VERSION ""

NS_ :

BS_:

BU_: DSAU vHS_M SHVU_RR DPSS AMP ICC RLPSM APSM RWPC RRHV RRPSM CGW_CCU APSS ATS RLHV FPM RDC PSM ASAU

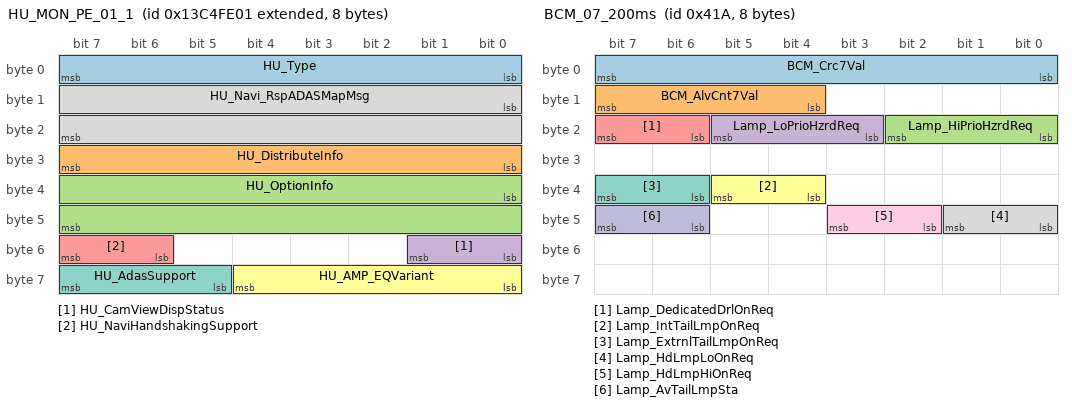
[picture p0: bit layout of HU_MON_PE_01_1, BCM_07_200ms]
BO_ 2479160833 HU_MON_PE_01_1: 8 CGW_CCU
 SG_ HU_Type : 0|8@1+ (1,0) [0|0] ""  AMP
 SG_ HU_DistributeInfo : 24|8@1+ (1,0) [0|0] ""  AMP
 SG_ HU_OptionInfo : 32|16@1+ (1,0) [0|0] ""  AMP
 SG_ HU_CamViewDispStatus : 48|2@1+ (1,0) [0|0] ""  Vector__XXX
 SG_ HU_NaviHandshakingSupport : 54|2@1+ (1,0) [0|0] ""  Vector__XXX
 SG_ HU_AMP_EQVariant : 56|5@1+ (1,0) [0|0] ""  AMP
 SG_ HU_AdasSupport : 61|3@1+ (1,0) [0|0] ""  Vector__XXX
 SG_ HU_Navi_RspADASMapMsg : 8|16@1+ (1,0) [0|0] ""  Vector__XXX

BO_ 2458165761 HU_GW_E_02_1: 8 CGW_CCU
 SG_ C_HazardFromIBOX : 1|1@1+ (1,0) [0|0] ""  Vector__XXX
 SG_ C_RemoteWdwCMDHU : 16|2@1+ (1,0) [0|0] ""  Vector__XXX
 SG_ C_EsyAcsProfileID_HU : 18|2@1+ (1,0) [0|0] ""  PSM
 SG_ C_TeleStrgWhlHeatingCmdIBOX : 20|2@1+ (1,0) [0|0] ""  Vector__XXX
 SG_ C_TeleDefoggerHeatingCmdIBOX : 22|2@1+ (1,0) [0|0] ""  Vector__XXX
 SG_ HU_ICU_RearDefSet : 24|2@1+ (1,0) [0|0] ""  Vector__XXX
 SG_ C_PanicFromIBOX : 3|1@1+ (1,0) [0|0] ""  Vector__XXX
 SG_ C_PreCrankReq : 30|2@1+ (1,0) [0|0] ""  Vector__XXX
 SG_ C_TeleAstSeatOpCmdIBOX : 32|4@1+ (1,0) [0|0] ""  PSM,APSM
 SG_ C_TeleDrvSeatOpCmdIBOX : 36|4@1+ (1,0) [0|0] ""  PSM,APSM
 SG_ C_TeleRRSeatOpCmdIBOX : 40|4@1+ (1,0) [0|0] ""  RLPSM,RRPSM,RLHV,RRHV,SHVU_RR,ATS
 SG_ C_TeleRLSeatOpCmdIBOX : 44|4@1+ (1,0) [0|0] ""  RLPSM,RRPSM,RLHV,RRHV,SHVU_RR,ATS
 SG_ C_HazardFromCCS : 48|2@1+ (1,0) [0|0] ""  Vector__XXX
 SG_ C_CtrlDrUnlockRlyIBOX : 5|1@1+ (1,0) [0|0] ""  Vector__XXX
 SG_ C_PanicFromCCS : 50|2@1+ (1,0) [0|0] ""  Vector__XXX
 SG_ C_CtrlDrUnlockRlyCCS : 52|2@1+ (1,0) [0|0] ""  Vector__XXX
 SG_ C_CtrlDrLockRlyCCS : 54|2@1+ (1,0) [0|0] ""  Vector__XXX
 SG_ C_CtrlDrLockRlyIBOX : 7|1@1+ (1,0) [0|0] ""  Vector__XXX
 SG_ C_TeleHeatingCmdIBOX : 8|2@1+ (1,0) [0|0] ""  Vector__XXX

BO_ 1050 BCM_07_200ms: 8 CGW_CCU
 SG_ BCM_Crc7Val : 0|8@1+ (1,0) [0|0] ""  Vector__XXX
 SG_ BCM_AlvCnt7Val : 12|4@1+ (1,0) [0|0] ""  Vector__XXX
 SG_ Lamp_HiPrioHzrdReq : 16|3@1+ (1,0) [0|0] ""  Vector__XXX
 SG_ Lamp_LoPrioHzrdReq : 19|3@1+ (1,0) [0|0] ""  Vector__XXX
 SG_ Lamp_DedicatedDrlOnReq : 22|2@1+ (1,0) [0|0] ""  Vector__XXX
 SG_ Lamp_IntTailLmpOnReq : 36|2@1+ (1,0) [0|0] ""  RWPC
 SG_ Lamp_ExtrnlTailLmpOnReq : 38|2@1+ (1,0) [0|0] ""  Vector__XXX
 SG_ Lamp_HdLmpLoOnReq : 40|2@1+ (1,0) [0|0] ""  Vector__XXX
 SG_ Lamp_HdLmpHiOnReq : 42|2@1+ (1,0) [0|0] ""  Vector__XXX
 SG_ Lamp_AvTailLmpSta : 46|2@1+ (1,0) [0|0] ""  ATS

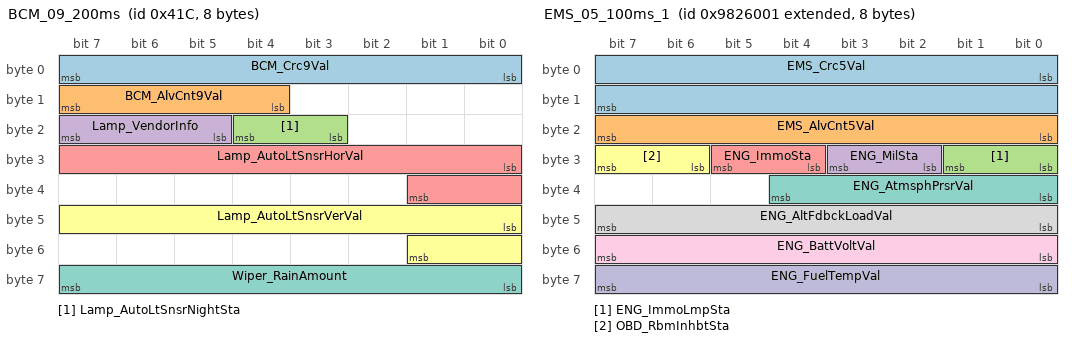
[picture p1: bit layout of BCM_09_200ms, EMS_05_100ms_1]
BO_ 1052 BCM_09_200ms: 8 CGW_CCU
 SG_ BCM_Crc9Val : 0|8@1+ (1,0) [0|0] ""  Vector__XXX
 SG_ BCM_AlvCnt9Val : 12|4@1+ (1,0) [0|0] ""  Vector__XXX
 SG_ Lamp_AutoLtSnsrNightSta : 19|2@1+ (1,0) [0|0] ""  ATS
 SG_ Lamp_VendorInfo : 21|3@1+ (1,0) [0|0] ""  Vector__XXX
 SG_ Lamp_AutoLtSnsrHorVal : 24|10@1+ (1,0) [0|0] ""  ATS
 SG_ Lamp_AutoLtSnsrVerVal : 40|10@1+ (1,0) [0|0] ""  Vector__XXX
 SG_ Wiper_RainAmount : 56|8@1+ (0.5,0) [0|0] ""  Vector__XXX

BO_ 2307022849 EMS_05_100ms_1: 8 CGW_CCU
 SG_ EMS_Crc5Val : 0|16@1+ (1,0) [0|0] ""  Vector__XXX
 SG_ EMS_AlvCnt5Val : 16|8@1+ (1,0) [0|0] ""  Vector__XXX
 SG_ ENG_ImmoLmpSta : 24|2@1+ (1,0) [0|0] ""  Vector__XXX
 SG_ ENG_MilSta : 26|2@1+ (1,0) [0|0] ""  Vector__XXX
 SG_ ENG_ImmoSta : 28|2@1+ (1,0) [0|0] ""  Vector__XXX
 SG_ OBD_RbmInhbtSta : 30|2@1+ (1,0) [0|0] ""  Vector__XXX
 SG_ ENG_AtmsphPrsrVal : 32|5@1+ (10.731613,458.98) [0|0] "mmHg"  Vector__XXX
 SG_ ENG_AltFdbckLoadVal : 40|8@1+ (0.4,0) [0|0] "%"  Vector__XXX
 SG_ ENG_BattVoltVal : 48|8@1+ (0.1015625,0) [0|0] "V"  Vector__XXX
 SG_ ENG_FuelTempVal : 56|8@1+ (0.75,-48) [0|0] "℃"  Vector__XXX

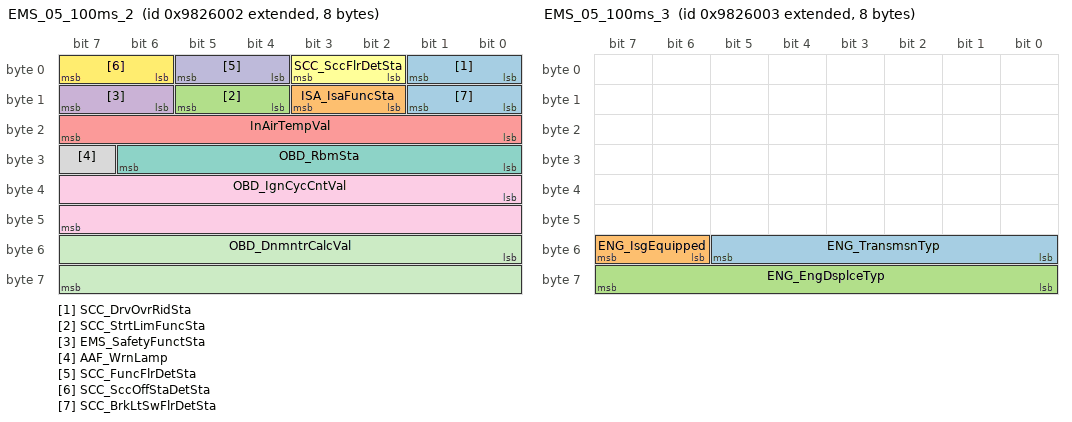
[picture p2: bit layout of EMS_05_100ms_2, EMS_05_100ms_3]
BO_ 2307022850 EMS_05_100ms_2: 8 CGW_CCU
 SG_ SCC_DrvOvrRidSta : 0|2@1+ (1,0) [0|0] ""  Vector__XXX
 SG_ ISA_IsaFuncSta : 10|2@1+ (1,0) [0|0] ""  Vector__XXX
 SG_ SCC_StrtLimFuncSta : 12|2@1+ (1,0) [0|0] ""  Vector__XXX
 SG_ EMS_SafetyFunctSta : 14|2@1+ (1,0) [0|0] ""  Vector__XXX
 SG_ InAirTempVal : 16|8@1+ (0.75,-48) [0|0] "℃"  Vector__XXX
 SG_ SCC_SccFlrDetSta : 2|2@1+ (1,0) [0|0] ""  Vector__XXX
 SG_ OBD_RbmSta : 24|7@1+ (1,0) [0|0] ""  Vector__XXX
 SG_ AAF_WrnLamp : 31|1@1+ (1,0) [0|0] ""  Vector__XXX
 SG_ OBD_IgnCycCntVal : 32|16@1+ (1,0) [0|0] ""  Vector__XXX
 SG_ SCC_FuncFlrDetSta : 4|2@1+ (1,0) [0|0] ""  Vector__XXX
 SG_ OBD_DnmntrCalcVal : 48|16@1+ (1,0) [0|0] ""  Vector__XXX
 SG_ SCC_SccOffStaDetSta : 6|2@1+ (1,0) [0|0] ""  Vector__XXX
 SG_ SCC_BrkLtSwFlrDetSta : 8|2@1+ (1,0) [0|0] ""  Vector__XXX

BO_ 2307022851 EMS_05_100ms_3: 8 CGW_CCU
 SG_ ENG_TransmsnTyp : 48|6@1+ (1,0) [0|0] ""  Vector__XXX
 SG_ ENG_IsgEquipped : 54|2@1+ (1,0) [0|0] ""  Vector__XXX
 SG_ ENG_EngDsplceTyp : 56|8@1+ (0.1,0) [0|0] "liter"  AMP

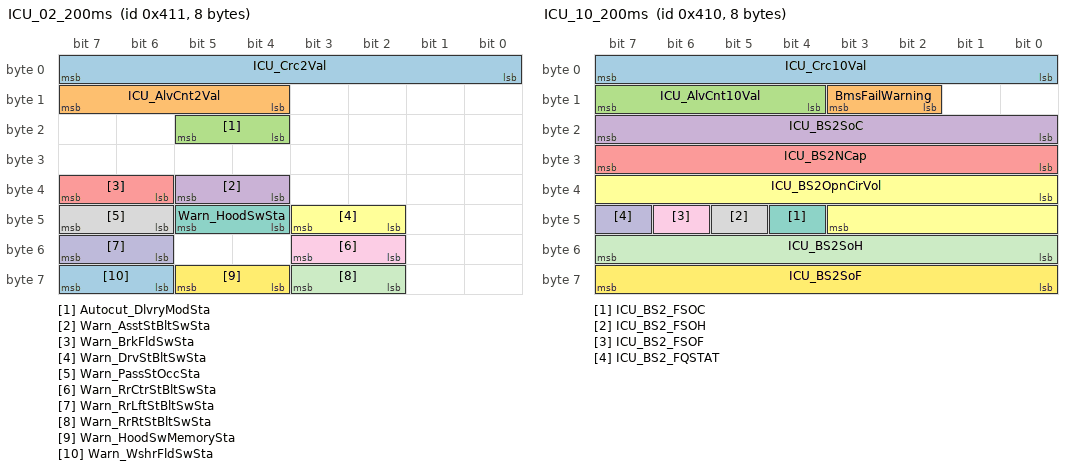
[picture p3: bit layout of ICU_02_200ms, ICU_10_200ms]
BO_ 1041 ICU_02_200ms: 8 CGW_CCU
 SG_ ICU_Crc2Val : 0|8@1+ (1,0) [0|0] ""  vHS_M
 SG_ ICU_AlvCnt2Val : 12|4@1+ (1,0) [0|0] ""  Vector__XXX
 SG_ Autocut_DlvryModSta : 20|2@1+ (1,0) [0|0] ""  Vector__XXX
 SG_ Warn_AsstStBltSwSta : 36|2@1+ (1,0) [0|0] ""  APSM,RLPSM,RRPSM,ASAU
 SG_ Warn_BrkFldSwSta : 38|2@1+ (1,0) [0|0] ""  Vector__XXX
 SG_ Warn_DrvStBltSwSta : 42|2@1+ (1,0) [0|0] ""  ATS,DSAU,ASAU
 SG_ Warn_HoodSwSta : 44|2@1+ (1,0) [0|0] ""  Vector__XXX
 SG_ Warn_PassStOccSta : 46|2@1+ (1,0) [0|0] ""  APSM
 SG_ Warn_RrCtrStBltSwSta : 50|2@1+ (1,0) [0|0] ""  Vector__XXX
 SG_ Warn_RrLftStBltSwSta : 54|2@1+ (1,0) [0|0] ""  RLPSM,RRPSM
 SG_ Warn_RrRtStBltSwSta : 58|2@1+ (1,0) [0|0] ""  RLPSM,RRPSM
 SG_ Warn_HoodSwMemorySta : 60|2@1+ (1,0) [0|0] ""  Vector__XXX
 SG_ Warn_WshrFldSwSta : 62|2@1+ (1,0) [0|0] ""  Vector__XXX

BO_ 1040 ICU_10_200ms: 8 CGW_CCU
 SG_ ICU_Crc10Val : 0|8@1+ (1,0) [0|0] ""  vHS_M
 SG_ BmsFailWarning : 10|2@1+ (1,0) [0|0] ""  Vector__XXX
 SG_ ICU_AlvCnt10Val : 12|4@1+ (1,0) [0|0] ""  Vector__XXX
 SG_ ICU_BS2SoC : 16|8@1+ (1,0) [0|0] ""  AMP
 SG_ ICU_BS2NCap : 24|8@1+ (1,0) [0|0] ""  Vector__XXX
 SG_ ICU_BS2OpnCirVol : 32|12@1+ (0.001,10) [0|0] ""  Vector__XXX
 SG_ ICU_BS2_FSOC : 44|1@1+ (1,0) [0|0] ""  Vector__XXX
 SG_ ICU_BS2_FSOH : 45|1@1+ (1,0) [0|0] ""  Vector__XXX
 SG_ ICU_BS2_FSOF : 46|1@1+ (1,0) [0|0] ""  Vector__XXX
 SG_ ICU_BS2_FQSTAT : 47|1@1+ (1,0) [0|0] ""  Vector__XXX
 SG_ ICU_BS2SoH : 48|8@1+ (1,0) [0|0] ""  Vector__XXX
 SG_ ICU_BS2SoF : 56|8@1+ (0.05,0) [0|0] ""  Vector__XXX

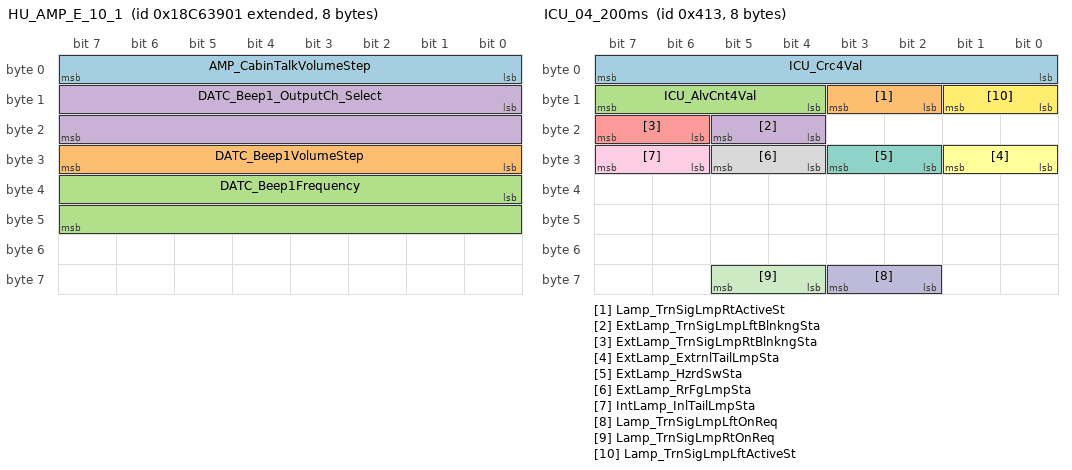
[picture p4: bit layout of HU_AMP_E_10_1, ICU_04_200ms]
BO_ 2563127553 HU_AMP_E_10_1: 8 CGW_CCU
 SG_ AMP_CabinTalkVolumeStep : 0|8@1+ (1,0) [0|0] ""  Vector__XXX
 SG_ DATC_Beep1VolumeStep : 24|8@1+ (1,0) [0|0] ""  AMP
 SG_ DATC_Beep1Frequency : 32|16@1+ (1,0) [0|0] "Hz"  AMP
 SG_ DATC_Beep1_OutputCh_Select : 8|16@1+ (1,0) [0|0] ""  AMP

BO_ 1043 ICU_04_200ms: 8 CGW_CCU
 SG_ ICU_Crc4Val : 0|8@1+ (1,0) [0|0] ""  vHS_M
 SG_ Lamp_TrnSigLmpRtActiveSt : 10|2@1+ (1,0) [0|0] ""  Vector__XXX
 SG_ ICU_AlvCnt4Val : 12|4@1+ (1,0) [0|0] ""  Vector__XXX
 SG_ ExtLamp_TrnSigLmpLftBlnkngSta : 20|2@1+ (1,0) [0|0] ""  Vector__XXX
 SG_ ExtLamp_TrnSigLmpRtBlnkngSta : 22|2@1+ (1,0) [0|0] ""  Vector__XXX
 SG_ ExtLamp_ExtrnlTailLmpSta : 24|2@1+ (1,0) [0|0] ""  Vector__XXX
 SG_ ExtLamp_HzrdSwSta : 26|2@1+ (1,0) [0|0] ""  ICC
 SG_ ExtLamp_RrFgLmpSta : 28|2@1+ (1,0) [0|0] ""  Vector__XXX
 SG_ IntLamp_InlTailLmpSta : 30|2@1+ (1,0) [0|0] ""  Vector__XXX
 SG_ Lamp_TrnSigLmpLftOnReq : 58|2@1+ (1,0) [0|0] ""  Vector__XXX
 SG_ Lamp_TrnSigLmpRtOnReq : 60|2@1+ (1,0) [0|0] ""  Vector__XXX
 SG_ Lamp_TrnSigLmpLftActiveSt : 8|2@1+ (1,0) [0|0] ""  Vector__XXX

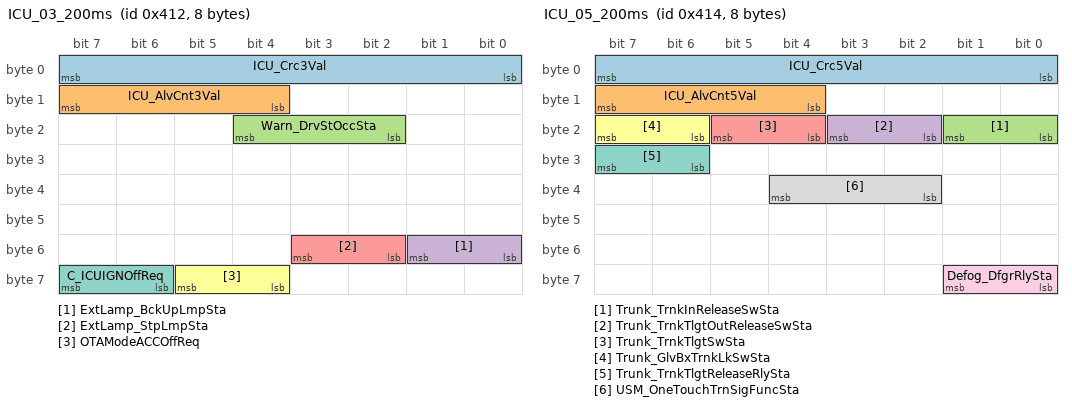
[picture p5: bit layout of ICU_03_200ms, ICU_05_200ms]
BO_ 1042 ICU_03_200ms: 8 CGW_CCU
 SG_ ICU_Crc3Val : 0|8@1+ (1,0) [0|0] ""  vHS_M
 SG_ ICU_AlvCnt3Val : 12|4@1+ (1,0) [0|0] ""  Vector__XXX
 SG_ Warn_DrvStOccSta : 18|3@1+ (1,0) [0|0] ""  Vector__XXX
 SG_ ExtLamp_BckUpLmpSta : 48|2@1+ (1,0) [0|0] ""  Vector__XXX
 SG_ ExtLamp_StpLmpSta : 50|2@1+ (1,0) [0|0] ""  Vector__XXX
 SG_ OTAModeACCOffReq : 60|2@1+ (1,0) [0|0] ""  Vector__XXX
 SG_ C_ICUIGNOffReq : 62|2@1+ (1,0) [0|0] ""  Vector__XXX

BO_ 639 ATS_04_00ms: 8 ATS
 SG_ ATS_RLSeatHeaterUpSW : 10|2@1+ (1,0) [0|0] ""  RLHV,RLPSM,RRHV,RRPSM
 SG_ ATS_RRSeatVentDownSW : 12|2@1+ (1,0) [0|0] ""  RLHV,RLPSM,RRHV,RRPSM
 SG_ ATS_RLSeatVentDownSW : 14|2@1+ (1,0) [0|0] ""  RLHV,RLPSM,RRHV,RRPSM
 SG_ ATS_RLMemoryRestBtn : 16|2@1+ (1,0) [0|0] ""  PSM,RLPSM
 SG_ ATS_RLMemoryReturnBtn : 18|2@1+ (1,0) [0|0] ""  PSM,RLPSM
 SG_ ATS_RRMemoryRestBtn : 20|2@1+ (1,0) [0|0] ""  APSM,RRPSM
 SG_ ATS_RRMemoryReturnBtn : 22|2@1+ (1,0) [0|0] ""  APSM,RRPSM
 SG_ ATS_RRMemoryAvWtcBtn : 24|2@1+ (1,0) [0|0] ""  APSM,RRPSM
 SG_ ATS_RRMemoryReadingBtn : 26|2@1+ (1,0) [0|0] ""  APSM,RRPSM
 SG_ ATS_RRRestModBtnSTD : 32|2@1+ (1,0) [0|0] ""  APSM,RRPSM
 SG_ ATS_RRResetModBtnSTD : 34|2@1+ (1,0) [0|0] ""  APSM,RRPSM
 SG_ ATS_RRAvWtcModBtnSTD : 36|2@1+ (1,0) [0|0] ""  APSM,RRPSM
 SG_ ATS_RRReadingModBtnSTD : 38|2@1+ (1,0) [0|0] ""  APSM,RRPSM,CGW_CCU
 SG_ ATS_RLRestModBtnSTD : 40|2@1+ (1,0) [0|0] ""  PSM,RLPSM
 SG_ ATS_RLResetModBtnSTD : 42|2@1+ (1,0) [0|0] ""  PSM,RLPSM
 SG_ ATS_RRModestateStopBtn : 44|2@1+ (1,0) [0|0] ""  APSM,RRPSM
 SG_ ATS_RLModestateStopBtn : 46|2@1+ (1,0) [0|0] ""  PSM,RLPSM
 SG_ ATS_RLResetRestBtn : 48|2@1+ (1,0) [0|0] ""  PSM,RLPSM
 SG_ ATS_RLResetReturnBtn : 50|2@1+ (1,0) [0|0] ""  PSM,RLPSM
 SG_ ATS_RRResetRestBtn : 52|2@1+ (1,0) [0|0] ""  APSM,RRPSM
 SG_ ATS_RRResetReturnBtn : 54|2@1+ (1,0) [0|0] ""  APSM,RRPSM
 SG_ ATS_RRResetAvWtcBtn : 56|2@1+ (1,0) [0|0] ""  APSM,RRPSM
 SG_ ATS_RRResetReadingBtn : 58|2@1+ (1,0) [0|0] ""  APSM,RRPSM
 SG_ ATS_RRSeatHeaterUpSW : 8|2@1+ (1,0) [0|0] ""  RLHV,RLPSM,RRHV,RRPSM

BO_ 1044 ICU_05_200ms: 8 CGW_CCU
 SG_ ICU_Crc5Val : 0|8@1+ (1,0) [0|0] ""  vHS_M
 SG_ ICU_AlvCnt5Val : 12|4@1+ (1,0) [0|0] ""  Vector__XXX
 SG_ Trunk_TrnkInReleaseSwSta : 16|2@1+ (1,0) [0|0] ""  Vector__XXX
 SG_ Trunk_TrnkTlgtOutReleaseSwSta : 18|2@1+ (1,0) [0|0] ""  Vector__XXX
 SG_ Trunk_TrnkTlgtSwSta : 20|2@1+ (1,0) [0|0] ""  AMP
 SG_ Trunk_GlvBxTrnkLkSwSta : 22|2@1+ (1,0) [0|0] ""  Vector__XXX
 SG_ Trunk_TrnkTlgtReleaseRlySta : 30|2@1+ (1,0) [0|0] ""  Vector__XXX
 SG_ USM_OneTouchTrnSigFuncSta : 34|3@1+ (1,0) [0|0] ""  Vector__XXX
 SG_ Defog_DfgrRlySta : 56|2@1+ (1,0) [0|0] ""  Vector__XXX

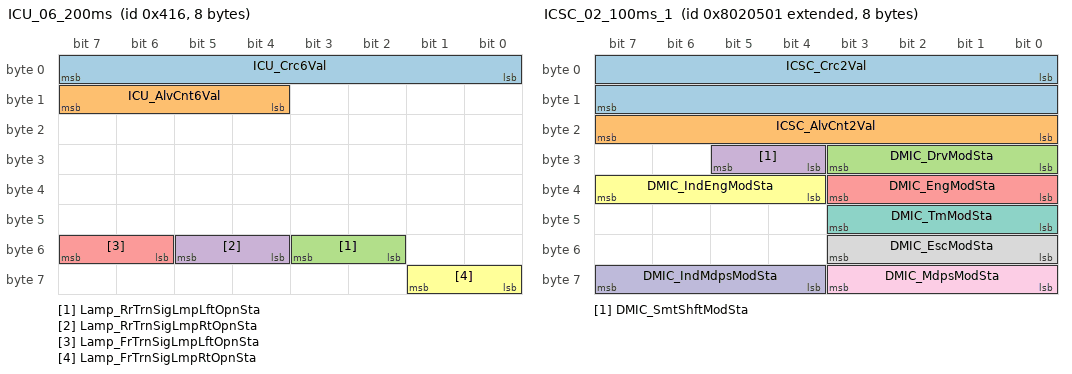
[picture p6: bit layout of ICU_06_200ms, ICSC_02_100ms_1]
BO_ 1046 ICU_06_200ms: 8 CGW_CCU
 SG_ ICU_Crc6Val : 0|8@1+ (1,0) [0|0] ""  vHS_M
 SG_ ICU_AlvCnt6Val : 12|4@1+ (1,0) [0|0] ""  Vector__XXX
 SG_ Lamp_RrTrnSigLmpLftOpnSta : 50|2@1+ (1,0) [0|0] ""  Vector__XXX
 SG_ Lamp_RrTrnSigLmpRtOpnSta : 52|2@1+ (1,0) [0|0] ""  Vector__XXX
 SG_ Lamp_FrTrnSigLmpLftOpnSta : 54|2@1+ (1,0) [0|0] ""  Vector__XXX
 SG_ Lamp_FrTrnSigLmpRtOpnSta : 56|2@1+ (1,0) [0|0] ""  Vector__XXX

BO_ 2281833729 ICSC_02_100ms_1: 8 CGW_CCU
 SG_ ICSC_Crc2Val : 0|16@1+ (1,0) [0|0] ""  Vector__XXX
 SG_ ICSC_AlvCnt2Val : 16|8@1+ (1,0) [0|0] ""  Vector__XXX
 SG_ DMIC_DrvModSta : 24|4@1+ (1,0) [0|0] ""  DSAU,ASAU
 SG_ DMIC_SmtShftModSta : 28|2@1+ (1,0) [0|0] ""  Vector__XXX
 SG_ DMIC_EngModSta : 32|4@1+ (1,0) [0|0] ""  AMP
 SG_ DMIC_IndEngModSta : 36|4@1+ (1,0) [0|0] ""  Vector__XXX
 SG_ DMIC_TmModSta : 40|4@1+ (1,0) [0|0] ""  Vector__XXX
 SG_ DMIC_EscModSta : 48|4@1+ (1,0) [0|0] ""  Vector__XXX
 SG_ DMIC_MdpsModSta : 56|4@1+ (1,0) [0|0] ""  Vector__XXX
 SG_ DMIC_IndMdpsModSta : 60|4@1+ (1,0) [0|0] ""  Vector__XXX

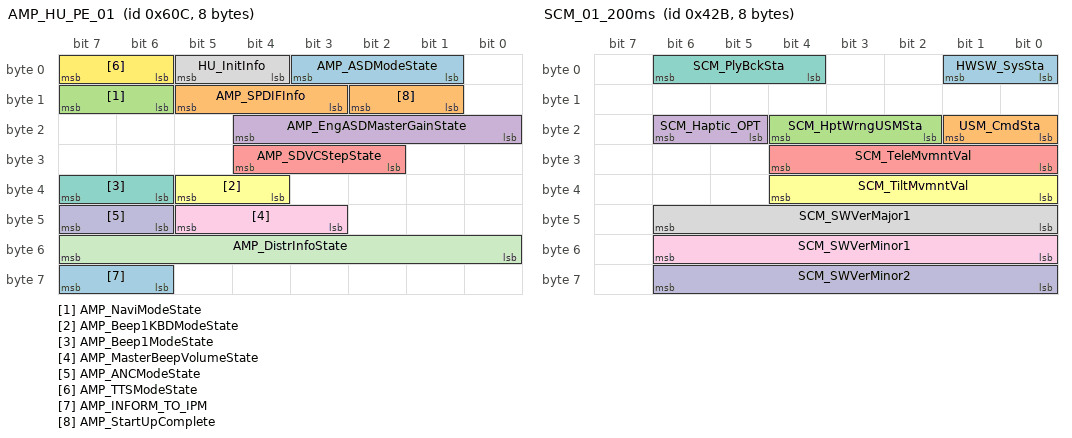
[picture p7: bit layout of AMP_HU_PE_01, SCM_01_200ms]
BO_ 1548 AMP_HU_PE_01: 8 AMP
 SG_ AMP_ASDModeState : 1|3@1+ (1,0) [0|0] ""  CGW_CCU
 SG_ AMP_SPDIFInfo : 11|3@1+ (1,0) [0|0] ""  CGW_CCU
 SG_ AMP_NaviModeState : 14|2@1+ (1,0) [0|0] ""  CGW_CCU
 SG_ AMP_EngASDMasterGainState : 16|5@1+ (0.5,-8) [-6|6] ""  CGW_CCU
 SG_ AMP_SDVCStepState : 26|3@1+ (1,0) [0|0] ""  CGW_CCU
 SG_ AMP_Beep1KBDModeState : 36|2@1+ (1,0) [0|0] ""  CGW_CCU
 SG_ AMP_Beep1ModeState : 38|2@1+ (1,0) [0|0] ""  CGW_CCU
 SG_ HU_InitInfo : 4|2@1+ (1,0) [0|0] ""  CGW_CCU
 SG_ AMP_MasterBeepVolumeState : 43|3@1+ (1,0) [0|0] ""  CGW_CCU
 SG_ AMP_ANCModeState : 46|2@1+ (1,0) [0|0] ""  CGW_CCU
 SG_ AMP_DistrInfoState : 48|8@1+ (1,0) [0|0] ""  CGW_CCU
 SG_ AMP_TTSModeState : 6|2@1+ (1,0) [0|0] ""  CGW_CCU
 SG_ AMP_INFORM_TO_IPM : 62|2@1+ (1,0) [0|0] ""  CGW_CCU
 SG_ AMP_StartUpComplete : 9|2@1+ (1,0) [0|0] ""  CGW_CCU

BO_ 1067 SCM_01_200ms: 8 CGW_CCU
 SG_ HWSW_SysSta : 0|2@1+ (1,0) [0|0] ""  Vector__XXX
 SG_ USM_CmdSta : 16|2@1+ (1,0) [0|0] ""  PSM
 SG_ SCM_HptWrngUSMSta : 18|3@1+ (1,0) [0|0] ""  Vector__XXX
 SG_ SCM_Haptic_OPT : 21|2@1+ (1,0) [0|0] ""  Vector__XXX
 SG_ SCM_TeleMvmntVal : 24|5@1+ (1,0) [0|0] "pulse count"  Vector__XXX
 SG_ SCM_TiltMvmntVal : 32|5@1+ (1,0) [0|0] "pulse count"  Vector__XXX
 SG_ SCM_PlyBckSta : 4|3@1+ (1,0) [0|0] ""  PSM
 SG_ SCM_SWVerMajor1 : 40|7@1+ (1,0) [0|0] ""  Vector__XXX
 SG_ SCM_SWVerMinor1 : 48|7@1+ (1,0) [0|0] ""  Vector__XXX
 SG_ SCM_SWVerMinor2 : 56|7@1+ (1,0) [0|0] ""  Vector__XXX

BO_ 1549 AMP_HU_PE_02: 8 AMP
 SG_ AMP_VirtualVenueModeStatus : 0|3@1+ (1,0) [0|0] ""  CGW_CCU
 SG_ AMP_EQState : 10|2@1+ (1,0) [0|0] ""  CGW_CCU
 SG_ AMP_DriverModeStatus : 12|2@1+ (1,0) [0|0] ""  CGW_CCU
 SG_ AMP_WrnPromptModeSta : 16|2@1+ (1,0) [0|0] ""  CGW_CCU
 SG_ AMP_ESEVwarning : 20|2@1+ (1,0) [0|0] ""  CGW_CCU
 SG_ AMP_SPDIFMuteSt : 22|2@1+ (1,0) [0|0] ""  CGW_CCU
 SG_ AMP_RANCwarning : 24|2@1+ (1,0) [0|0] ""  CGW_CCU
 SG_ AMP_RANCstate : 27|3@1+ (1,0) [0|0] ""  CGW_CCU
 SG_ AMP_QLIModeStatus : 3|3@1+ (1,0) [0|0] ""  CGW_CCU
 SG_ AMP_AudioSource : 32|8@1+ (1,0) [0|0] ""  CGW_CCU
 SG_ AMP_QuietModeState : 40|2@1+ (1,0) [0|0] ""  CGW_CCU
 SG_ AMP_QLSModeState : 44|2@1+ (1,0) [0|0] ""  CGW_CCU
 SG_ AMP_VoiceGuideTTSLevelStatus : 53|3@1+ (1,0) [0|0] ""  CGW_CCU
 SG_ AMP_VoiceGuideTTSStatus : 58|2@1+ (1,0) [0|0] ""  CGW_CCU
 SG_ AMP_MuteState : 6|2@1+ (1,0) [0|0] ""  CGW_CCU
 SG_ AMP_ALTPopUpStatus : 60|2@1+ (1,0) [0|0] ""  CGW_CCU
 SG_ AMP_LogSnapshotState : 8|2@1+ (1,0) [0|0] ""  CGW_CCU

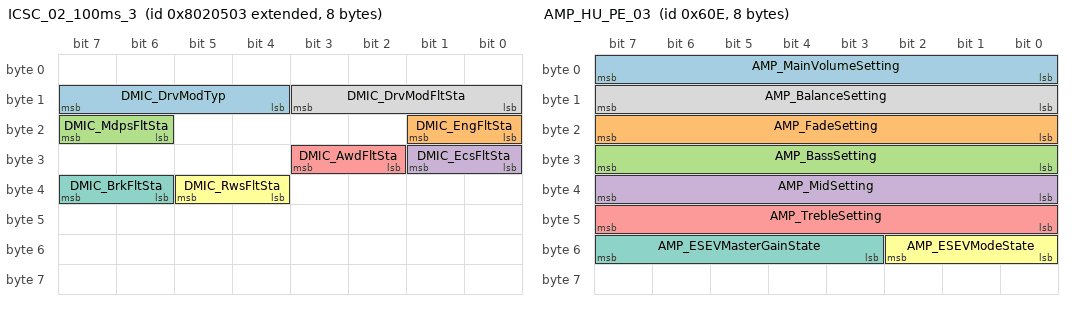
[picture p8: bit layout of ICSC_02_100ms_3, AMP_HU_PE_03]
BO_ 2281833731 ICSC_02_100ms_3: 8 CGW_CCU
 SG_ DMIC_DrvModTyp : 12|4@1+ (1,0) [0|0] ""  Vector__XXX
 SG_ DMIC_EngFltSta : 16|2@1+ (1,0) [0|0] ""  Vector__XXX
 SG_ DMIC_MdpsFltSta : 22|2@1+ (1,0) [0|0] ""  Vector__XXX
 SG_ DMIC_EcsFltSta : 24|2@1+ (1,0) [0|0] ""  Vector__XXX
 SG_ DMIC_AwdFltSta : 26|2@1+ (1,0) [0|0] ""  Vector__XXX
 SG_ DMIC_RwsFltSta : 36|2@1+ (1,0) [0|0] ""  Vector__XXX
 SG_ DMIC_BrkFltSta : 38|2@1+ (1,0) [0|0] ""  Vector__XXX
 SG_ DMIC_DrvModFltSta : 8|4@1+ (1,0) [0|0] ""  Vector__XXX

BO_ 1550 AMP_HU_PE_03: 8 AMP
 SG_ AMP_MainVolumeSetting : 0|8@1+ (1,0) [0|0] ""  CGW_CCU
 SG_ AMP_FadeSetting : 16|8@1+ (1,0) [0|0] ""  CGW_CCU
 SG_ AMP_BassSetting : 24|8@1+ (1,0) [0|0] ""  CGW_CCU
 SG_ AMP_MidSetting : 32|8@1+ (1,0) [0|0] ""  CGW_CCU
 SG_ AMP_TrebleSetting : 40|8@1+ (1,0) [0|0] ""  CGW_CCU
 SG_ AMP_ESEVModeState : 48|3@1+ (1,0) [0|0] ""  CGW_CCU
 SG_ AMP_ESEVMasterGainState : 51|5@1+ (0.5,-8) [0|0] ""  CGW_CCU
 SG_ AMP_BalanceSetting : 8|8@1+ (1,0) [0|0] ""  CGW_CCU

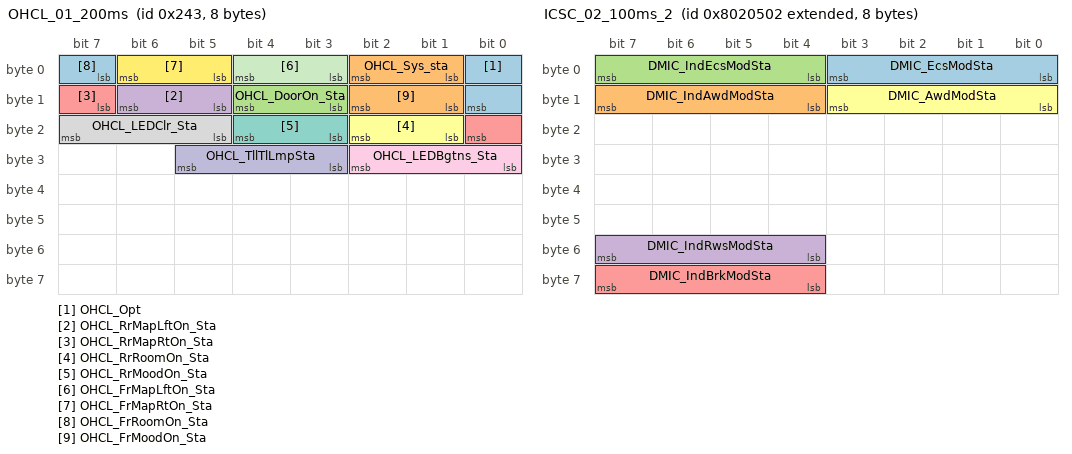
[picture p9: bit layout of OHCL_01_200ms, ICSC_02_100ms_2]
BO_ 579 OHCL_01_200ms: 8 CGW_CCU
 SG_ OHCL_Opt : 0|1@1+ (1,0) [0|0] ""  ATS
 SG_ OHCL_Sys_sta : 1|2@1+ (1,0) [0|0] ""  ATS
 SG_ OHCL_DoorOn_Sta : 11|2@1+ (1,0) [0|0] ""  ATS
 SG_ OHCL_RrMapLftOn_Sta : 13|2@1+ (1,0) [0|0] ""  ATS
 SG_ OHCL_RrMapRtOn_Sta : 15|2@1+ (1,0) [0|0] ""  ATS
 SG_ OHCL_RrRoomOn_Sta : 17|2@1+ (1,0) [0|0] ""  ATS
 SG_ OHCL_RrMoodOn_Sta : 19|2@1+ (1,0) [0|0] ""  ATS
 SG_ OHCL_LEDClr_Sta : 21|3@1+ (1,0) [0|0] ""  ATS
 SG_ OHCL_LEDBgtns_Sta : 24|3@1+ (1,0) [0|0] ""  ATS
 SG_ OHCL_TllTlLmpSta : 27|3@1+ (1,0) [0|0] ""  Vector__XXX
 SG_ OHCL_FrMapLftOn_Sta : 3|2@1+ (1,0) [0|0] ""  ATS
 SG_ OHCL_FrMapRtOn_Sta : 5|2@1+ (1,0) [0|0] ""  ATS
 SG_ OHCL_FrRoomOn_Sta : 7|2@1+ (1,0) [0|0] ""  ATS
 SG_ OHCL_FrMoodOn_Sta : 9|2@1+ (1,0) [0|0] ""  ATS

BO_ 2281833730 ICSC_02_100ms_2: 8 CGW_CCU
 SG_ DMIC_EcsModSta : 0|4@1+ (1,0) [0|0] ""  Vector__XXX
 SG_ DMIC_IndAwdModSta : 12|4@1+ (1,0) [0|0] ""  Vector__XXX
 SG_ DMIC_IndEcsModSta : 4|4@1+ (1,0) [0|0] ""  Vector__XXX
 SG_ DMIC_IndRwsModSta : 52|4@1+ (1,0) [0|0] ""  Vector__XXX
 SG_ DMIC_IndBrkModSta : 60|4@1+ (1,0) [0|0] ""  Vector__XXX
 SG_ DMIC_AwdModSta : 8|4@1+ (1,0) [0|0] ""  Vector__XXX

BO_ 1551 AMP_HU_PE_04: 8 AMP
 SG_ AMP_ADASVolumeState : 56|4@1+ (1,0) [0|0] ""  CGW_CCU

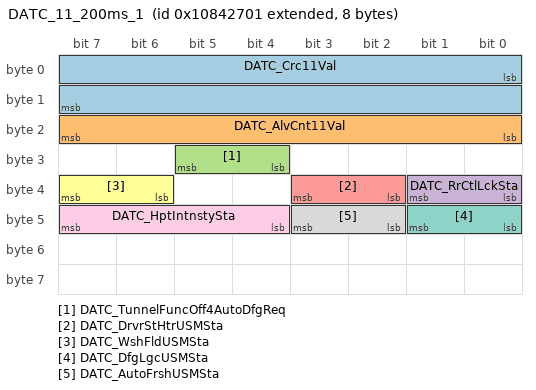
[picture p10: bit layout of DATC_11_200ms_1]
BO_ 2424579841 DATC_11_200ms_1: 8 CGW_CCU
 SG_ DATC_Crc11Val : 0|16@1+ (1,0) [0|0] ""  Vector__XXX
 SG_ DATC_AlvCnt11Val : 16|8@1+ (1,0) [0|0] ""  Vector__XXX
 SG_ DATC_TunnelFuncOff4AutoDfgReq : 28|2@1+ (1,0) [0|0] ""  Vector__XXX
 SG_ DATC_RrCtlLckSta : 32|2@1+ (1,0) [0|0] ""  ATS
 SG_ DATC_DrvrStHtrUSMSta : 34|2@1+ (1,0) [0|0] ""  SHVU_RR
 SG_ DATC_WshFldUSMSta : 38|2@1+ (1,0) [0|0] ""  Vector__XXX
 SG_ DATC_DfgLgcUSMSta : 40|2@1+ (1,0) [0|0] ""  Vector__XXX
 SG_ DATC_AutoFrshUSMSta : 42|2@1+ (1,0) [0|0] ""  Vector__XXX
 SG_ DATC_HptIntnstySta : 44|4@1+ (1,0) [0|0] ""  Vector__XXX

CM_ BO_ 1548 "[PE] Periodic and On Event";
CM_ SG_ 1548 AMP_ASDModeState "Information for current ASD(Active Sound Design, Virtual Engine Sound) Mode status
- Current AMP ASD mode is controlled by Driving Mode by itself";
CM_ SG_ 1548 AMP_SPDIFInfo "Information for SPIF output status
0x1: SPDIF PLL Unlock

0x2: PLL Lock & Null Data Received 

0x3:PLL Lock &  PCM Data Received 

0x4: PLL Lock & Compressed Data Received";
CM_ SG_ 1548 AMP_NaviModeState "Information for Current Navi Prompt Status
-Feedback from AMP_NaviMode(0x008)@H_U";
CM_ SG_ 1548 AMP_EngASDMasterGainState "Information for current ASD(Active Sound Design) Mode Status.";
CM_ SG_ 1548 AMP_SDVCStepState "Information for current SDVC(Advanced VSC) mode state";
CM_ SG_ 1548 AMP_Beep1KBDModeState "Information for Current keyboard Beep1Mode Status-Feedback from AMP_Beep1KBDMode@H_U";
CM_ SG_ 1548 AMP_Beep1ModeState "Information for Current Beep1 Mode Status(Touch Beep Mode)
For Harman AMP Only
-Feedback from AMP_Beep1Mode(0x008)@H_U";
CM_ SG_ 1548 HU_InitInfo "Information for External AMP Initiation status

0x1 : Request AMP Initialization

0x2 : AMP Initialization complted";
CM_ SG_ 1548 AMP_ANCModeState "Current ANC Mode State";
CM_ SG_ 1548 AMP_DistrInfoState "Information for current status of Region : Europe/North America/..
and Driver Position : RHD/LHD Positionning 
Feedback from HU_DistributeInfo@0x100";
CM_ SG_ 1548 AMP_TTSModeState "Information for Current TTS Prompt Status-Feedback from AMP_TTSSound(0x630)@H_U";
CM_ SG_ 1548 AMP_INFORM_TO_IPM "Information for Warning Sound Supportable for CLU";
CM_ SG_ 1548 AMP_StartUpComplete "the signal for informing intitial complete of external AMP

need for generating warning sound using external AMP";
CM_ BO_ 1549 "[PE] Periodic and On Event";
CM_ SG_ 1549 AMP_EQState "Information for current EQ loading and active state check
Harman AMP Only";
CM_ SG_ 1549 AMP_ESEVwarning "ESEV warning(Knock sensor disconnect)  at cluster and HU";
CM_ SG_ 1549 AMP_SPDIFMuteSt "Information for current SPDIF Mute state";
CM_ SG_ 1549 AMP_RANCwarning "RANC Warning at cluster & HU";
CM_ SG_ 1549 AMP_RANCstate "Information for current RANC(road active noise control) on/off status
RANC On : Window/Sunroof/Trunk/Door is close when RANC status is 'ON'
RANC Off : Window/Sunroof/Trunk/Door is close when RANC status is 'OFF'
RANC Off2 : Window/Sunroof/Trunk/Door is open when RANC status is 'ON'
RANC Off3 : Window/Sunroof/Trunk/Door is open when RANC status is 'OFF'";
CM_ SG_ 1549 AMP_AudioSource "Information for Current HF Call Audio Mode Status
-Feedback from AMP_AudioMode(0x009)@H_U";
CM_ SG_ 1549 AMP_QuietModeState "Send signal 'Quiet Mode Status' from AMP to H/U";
CM_ SG_ 1549 AMP_QLSModeState "Information for current QLS(Quantum Logic Surround) mode ON/OFF state
Harman AMP Only
For Mobis KRELL Amp, Use AMP_LiveDynamicModeState instead 
For Mobis Legacy AMP, Use AMP_SurroundModeState";
CM_ SG_ 1549 AMP_MuteState "Information for current mute state";
CM_ SG_ 1549 AMP_LogSnapshotState "Feedback for Log Snapshot touch in ENG Mode (AMP)";
CM_ BO_ 1550 "[PE] Periodic and On Event";
CM_ SG_ 1550 AMP_MainVolumeSetting "Current main audio volume setting status";
CM_ SG_ 1550 AMP_FadeSetting "Current Front/Rear audio Fader Setting status";
CM_ SG_ 1550 AMP_BassSetting "Current bass tone control setting status";
CM_ SG_ 1550 AMP_MidSetting "current midrange tone control setting status";
CM_ SG_ 1550 AMP_TrebleSetting "Current treble tone control setting status";
CM_ SG_ 1550 AMP_ESEVModeState "Feedback for ESEV Set Mode Value";
CM_ SG_ 1550 AMP_ESEVMasterGainState "Information for current ESEV(Engine Sound by Engine Vibration) Mode status.";
CM_ SG_ 1550 AMP_BalanceSetting "Current Left/Right Audio balance setting status";
CM_ BO_ 1551 "[PE] Periodic and On Event";
CM_ BO_ 639 "[EC] On Event and On Change";
CM_ SG_ 639 ATS_RLSeatHeaterUpSW "ATS touch command for seat heat control  (For Rear Left seat)";
CM_ SG_ 639 ATS_RRSeatVentDownSW "ATS touch command for seat Vent control (For Rear Right seat)";
CM_ SG_ 639 ATS_RLSeatVentDownSW "ATS touch command for seat Vent control (For Rear Left seat)";
CM_ SG_ 639 ATS_RLMemoryRestBtn "Rear Left Rest Mode Custom Save Button (Except North America)";
CM_ SG_ 639 ATS_RLMemoryReturnBtn "Rear Left Return Mode Custom Save Button (Except North America)";
CM_ SG_ 639 ATS_RRMemoryRestBtn "Rear Right Rest Mode Custom Save Button (Except North America)";
CM_ SG_ 639 ATS_RRMemoryReturnBtn "Rear Right Return Mode Custom Save Button (Except North America)";
CM_ SG_ 639 ATS_RRMemoryAvWtcBtn "Rear Right AV Watching Mode Custom Save Button (Except North America)";
CM_ SG_ 639 ATS_RRMemoryReadingBtn "Rear Right Reading Mode Custom Save Button (Except North America)";
CM_ SG_ 639 ATS_RRRestModBtnSTD "Rear Right Rest Mode Touch Button (EXCEPT North America)";
CM_ SG_ 639 ATS_RRResetModBtnSTD "Rear Right Return Mode Touch Button (EXCEPT North America)";
CM_ SG_ 639 ATS_RRAvWtcModBtnSTD "Rear Right AV Watching Mode Touch Button (EXCEPT North America)";
CM_ SG_ 639 ATS_RRReadingModBtnSTD "Rear Right Reading Mode Touch Button (EXCEPT North America)";
CM_ SG_ 639 ATS_RLRestModBtnSTD "Rear Left Rest Mode Touch Button (EXCEPT North America)";
CM_ SG_ 639 ATS_RLResetModBtnSTD "Rear Left Return Mode Touch Button (EXCEPT North America)";
CM_ SG_ 639 ATS_RRModestateStopBtn "Rear Right One touch mode Stop Button";
CM_ SG_ 639 ATS_RLModestateStopBtn "Rear Left One touch mode Stop Button";
CM_ SG_ 639 ATS_RLResetRestBtn "Rear Left Rest Mode Custom Initialization Button (Except North America)";
CM_ SG_ 639 ATS_RLResetReturnBtn "Rear Left Return Mode Custom Initialization Button (Except North America)";
CM_ SG_ 639 ATS_RRResetRestBtn "Rear Right Rest Mode Custom Initialization Button (Except North America)";
CM_ SG_ 639 ATS_RRResetReturnBtn "Rear Right Return Mode Custom Initialization Button (Except North America)";
CM_ SG_ 639 ATS_RRResetAvWtcBtn "Rear Right AV Watching Mode Custom Initialization Button (Except North America)";
CM_ SG_ 639 ATS_RRResetReadingBtn "Rear Right Reading Mode Custom Initialization Button (Except North America)";
CM_ SG_ 639 ATS_RRSeatHeaterUpSW "ATS touch command for seat heat control  (For Rear Right seat)";
CM_ BO_ 1050 "[PE] Periodic and On Event";
CM_ SG_ 1050 BCM_Crc7Val "BCM_CyclicRedundancyCheck7Value";
CM_ SG_ 1050 BCM_AlvCnt7Val "BCM_AliveCounter7Value";
CM_ SG_ 1050 Lamp_HiPrioHzrdReq "Lamp_HighPriorityHazardRequest ##2G##BCM - BCMmsg19 - C_HazardFromBCMHigh";
CM_ SG_ 1050 Lamp_LoPrioHzrdReq "Lamp_LowPriorityHazardStatus ##2G##BCM - BCMmsg19 - C_HazardfromBCMLow";
CM_ SG_ 1050 Lamp_DedicatedDrlOnReq "Lamp_DedicatedDrlOnRequest ##2G##BCM - BCMmsg19 - C_DedicatedDRLOn";
CM_ SG_ 1050 Lamp_IntTailLmpOnReq "Lamp_InternalTailLampOnRequest ##2G##BCM - BCMmsg19 - C_IntTailOn";
CM_ SG_ 1050 Lamp_ExtrnlTailLmpOnReq "Lamp_ExternalTailLampOnRequest ##2G##BCM - BCMmsg19 - C_ExtTailOn";
CM_ SG_ 1050 Lamp_HdLmpLoOnReq "Lamp_HeadLampLowOnRequest ##2G##BCM - BCMmsg19 - C_HLpLowOn";
CM_ SG_ 1050 Lamp_HdLmpHiOnReq "Lamp_HeadLampHighOnRequest ##2G##BCM - BCMmsg19 - C_HLpHighOn";
CM_ SG_ 1050 Lamp_AvTailLmpSta "Lamp_AvTailLampStatus ##2G##BCM - BCMmsg18 - C_AvTail";
CM_ BO_ 1052 "[PE] Periodic and On Event";
CM_ SG_ 1052 BCM_Crc9Val "BCM_CyclicRedundancyCheck9Value";
CM_ SG_ 1052 BCM_AlvCnt9Val "BCM_AliveCounter9Value";
CM_ SG_ 1052 Lamp_AutoLtSnsrNightSta "Lamp_AutoLightSensorNightStatus ##2G##BCM - BCMmsg24 - C_AutolightValue";
CM_ SG_ 1052 Lamp_AutoLtSnsrHorVal "Lamp_AutoLightSensorHorValue ##2G##BCM - BCMmsg24 - C_AutolightSensorHorState";
CM_ SG_ 1052 Lamp_AutoLtSnsrVerVal "Lamp_AutoLightSensorVerValue ##2G##BCM - BCMmsg24 - C_AutolightSensorVerState";
CM_ BO_ 2424579841 "[PE] Periodic and On Event";
CM_ SG_ 2424579841 DATC_Crc11Val "DATC_CyclicRedundancyCheck11Value";
CM_ SG_ 2424579841 DATC_AlvCnt11Val "DATC_AliveCounter11Value";
CM_ SG_ 2424579841 DATC_TunnelFuncOff4AutoDfgReq "DATC_TunnelFunctionOffForAutoDefogRequest";
CM_ SG_ 2424579841 DATC_RrCtlLckSta "Datc_RearClimateControlLockStatus";
CM_ SG_ 2424579841 DATC_DrvrStHtrUSMSta "DATC_DriverSeatHeaterUSMStatus";
CM_ SG_ 2424579841 DATC_WshFldUSMSta "DATC_WasherFulidUSMState";
CM_ SG_ 2424579841 DATC_DfgLgcUSMSta "DefLogic USM State";
CM_ SG_ 2424579841 DATC_AutoFrshUSMSta "Auto Fresh USM State";
CM_ SG_ 2424579841 DATC_HptIntnstySta "Haptic Intensity State";
CM_ BO_ 2307022849 "[P] Periodic";
CM_ SG_ 2307022849 EMS_Crc5Val "EMS_CyclicRedundancyCheck5Value";
CM_ SG_ 2307022849 EMS_AlvCnt5Val "EMS_AliveCounter5Value";
CM_ SG_ 2307022849 ENG_ImmoLmpSta "ENG_ImmobilizerLampStatus ##2G##EMS - EMS14 - IMMO_LAMP_STAT";
CM_ SG_ 2307022849 ENG_MilSta "ENG_MalfunctionIndicationLampStatus ##2G##EMS - EMS14 - L_MIL";
CM_ SG_ 2307022849 ENG_ImmoSta "ENG_ImmobilizerStatus ##2G##EMS - EMS14 - IM_STAT";
CM_ SG_ 2307022849 OBD_RbmInhbtSta "OBD_RateBasedMonitoringInhibitionStatus ##2G##EMS - EMS15 - INH_DC_OBD";
CM_ SG_ 2307022849 ENG_AtmsphPrsrVal "ENG_AtmosphericPressureValue ##2G##EMS - EMS14 - AMP_CAN";
CM_ SG_ 2307022849 ENG_AltFdbckLoadVal "ENG_AlternatorFeedbackLoadValue ##2G##EMS - EMS14 - BAT_Alt_FR_Duty";
CM_ SG_ 2307022849 ENG_BattVoltVal "ENG_BatteryVoltageValue ##2G##EMS - EMS14 - VB";
CM_ SG_ 2307022849 ENG_FuelTempVal "ENG_FuelTemperatureValue ##2G##EMS - EMS14 - TEMP_FUEL";
CM_ BO_ 2307022850 "[P] Periodic";
CM_ SG_ 2307022850 SCC_DrvOvrRidSta "SCC_DriverOverRideStatus ##2G##EMS - EMS15 - ECGPOvrd";
CM_ SG_ 2307022850 ISA_IsaFuncSta "ISA_IntelligentSpeedAssistanceFunctionStatus ##2G##EMS - EMS15 - CF_Ems_IsaAct";
CM_ SG_ 2307022850 SCC_StrtLimFuncSta "SCC_StartLimitFunctionStatus ##2G##EMS - EMS15 - CF_EMS_Start_Limitation";
CM_ SG_ 2307022850 EMS_SafetyFunctSta "SCC_SafetyFunctionStatus ##2G##EMS - EMS15 - CF_EMS_SAFETY_FUNCTION";
CM_ SG_ 2307022850 InAirTempVal "SCC_IntakeAirTemperatureValue ##2G##EMS - EMS15 - IntAirTemp";
CM_ SG_ 2307022850 SCC_SccFlrDetSta "SCC_SccFailureDetectStatus ##2G##EMS - EMS15 - QECACC";
CM_ SG_ 2307022850 OBD_RbmSta "OBD_RateBasedMonitoringStatus ##2G##EMS - EMS15 - STATE_DC_OBD";
CM_ SG_ 2307022850 OBD_IgnCycCntVal "OBD_IgnitionCycleCounterValue ##2G##EMS - EMS15 - CTR_IG_CYC_OBD";
CM_ SG_ 2307022850 SCC_FuncFlrDetSta "SCC_FunctionFailureDetectStatus ##2G##EMS - EMS15 - ECFail";
CM_ SG_ 2307022850 OBD_DnmntrCalcVal "OBD_DenominatorCalculationValue ##2G##EMS - EMS15 - CTR_CDN_OBD";
CM_ SG_ 2307022850 SCC_SccOffStaDetSta "SCC_SccOffConditionDetectStatus ##2G##EMS - EMS15 - SwitchOffCondExt";
CM_ SG_ 2307022850 SCC_BrkLtSwFlrDetSta "SCC_BrakeLightSwFailureDetectStatus ##2G##EMS - EMS15 - BLECFail";
CM_ BO_ 2307022851 "[P] Periodic";
CM_ SG_ 2307022851 ENG_TransmsnTyp "ENG_TransmissionType";
CM_ SG_ 2307022851 ENG_IsgEquipped "Information if ISG is equipped or not";
CM_ SG_ 2307022851 ENG_EngDsplceTyp "ENG_EngineDisplacementType ##2G##EMS - EMS12 - ENG_VOL";
CM_ BO_ 2563127553 "[EC] On Event and On Change";
CM_ SG_ 2563127553 AMP_CabinTalkVolumeStep "Command for CabinTalk Prompt Volume Setting
-range : 0 ~ max
-max : value of AMP_MaxCabinTalkVolumeState(0x086)
-This Signal's Feedback is AMP_CabinTalkVolumeState(0x086)@AMP";
CM_ BO_ 2458165761 "[EC] On Event and On Change";
CM_ SG_ 2458165761 C_HazardFromIBOX "Command for Remote Hazard (* Use C_HazardFromCCS signal after KA4, excluding MY change)";
CM_ SG_ 2458165761 C_RemoteWdwCMDHU "Signal for control window (TMS), HI only";
CM_ SG_ 2458165761 C_EsyAcsProfileID_HU "This signal indicates the current detected profile ID by smartphone APP.
(The drv seat move to the easy access position of the detected profile ID when receive the signal)";
CM_ SG_ 2458165761 C_TeleStrgWhlHeatingCmdIBOX "'Command for Remote Heating
(Steering Wheel)";
CM_ SG_ 2458165761 C_TeleDefoggerHeatingCmdIBOX "'Command for Remote Heating
(Rear Window, Side Mirror)";
CM_ SG_ 2458165761 HU_ICU_RearDefSet "Rear window defog control";
CM_ SG_ 2458165761 C_PanicFromIBOX "Command for Remote Panic (Only for USA) (* Use C_PanicFromCCS signal after KA4, excluding MY change)";
CM_ SG_ 2458165761 C_PreCrankReq "Command for B-CAN wake up signal
(Need to send this signal before other remote commands)";
CM_ SG_ 2458165761 C_TeleAstSeatOpCmdIBOX "Command for Remote Seat Heat/Vent control (Passenger)";
CM_ SG_ 2458165761 C_TeleDrvSeatOpCmdIBOX "Command for Remote Seat Heat/Vent control (Driver)";
CM_ SG_ 2458165761 C_TeleRRSeatOpCmdIBOX "Command for Remote Seat Heat/Vent control (Rear Right)";
CM_ SG_ 2458165761 C_TeleRLSeatOpCmdIBOX "Command for Remote Seat Heat/Vent control (Rear Left)";
CM_ SG_ 2458165761 C_HazardFromCCS "Command for Remote Hazard";
CM_ SG_ 2458165761 C_CtrlDrUnlockRlyIBOX "Command for Remote Door UnLock (* Use C_CtrlDrUnlcokRlyFromCCS signal after KA4, excluding MY change)";
CM_ SG_ 2458165761 C_PanicFromCCS "Command for Remote Panic (Only for USA)";
CM_ SG_ 2458165761 C_CtrlDrUnlockRlyCCS "Command for Remote Door UnLock";
CM_ SG_ 2458165761 C_CtrlDrLockRlyCCS "Command for Remote Door Lock";
CM_ SG_ 2458165761 C_CtrlDrLockRlyIBOX "Command for Remote Door Lock (* Use C_CtrlDrLockRlyFromCCS signal after KA4, excluding MY change)";
CM_ SG_ 2458165761 C_TeleHeatingCmdIBOX "'Command for Remote Heating

(Steering Wheel, Rear Window, Side Mirror)";
CM_ BO_ 2479160833 "[PE] Periodic and On Event";
CM_ SG_ 2479160833 HU_Type "Information for H/U Platform type
- Integrated AVN 1.0 use different value depends on development company (Mobis:0x68/LG:0x70)
- Integrated AVN 1.0 Mobis is developed based on Display Audio
- Integrated AVN 1.0 LG is developed based on Compact AVN

Information for China OPIO Platform
- 0xFC: China OPIO w/o CLU interface (most of phase1)
- 0xFD: China OPIO w/CLU interface (parts of phase1, phase2)

Information for Audio Platform Type
- 0x43 : Audio 4.0 Value";
CM_ SG_ 2479160833 HU_DistributeInfo "Region :Europe/North America/
Vehicle Type : RHD/LHD
Positionning information";
CM_ SG_ 2479160833 HU_OptionInfo "Information of H/U functions";
CM_ SG_ 2479160833 HU_NaviHandshakingSupport "This is a signal to send whether handshaking logic is applied related to Navigation's 'Map based ADAS' specification";
CM_ SG_ 2479160833 HU_AMP_EQVariant "Set EQ Variant for various vehicle cases.
During the AMP initializing process, This signal should be sent before AMP unmute.
This signal is only needed for models that have variant EQ for vehicle types. (Hatchback, Wagon, Hybrid etc..)
Models that doesn’t have variant EQ for vehicle types shouldn’t have this signal.";
CM_ SG_ 2479160833 HU_AdasSupport "Information about ADAS support
-Classify between General Map and Precise Map Transmission Function
-AVN System Transmission Signal";
CM_ SG_ 2479160833 HU_Navi_RspADASMapMsg "HU_ResponseADASMapMessage";
CM_ BO_ 2281833729 "[P] Periodic";
CM_ SG_ 2281833729 ICSC_Crc2Val "ICSC_CyclicRedundancyCheck2Value";
CM_ SG_ 2281833729 ICSC_AlvCnt2Val "ICSC_AliveCounter2Value";
CM_ SG_ 2281833729 DMIC_DrvModSta "DMIC_DriveModeStatus ##2G##ICSC - IVSS11 - DrivingModeState";
CM_ SG_ 2281833729 DMIC_SmtShftModSta "DMIC_SmartShiftModeStatus ##2G##ICSC - IVSS11 - SMART_SHIFT_MODE";
CM_ SG_ 2281833729 DMIC_EngModSta "DMIC_EngineModeStatus ##2G##ICSC - IVSS11 - MODE_ENG";
CM_ SG_ 2281833729 DMIC_IndEngModSta "DMIC_IndividualEngineModeStatus ##2G##ICSC - IVSS11 - MODE_PT_IND";
CM_ SG_ 2281833729 DMIC_TmModSta "DMIC_TmModeStatus ##2G##ICSC - IVSS11 - MODE_TM";
CM_ SG_ 2281833729 DMIC_EscModSta "DMIC_EscModeStatus ##2G##ICSC - IVSS11 - MODE_ESC";
CM_ SG_ 2281833729 DMIC_MdpsModSta "DMIC_MdpsModeStatus ##2G##ICSC - IVSS11 - MODE_MDPS";
CM_ SG_ 2281833729 DMIC_IndMdpsModSta "DMIC_IndividualMdpsModeStatus ##2G##ICSC - IVSS11 - MODE_MDPS_IND";
CM_ BO_ 2281833730 "[P] Periodic";
CM_ SG_ 2281833730 DMIC_EcsModSta "DMIC_EcsModeStatus ##2G##ICSC - IVSS11 - MODE_ECS";
CM_ SG_ 2281833730 DMIC_IndAwdModSta "DMIC_IndividualAwdModeStatus ##2G##ICSC - IVSS11 - MODE_4WD_IND";
CM_ SG_ 2281833730 DMIC_IndEcsModSta "DMIC_IndividualEcsModeStatus ##2G##ICSC - IVSS11 - MODE_ECS_IND";
CM_ SG_ 2281833730 DMIC_IndRwsModSta "DMIC_IndividualRwsModeStatus";
CM_ SG_ 2281833730 DMIC_IndBrkModSta "DMIC_IndividualFlexBrakeModeStatus";
CM_ SG_ 2281833730 DMIC_AwdModSta "DMIC_AwdModeStatus ##2G##ICSC - IVSS11 - MODE_4WD";
CM_ BO_ 2281833731 "[P] Periodic";
CM_ SG_ 2281833731 DMIC_DrvModTyp "DMIC_DriveModeType ##2G##ICSC - IVSS11 - DRIVE_MODE_TYPE";
CM_ SG_ 2281833731 DMIC_EngFltSta "DMIC_EngineFaultStatus ##2G##ICSC - IVSS11 - MODE_ENG_FltStat";
CM_ SG_ 2281833731 DMIC_MdpsFltSta "DMIC_MdpsFaultStatus ##2G##ICSC - IVSS11 - MODE_MDPS_FltStat";
CM_ SG_ 2281833731 DMIC_EcsFltSta "DMIC_EcsFltSta ##2G##ICSC - IVSS11 - MODE_ECS_FltStat";
CM_ SG_ 2281833731 DMIC_AwdFltSta "DMIC_AwdFaultStatus ##2G##ICSC - IVSS11 - MODE_4WD_FltStat";
CM_ SG_ 2281833731 DMIC_RwsFltSta "DMIC_RwsFaultStatus";
CM_ SG_ 2281833731 DMIC_BrkFltSta "DMIC_BrkFltSta";
CM_ SG_ 2281833731 DMIC_DrvModFltSta "DMIC_DriveModeFaultStatus ##2G##ICSC - IVSS11 - MODE_DRIVING_FltStat";
CM_ BO_ 1041 "[PE] Periodic and On Event";
CM_ SG_ 1041 ICU_Crc2Val "ICU_CyclicRedundancyCheck2Value";
CM_ SG_ 1041 ICU_AlvCnt2Val "ICU_AliveCounter2Value";
CM_ SG_ 1041 Autocut_DlvryModSta "Autocut_DeliveryModeStatus ##2G## -  - C_SJBDeliveryMode,CF_Gway_SJBDeliveryMode";
CM_ SG_ 1041 Warn_AsstStBltSwSta "Warn_AssistSeatBeltSwitchStatus ##2G## -  - C_AstSeatBeltSw,CF_Gway_AstSeatBeltSw";
CM_ SG_ 1041 Warn_BrkFldSwSta "Warn_BrakeFluidSwitchStatus ##2G## -  - C_BrakeFluidSw,CF_Gway_BrakeFluidSw";
CM_ SG_ 1041 Warn_DrvStBltSwSta "Warn_DriverSeatbeltSwitchStatus ##2G## -  - C_DrvSeatBeltSw,CF_Gway_DrvSeatBeltSw";
CM_ SG_ 1041 Warn_HoodSwSta "Warn_HoodSwitchStatus ##2G## -  - C_HoodSw,CF_Gway_HoodSw";
CM_ SG_ 1041 Warn_PassStOccSta "Warn_PassengerSeatOccupyStatus ##2G## -  - C_SBRMatSw";
CM_ SG_ 1041 Warn_RrCtrStBltSwSta "Warn_RearCenterSeatBeltSwitchStatus ##2G## -  - C_RCSeatBeltSw";
CM_ SG_ 1041 Warn_RrLftStBltSwSta "Warn_RearLeftSeatBeltSwitchStatus ##2G## -  - C_RLSeatBeltSw";
CM_ SG_ 1041 Warn_RrRtStBltSwSta "Warn_RearRightSeatBeltSwitchStatus ##2G## -  - C_RRSeatBeltSw";
CM_ SG_ 1041 Warn_HoodSwMemorySta "Warn_HoodSwitchMemoryStatus ##2G## -  - CF_Hoodsw_memory,C_HoodSwMemory";
CM_ SG_ 1041 Warn_WshrFldSwSta "Washer Fluid Switch Signal ##2G## -  - CF_Gway_WasherFluidSw";
CM_ BO_ 1042 "[PE] Periodic and On Event";
CM_ SG_ 1042 ICU_Crc3Val "ICU_CyclicRedundancyCheck3Value";
CM_ SG_ 1042 ICU_AlvCnt3Val "ICU_AliveCounter3Value";
CM_ SG_ 1042 ExtLamp_BckUpLmpSta "This signal is used for control the Back-up Lamp function.";
CM_ SG_ 1042 OTAModeACCOffReq "ACC off request during OTA mode for battery saver";
CM_ SG_ 1042 C_ICUIGNOffReq "IGN off request(Not engine running state only) for battery saver";
CM_ BO_ 1043 "[PE] Periodic and On Event";
CM_ SG_ 1043 ICU_Crc4Val "ICU_CyclicRedundancyCheck4Value";
CM_ SG_ 1043 Lamp_TrnSigLmpRtActiveSt "Lamp_TurnSignalLampRightActiveState";
CM_ SG_ 1043 ICU_AlvCnt4Val "ICU_AliveCounter4Value";
CM_ SG_ 1043 ExtLamp_TrnSigLmpLftBlnkngSta "ExtLamp_TurnSignalLampLeftBlinkingStatus ##2G## -  - CF_Gway_TurnSigLh,C_TSigLhAct";
CM_ SG_ 1043 ExtLamp_TrnSigLmpRtBlnkngSta "ExtLamp_TurnSignalLampRightBlinkingStatus ##2G## -  - CF_Gway_TurnSigRh,C_TSigRhAct";
CM_ SG_ 1043 ExtLamp_ExtrnlTailLmpSta "ExtLamp_ExternalTailLampStatus ##2G## -  - C_ExtTailAct,CF_Gway_ExtTailAct";
CM_ SG_ 1043 ExtLamp_HzrdSwSta "ExtLamp_HazardSwitchStatus ##2G## -  - C_HazardSw,CF_Gway_HazardSw";
CM_ SG_ 1043 ExtLamp_RrFgLmpSta "ExtLamp_RearFogLampStatus ##2G## -  - C_RearFogAct,CF_Gway_RearFogAct";
CM_ SG_ 1043 IntLamp_InlTailLmpSta "IntLamp_InternalTailLampStatus ##2G## -  - C_IntTailAct,CF_Gway_IntTailAct";
CM_ SG_ 1043 Lamp_TrnSigLmpLftOnReq "Lamp_TurnSignalLampLeftOnRequest ##2G## -  - Lamp_TsigLmpFrtLftOnReq";
CM_ SG_ 1043 Lamp_TrnSigLmpRtOnReq "Lamp_TurnSignalLampRightOnRequest ##2G## -  - Lamp_TSigLmpRtLftOnReq";
CM_ SG_ 1043 Lamp_TrnSigLmpLftActiveSt "Lamp_TurnSignalLampLeftActiveState";
CM_ BO_ 1044 "[PE] Periodic and On Event";
CM_ SG_ 1044 ICU_Crc5Val "ICU_CyclicRedundancyCheck5Value";
CM_ SG_ 1044 ICU_AlvCnt5Val "ICU_AliveCounter5Value";
CM_ SG_ 1044 Trunk_TrnkInReleaseSwSta "Trunk_TrunkInnerReleaseSwitchStatus ##2G## -  - C_TrunkInnerReleaseSw";
CM_ SG_ 1044 Trunk_TrnkTlgtOutReleaseSwSta "Trunk_TrunkTailgateOutReleaseSwitchStatus ##2G## -  - C_TrunkTgOtrReleaseSW";
CM_ SG_ 1044 Trunk_TrnkTlgtSwSta "Trunk_TrunkTailgateSwitchStatus ##2G## -  - C_TrunkTgSw,CF_Gway_TrunkTgSw,Trunk_TrnkTlgtSwSta";
CM_ SG_ 1044 Trunk_GlvBxTrnkLkSwSta "Trunk_GloveBoxTrunkLockSwitchStatus ##2G## -  - C_GloveBoxTrunkLockSw";
CM_ SG_ 1044 Trunk_TrnkTlgtReleaseRlySta "Trunk_TrunkTailgateReleaseRelayStatus ##2G## -  - C_TrunkTgReleaseRlyAct";
CM_ SG_ 1044 USM_OneTouchTrnSigFuncSta "USM_OneTouchTurnSignalFunctionStatus ##2G## -  - CF_Gway_OTTurnRValue,C_OTTurnRValue";
CM_ SG_ 1044 Defog_DfgrRlySta "Defog_DefoggerRelayStatus ##2G## -  - C_DefoggerRly,CF_Gway_DefoggerRly";
CM_ BO_ 1046 "[PE] Periodic and On Event";
CM_ SG_ 1046 ICU_Crc6Val "ICU_CyclicRedundancyCheck6Value";
CM_ SG_ 1046 ICU_AlvCnt6Val "ICU_AliveCounter6Value";
CM_ SG_ 1046 Lamp_RrTrnSigLmpLftOpnSta "Lamp_RearTurnSignalLampLeftOpenStatus ##2G## -  - C_RearTSIGLhOpenSts";
CM_ SG_ 1046 Lamp_RrTrnSigLmpRtOpnSta "Lamp_RearTurnSignalLampRightOpenStatus ##2G## -  - C_RearTSIGRhOpenSts";
CM_ SG_ 1046 Lamp_FrTrnSigLmpLftOpnSta "Lamp_FrontTurnSignalLampLeftOpenStatus ##2G## -  - C_FrontTSIGLhOpenSts";
CM_ SG_ 1046 Lamp_FrTrnSigLmpRtOpnSta "Lamp_FrontTurnSignalLampRightOpenStatus ##2G## -  - C_FrontTSIGRhOpenSts";
CM_ BO_ 1040 "[PE] Periodic and On Event";
CM_ SG_ 1040 ICU_Crc10Val "ICU_CyclicRedundancyCheck10Value";
CM_ SG_ 1040 ICU_AlvCnt10Val "ICU_AliveCounter10Value";
CM_ SG_ 1040 ICU_BS2SoC "This signal is battery State of Charge as calculated by battery sensor. ##2G## -  - BS2_SOC,Batt_SoC";
CM_ SG_ 1040 ICU_BS2NCap "Nominal capacity ##2G## -  - BS2_CNOM";
CM_ SG_ 1040 ICU_BS2OpnCirVol "Last open circuit voltage ##2G## -  - BS2_OCV";
CM_ SG_ 1040 ICU_BS2_FSOC "Fault State of SOC";
CM_ SG_ 1040 ICU_BS2_FSOH "Fault State of SOH";
CM_ SG_ 1040 ICU_BS2_FSOF "Fault State of SOF";
CM_ SG_ 1040 ICU_BS2_FQSTAT "State of quiescent current";
CM_ SG_ 1040 ICU_BS2SoH "This signal is battery State of Health(SOH) as calculated by battery sensor. ##2G## -  - BAT_SOH";
CM_ SG_ 1040 ICU_BS2SoF "This signal is battery State of Function(SOF) as calculated by battery sensor. ##2G## -  - BAT_SOF";
CM_ BO_ 579 "[PE] Periodic and On Event";
CM_ SG_ 579 OHCL_Opt "OHCL option state";
CM_ SG_ 579 OHCL_Sys_sta "OHCL Status";
CM_ SG_ 579 OHCL_DoorOn_Sta "Door lamp switch On/Off status";
CM_ SG_ 579 OHCL_RrMapLftOn_Sta "Rear left map lamp On/Off status";
CM_ SG_ 579 OHCL_RrMapRtOn_Sta "Rear right map lamp On/Off status";
CM_ SG_ 579 OHCL_RrRoomOn_Sta "Rear room lamp On/Off status";
CM_ SG_ 579 OHCL_RrMoodOn_Sta "Rear mood lamp On/Off status";
CM_ SG_ 579 OHCL_LEDClr_Sta "Interior lamps lighting color status";
CM_ SG_ 579 OHCL_LEDBgtns_Sta "Interior lamps brightness status";
CM_ SG_ 579 OHCL_TllTlLmpSta "PAB tell tale lamp status";
CM_ SG_ 579 OHCL_FrMapLftOn_Sta "Front left map lamp On/Off status";
CM_ SG_ 579 OHCL_FrMapRtOn_Sta "Front right map lamp On/Off status";
CM_ SG_ 579 OHCL_FrRoomOn_Sta "Front room lamp On/Off status";
CM_ SG_ 579 OHCL_FrMoodOn_Sta "Front mood lamp On/Off status";
CM_ BO_ 1067 "[PE] Periodic and On Event";
CM_ SG_ 1067 HWSW_SysSta "HWSW_SystemStatus";
CM_ SG_ 1067 USM_CmdSta "USM_CommandStatus";
CM_ SG_ 1067 SCM_HptWrngUSMSta "USM function for selecting HAPTIC WARNING strength";
CM_ SG_ 1067 SCM_PlyBckSta "SCM_PlayBackStatus";
CM_ SG_ 1067 SCM_SWVerMajor1 "First Word(ASCII) in SCM S/W Ver";
CM_ SG_ 1067 SCM_SWVerMinor1 "Second Word(ASCII) in SCM S/W Ver";
CM_ SG_ 1067 SCM_SWVerMinor2 "Third Word(ASCII) in SCM S/W Ver";
BA_DEF_ BO_ "DiagState" ENUM "No","Yes" ;
BA_DEF_ BO_ "DiagResponse" ENUM "No","Yes" ;
BA_DEF_ BO_ "DiagRequest" ENUM "No","Yes" ;
BA_DEF_ BO_ "TpMessage" ENUM "No","Yes" ;
BA_DEF_ BO_ "UsrMsgIDSforwardDeviation" INT 0 100 ;
BA_DEF_ BO_ "UsrMsgIDSbackwardDeviation" INT 50 1000 ;
BA_DEF_ BO_ "GenMsgCycleTime" INT 0 2000 ;
BA_DEF_ BO_ "GenMsgStartDelayTime" INT 0 2000 ;
BA_DEF_ BO_ "GenMsgSendType" ENUM "Cyclic","NoMsgSendType" ;
BA_DEF_ BO_ "GenMsgCycleTimeFast" INT 0 500 ;
BA_DEF_ BO_ "GenMsgDelayTime" INT 0 20 ;
BA_DEF_ BO_ "GenMsgILSupport" ENUM "No","Yes" ;
BA_DEF_ BO_ "GenMsgNrOfRepetition" INT 0 3 ;
BA_DEF_ BO_ "NmMessage" ENUM "No","Yes" ;
BA_DEF_ BO_ "NWM-Botschaft" ENUM "No","Yes" ;
BA_DEF_ BO_ "TpTxIndex" INT 0 255 ;
BA_DEF_ BO_ "VFrameFormat" ENUM "StandardCAN","ExtendedCAN","reserved","reserved","reserved","reserved","reserved","reserved","reserved","reserved","reserved","reserved","reserved","reserved","StandardCAN_FD","ExtendedCAN_FD" ;
BA_DEF_ SG_ "UserSigValidity" ENUM "B+","ACC","IG","IG1","IG2","IG3","IG1 or IG2","IG1 or IG3","Undef" ;
BA_DEF_ SG_ "TimeoutValue" STRING ;
BA_DEF_ SG_ "UsrSigPurpose" ENUM "Undef","FN","DIAG","DIAG(Req)","DIAG(Res)","DIAG(Phy)","DEV","CCP(Req)","CCP(Res)","NM","TP" ;
BA_DEF_ SG_ "GenSigStartValue" INT 0 1215752192 ;
BA_DEF_ SG_ "NetworkRequest" ENUM "Yes","No" ;
BA_DEF_ SG_ "NetworkRequestHoldingTime" INT 0 65535 ;
BA_DEF_ SG_ "Description" STRING ;
BA_DEF_ SG_ "Version" STRING ;
BA_DEF_ SG_ "GenSigEnvVarType" ENUM "Int","Float","Undef" ;
BA_DEF_ SG_ "GenSigSendType" ENUM "Cyclic","OnWrite","OnWriteWithRepetition","OnChange","OnChangeWithRepetition","IfActive","IfActiveWithRepetition","NoSigSendType","OnChangeAndIfActive","OnChangeAndIfActiveWithRepetition" ;
BA_DEF_ SG_ "GwSigLatencyTime" INT 0 65536 ;
BA_DEF_ SG_ "GwSigMissingSourceType" ENUM "Undef","OldValue","DefaultValue","InitialValue" ;
BA_DEF_ SG_ "NWM-WakeupAllowed" ENUM "<n.a.>" ;
BA_DEF_ SG_ "RoutingFactor" INT 1 1215752192 ;
BA_DEF_REL_ BU_SG_REL_ "GenSigTimeoutTime" INT 0 7000 ;
BA_DEF_DEF_ "DiagState" "No" ;
BA_DEF_DEF_ "DiagResponse" "No" ;
BA_DEF_DEF_ "DiagRequest" "No" ;
BA_DEF_DEF_ "TpMessage" "No" ;
BA_DEF_DEF_ "UsrMsgIDSforwardDeviation" 10 ;
BA_DEF_DEF_ "UsrMsgIDSbackwardDeviation" 100 ;
BA_DEF_DEF_ "GenMsgCycleTime" 200 ;
BA_DEF_DEF_ "GenMsgStartDelayTime" 0 ;
BA_DEF_DEF_ "GenMsgSendType" "NoMsgSendType" ;
BA_DEF_DEF_ "GenMsgCycleTimeFast" 40 ;
BA_DEF_DEF_ "GenMsgDelayTime" 20 ;
BA_DEF_DEF_ "GenMsgILSupport" "Yes" ;
BA_DEF_DEF_ "GenMsgNrOfRepetition" 3 ;
BA_DEF_DEF_ "NmMessage" "No" ;
BA_DEF_DEF_ "NWM-Botschaft" "No" ;
BA_DEF_DEF_ "TpTxIndex" 0 ;
BA_DEF_DEF_ "VFrameFormat" "StandardCAN" ;
BA_DEF_DEF_ "UserSigValidity" "IG" ;
BA_DEF_DEF_ "TimeoutValue" "" ;
BA_DEF_DEF_ "UsrSigPurpose" "FN" ;
BA_DEF_DEF_ "GenSigStartValue" 0 ;
BA_DEF_DEF_ "NetworkRequest" "No" ;
BA_DEF_DEF_ "NetworkRequestHoldingTime" 0 ;
BA_DEF_DEF_ "Description" "" ;
BA_DEF_DEF_ "Version" "" ;
BA_DEF_DEF_ "GenSigEnvVarType" "Undef" ;
BA_DEF_DEF_ "GenSigSendType" "NoSigSendType" ;
BA_DEF_DEF_ "GwSigLatencyTime" 40 ;
BA_DEF_DEF_ "GwSigMissingSourceType" "Undef" ;
BA_DEF_DEF_ "NWM-WakeupAllowed" "<n.a.>" ;
BA_DEF_DEF_ "RoutingFactor" 1 ;
BA_DEF_DEF_REL_ "GenSigTimeoutTime" 500 ;
BA_ "GenMsgSendType" BO_ 1548 0;
BA_ "GenMsgCycleTime" BO_ 1548 1000;
BA_ "Description" SG_ 1548 AMP_ASDModeState "HI : default value 0x1

DH PE : default value 0x3";
BA_ "GenSigSendType" SG_ 1548 AMP_ASDModeState 4;
BA_ "GenSigStartValue" SG_ 1548 AMP_ASDModeState 7;
BA_ "UserSigValidity" SG_ 1548 AMP_ASDModeState 1;
BA_REL_ "GenSigTimeoutTime" BU_SG_REL_ CGW_CCU SG_ 1548 AMP_ASDModeState 5000;
BA_ "NetworkRequest" SG_ 1548 AMP_ASDModeState 0;
BA_ "Version" SG_ 1548 AMP_ASDModeState "18.12.06";
BA_ "GenSigSendType" SG_ 1548 AMP_SPDIFInfo 4;
BA_ "GenSigStartValue" SG_ 1548 AMP_SPDIFInfo 7;
BA_ "UserSigValidity" SG_ 1548 AMP_SPDIFInfo 1;
BA_REL_ "GenSigTimeoutTime" BU_SG_REL_ CGW_CCU SG_ 1548 AMP_SPDIFInfo 5000;
BA_ "Version" SG_ 1548 AMP_SPDIFInfo "18.12.06";
BA_ "GenSigSendType" SG_ 1548 AMP_NaviModeState 4;
BA_ "GenSigStartValue" SG_ 1548 AMP_NaviModeState 3;
BA_ "UserSigValidity" SG_ 1548 AMP_NaviModeState 1;
BA_REL_ "GenSigTimeoutTime" BU_SG_REL_ CGW_CCU SG_ 1548 AMP_NaviModeState 5000;
BA_ "NetworkRequest" SG_ 1548 AMP_NaviModeState 0;
BA_ "Version" SG_ 1548 AMP_NaviModeState "18.12.06";
BA_ "Description" SG_ 1548 AMP_EngASDMasterGainState "0x03  : -6.0dB (DH PE OFF Value)

0x04  : -5.5dB

0x05  : -5.0dB

0x06  : -4.5dB

0x07  : -4.0dB

0x08  : -3.5dB

0x09  : -3.0dB (DH PE Moderate Value)

0x0A  : -2.5dB

0x0B  : -2.0dB

0x0C  : -1.5dB

0x0D  : -1.0dB

0x0E  : -0.5dB

0x0F  :  0.0dB (DH PE On Value)

0x10 :  0.5dB

0x11 :  1.0dB

0x12 :  1.5dB

0x13 :  2.0dB

0x14 :  2.5dB

0x15 :  3.0dB

0x16 :  3.5dB

0x17 :  4.0dB

0x18 :  4.5dB

0x19 :  5.0dB

0x1A :  5.5dB

0x1B :  6.0dB";
BA_ "GenSigSendType" SG_ 1548 AMP_EngASDMasterGainState 4;
BA_ "GenSigStartValue" SG_ 1548 AMP_EngASDMasterGainState 31;
BA_ "UserSigValidity" SG_ 1548 AMP_EngASDMasterGainState 1;
BA_REL_ "GenSigTimeoutTime" BU_SG_REL_ CGW_CCU SG_ 1548 AMP_EngASDMasterGainState 5000;
BA_ "NetworkRequest" SG_ 1548 AMP_EngASDMasterGainState 0;
BA_ "Version" SG_ 1548 AMP_EngASDMasterGainState "18.12.06";
BA_ "GenSigSendType" SG_ 1548 AMP_SDVCStepState 4;
BA_ "GenSigStartValue" SG_ 1548 AMP_SDVCStepState 7;
BA_ "UserSigValidity" SG_ 1548 AMP_SDVCStepState 1;
BA_REL_ "GenSigTimeoutTime" BU_SG_REL_ CGW_CCU SG_ 1548 AMP_SDVCStepState 5000;
BA_ "NetworkRequest" SG_ 1548 AMP_SDVCStepState 0;
BA_ "Version" SG_ 1548 AMP_SDVCStepState "18.12.06";
BA_ "Description" SG_ 1548 AMP_Beep1KBDModeState "Information for Current keyboard Beep1Mode Status

-Feedback from AMP_Beep1KBDMode@H_U";
BA_ "GenSigSendType" SG_ 1548 AMP_Beep1KBDModeState 4;
BA_ "GenSigStartValue" SG_ 1548 AMP_Beep1KBDModeState 3;
BA_ "UserSigValidity" SG_ 1548 AMP_Beep1KBDModeState 1;
BA_REL_ "GenSigTimeoutTime" BU_SG_REL_ CGW_CCU SG_ 1548 AMP_Beep1KBDModeState 5000;
BA_ "Version" SG_ 1548 AMP_Beep1KBDModeState "20.06.01";
BA_ "GenSigSendType" SG_ 1548 AMP_Beep1ModeState 4;
BA_ "GenSigStartValue" SG_ 1548 AMP_Beep1ModeState 3;
BA_ "UserSigValidity" SG_ 1548 AMP_Beep1ModeState 1;
BA_REL_ "GenSigTimeoutTime" BU_SG_REL_ CGW_CCU SG_ 1548 AMP_Beep1ModeState 5000;
BA_ "NetworkRequest" SG_ 1548 AMP_Beep1ModeState 0;
BA_ "Version" SG_ 1548 AMP_Beep1ModeState "18.12.06";
BA_ "GenSigSendType" SG_ 1548 HU_InitInfo 4;
BA_ "GenSigStartValue" SG_ 1548 HU_InitInfo 3;
BA_ "UserSigValidity" SG_ 1548 HU_InitInfo 1;
BA_REL_ "GenSigTimeoutTime" BU_SG_REL_ CGW_CCU SG_ 1548 HU_InitInfo 5000;
BA_ "Version" SG_ 1548 HU_InitInfo "18.12.06";
BA_ "Description" SG_ 1548 AMP_MasterBeepVolumeState "Feedback for MasterBeepVolumeStep (1/2/3/4/5)";
BA_ "GenSigSendType" SG_ 1548 AMP_MasterBeepVolumeState 4;
BA_ "UserSigValidity" SG_ 1548 AMP_MasterBeepVolumeState 1;
BA_REL_ "GenSigTimeoutTime" BU_SG_REL_ CGW_CCU SG_ 1548 AMP_MasterBeepVolumeState 5000;
BA_ "NetworkRequest" SG_ 1548 AMP_MasterBeepVolumeState 0;
BA_ "Version" SG_ 1548 AMP_MasterBeepVolumeState "20.07.03";
BA_ "GenSigSendType" SG_ 1548 AMP_ANCModeState 4;
BA_ "GenSigStartValue" SG_ 1548 AMP_ANCModeState 3;
BA_ "UserSigValidity" SG_ 1548 AMP_ANCModeState 1;
BA_REL_ "GenSigTimeoutTime" BU_SG_REL_ CGW_CCU SG_ 1548 AMP_ANCModeState 5000;
BA_ "NetworkRequest" SG_ 1548 AMP_ANCModeState 0;
BA_ "Version" SG_ 1548 AMP_ANCModeState "18.12.06";
BA_ "GenSigSendType" SG_ 1548 AMP_DistrInfoState 4;
BA_ "GenSigStartValue" SG_ 1548 AMP_DistrInfoState 3;
BA_ "UserSigValidity" SG_ 1548 AMP_DistrInfoState 1;
BA_REL_ "GenSigTimeoutTime" BU_SG_REL_ CGW_CCU SG_ 1548 AMP_DistrInfoState 5000;
BA_ "NetworkRequest" SG_ 1548 AMP_DistrInfoState 0;
BA_ "Version" SG_ 1548 AMP_DistrInfoState "18.12.06";
BA_ "Description" SG_ 1548 AMP_TTSModeState "This signal is feedback signal on TTS sound output";
BA_ "GenSigSendType" SG_ 1548 AMP_TTSModeState 4;
BA_ "GenSigStartValue" SG_ 1548 AMP_TTSModeState 3;
BA_ "UserSigValidity" SG_ 1548 AMP_TTSModeState 1;
BA_REL_ "GenSigTimeoutTime" BU_SG_REL_ CGW_CCU SG_ 1548 AMP_TTSModeState 5000;
BA_ "Version" SG_ 1548 AMP_TTSModeState "19.07.06";
BA_ "GenSigSendType" SG_ 1548 AMP_INFORM_TO_IPM 4;
BA_ "GenSigStartValue" SG_ 1548 AMP_INFORM_TO_IPM 3;
BA_ "UserSigValidity" SG_ 1548 AMP_INFORM_TO_IPM 1;
BA_REL_ "GenSigTimeoutTime" BU_SG_REL_ CGW_CCU SG_ 1548 AMP_INFORM_TO_IPM 5000;
BA_ "NetworkRequest" SG_ 1548 AMP_INFORM_TO_IPM 0;
BA_ "Version" SG_ 1548 AMP_INFORM_TO_IPM "18.12.06";
BA_ "GenSigSendType" SG_ 1548 AMP_StartUpComplete 4;
BA_ "GenSigStartValue" SG_ 1548 AMP_StartUpComplete 3;
BA_ "UserSigValidity" SG_ 1548 AMP_StartUpComplete 1;
BA_REL_ "GenSigTimeoutTime" BU_SG_REL_ CGW_CCU SG_ 1548 AMP_StartUpComplete 5000;
BA_ "NetworkRequest" SG_ 1548 AMP_StartUpComplete 0;
BA_ "Version" SG_ 1548 AMP_StartUpComplete "18.12.06";
BA_ "GenMsgSendType" BO_ 1549 0;
BA_ "GenMsgCycleTime" BO_ 1549 1000;
BA_ "Description" SG_ 1549 AMP_VirtualVenueModeStatus "Response VV mode status";
BA_ "GenSigSendType" SG_ 1549 AMP_VirtualVenueModeStatus 4;
BA_ "GenSigStartValue" SG_ 1549 AMP_VirtualVenueModeStatus 7;
BA_ "UserSigValidity" SG_ 1549 AMP_VirtualVenueModeStatus 1;
BA_REL_ "GenSigTimeoutTime" BU_SG_REL_ CGW_CCU SG_ 1549 AMP_VirtualVenueModeStatus 5000;
BA_ "NetworkRequest" SG_ 1549 AMP_VirtualVenueModeStatus 0;
BA_ "Version" SG_ 1549 AMP_VirtualVenueModeStatus "19.08.08";
BA_ "GenSigSendType" SG_ 1549 AMP_EQState 4;
BA_ "GenSigStartValue" SG_ 1549 AMP_EQState 3;
BA_ "UserSigValidity" SG_ 1549 AMP_EQState 1;
BA_REL_ "GenSigTimeoutTime" BU_SG_REL_ CGW_CCU SG_ 1549 AMP_EQState 5000;
BA_ "NetworkRequest" SG_ 1549 AMP_EQState 0;
BA_ "Version" SG_ 1549 AMP_EQState "18.12.06";
BA_ "Description" SG_ 1549 AMP_DriverModeStatus "Response Driver mode status";
BA_ "GenSigSendType" SG_ 1549 AMP_DriverModeStatus 4;
BA_ "GenSigStartValue" SG_ 1549 AMP_DriverModeStatus 3;
BA_ "UserSigValidity" SG_ 1549 AMP_DriverModeStatus 1;
BA_REL_ "GenSigTimeoutTime" BU_SG_REL_ CGW_CCU SG_ 1549 AMP_DriverModeStatus 5000;
BA_ "NetworkRequest" SG_ 1549 AMP_DriverModeStatus 0;
BA_ "Version" SG_ 1549 AMP_DriverModeStatus "19.08.08";
BA_ "Description" SG_ 1549 AMP_WrnPromptModeSta "This signal is used for feedback of AMP_WrnPromptMode@HU_AMP_E_02";
BA_ "GenSigSendType" SG_ 1549 AMP_WrnPromptModeSta 4;
BA_ "GenSigStartValue" SG_ 1549 AMP_WrnPromptModeSta 3;
BA_ "UserSigValidity" SG_ 1549 AMP_WrnPromptModeSta 0;
BA_REL_ "GenSigTimeoutTime" BU_SG_REL_ CGW_CCU SG_ 1549 AMP_WrnPromptModeSta 5000;
BA_ "Version" SG_ 1549 AMP_WrnPromptModeSta "19.02.07";
BA_ "GenSigSendType" SG_ 1549 AMP_ESEVwarning 4;
BA_ "UserSigValidity" SG_ 1549 AMP_ESEVwarning 1;
BA_REL_ "GenSigTimeoutTime" BU_SG_REL_ CGW_CCU SG_ 1549 AMP_ESEVwarning 5000;
BA_ "Version" SG_ 1549 AMP_ESEVwarning "20.07.00";
BA_ "GenSigSendType" SG_ 1549 AMP_SPDIFMuteSt 4;
BA_ "GenSigStartValue" SG_ 1549 AMP_SPDIFMuteSt 1;
BA_ "UserSigValidity" SG_ 1549 AMP_SPDIFMuteSt 1;
BA_REL_ "GenSigTimeoutTime" BU_SG_REL_ CGW_CCU SG_ 1549 AMP_SPDIFMuteSt 5000;
BA_ "NetworkRequest" SG_ 1549 AMP_SPDIFMuteSt 0;
BA_ "Version" SG_ 1549 AMP_SPDIFMuteSt "18.12.06";
BA_ "GenSigSendType" SG_ 1549 AMP_RANCwarning 4;
BA_ "UserSigValidity" SG_ 1549 AMP_RANCwarning 1;
BA_REL_ "GenSigTimeoutTime" BU_SG_REL_ CGW_CCU SG_ 1549 AMP_RANCwarning 5000;
BA_ "Version" SG_ 1549 AMP_RANCwarning "18.12.06";
BA_ "GenSigSendType" SG_ 1549 AMP_RANCstate 4;
BA_ "UserSigValidity" SG_ 1549 AMP_RANCstate 1;
BA_REL_ "GenSigTimeoutTime" BU_SG_REL_ CGW_CCU SG_ 1549 AMP_RANCstate 5000;
BA_ "Version" SG_ 1549 AMP_RANCstate "18.12.06";
BA_ "Description" SG_ 1549 AMP_QLIModeStatus "Response QLI mode status";
BA_ "GenSigSendType" SG_ 1549 AMP_QLIModeStatus 4;
BA_ "GenSigStartValue" SG_ 1549 AMP_QLIModeStatus 7;
BA_ "UserSigValidity" SG_ 1549 AMP_QLIModeStatus 1;
BA_REL_ "GenSigTimeoutTime" BU_SG_REL_ CGW_CCU SG_ 1549 AMP_QLIModeStatus 5000;
BA_ "NetworkRequest" SG_ 1549 AMP_QLIModeStatus 0;
BA_ "Version" SG_ 1549 AMP_QLIModeStatus "19.08.08";
BA_ "Description" SG_ 1549 AMP_AudioSource "Condition : AVN + EXT AMP";
BA_ "GenSigSendType" SG_ 1549 AMP_AudioSource 4;
BA_ "GenSigStartValue" SG_ 1549 AMP_AudioSource 255;
BA_ "UserSigValidity" SG_ 1549 AMP_AudioSource 1;
BA_REL_ "GenSigTimeoutTime" BU_SG_REL_ CGW_CCU SG_ 1549 AMP_AudioSource 5000;
BA_ "NetworkRequest" SG_ 1549 AMP_AudioSource 0;
BA_ "Version" SG_ 1549 AMP_AudioSource "19.08.08";
BA_ "Description" SG_ 1549 AMP_QuietModeState "Condition : AVN + EXT AMP";
BA_ "GenSigSendType" SG_ 1549 AMP_QuietModeState 4;
BA_ "GenSigStartValue" SG_ 1549 AMP_QuietModeState 3;
BA_ "UserSigValidity" SG_ 1549 AMP_QuietModeState 1;
BA_REL_ "GenSigTimeoutTime" BU_SG_REL_ CGW_CCU SG_ 1549 AMP_QuietModeState 5000;
BA_ "Version" SG_ 1549 AMP_QuietModeState "18.12.06";
BA_ "GenSigSendType" SG_ 1549 AMP_QLSModeState 4;
BA_ "GenSigStartValue" SG_ 1549 AMP_QLSModeState 3;
BA_ "UserSigValidity" SG_ 1549 AMP_QLSModeState 1;
BA_REL_ "GenSigTimeoutTime" BU_SG_REL_ CGW_CCU SG_ 1549 AMP_QLSModeState 5000;
BA_ "Version" SG_ 1549 AMP_QLSModeState "18.12.06";
BA_ "Description" SG_ 1549 AMP_VoiceGuideTTSLevelStatus "Response Voice Guide TTS volume level";
BA_ "GenSigSendType" SG_ 1549 AMP_VoiceGuideTTSLevelStatus 4;
BA_ "GenSigStartValue" SG_ 1549 AMP_VoiceGuideTTSLevelStatus 7;
BA_ "UserSigValidity" SG_ 1549 AMP_VoiceGuideTTSLevelStatus 1;
BA_REL_ "GenSigTimeoutTime" BU_SG_REL_ CGW_CCU SG_ 1549 AMP_VoiceGuideTTSLevelStatus 5000;
BA_ "NetworkRequest" SG_ 1549 AMP_VoiceGuideTTSLevelStatus 0;
BA_ "Version" SG_ 1549 AMP_VoiceGuideTTSLevelStatus "19.08.08";
BA_ "Description" SG_ 1549 AMP_VoiceGuideTTSStatus "Response Voice Guide TTS status";
BA_ "GenSigSendType" SG_ 1549 AMP_VoiceGuideTTSStatus 4;
BA_ "GenSigStartValue" SG_ 1549 AMP_VoiceGuideTTSStatus 3;
BA_ "UserSigValidity" SG_ 1549 AMP_VoiceGuideTTSStatus 1;
BA_REL_ "GenSigTimeoutTime" BU_SG_REL_ CGW_CCU SG_ 1549 AMP_VoiceGuideTTSStatus 5000;
BA_ "NetworkRequest" SG_ 1549 AMP_VoiceGuideTTSStatus 0;
BA_ "Version" SG_ 1549 AMP_VoiceGuideTTSStatus "19.08.08";
BA_ "GenSigSendType" SG_ 1549 AMP_MuteState 4;
BA_ "GenSigStartValue" SG_ 1549 AMP_MuteState 3;
BA_ "UserSigValidity" SG_ 1549 AMP_MuteState 1;
BA_REL_ "GenSigTimeoutTime" BU_SG_REL_ CGW_CCU SG_ 1549 AMP_MuteState 5000;
BA_ "NetworkRequest" SG_ 1549 AMP_MuteState 0;
BA_ "Version" SG_ 1549 AMP_MuteState "18.12.06";
BA_ "Description" SG_ 1549 AMP_ALTPopUpStatus "Response ALT status";
BA_ "GenSigSendType" SG_ 1549 AMP_ALTPopUpStatus 4;
BA_ "GenSigStartValue" SG_ 1549 AMP_ALTPopUpStatus 3;
BA_ "UserSigValidity" SG_ 1549 AMP_ALTPopUpStatus 1;
BA_REL_ "GenSigTimeoutTime" BU_SG_REL_ CGW_CCU SG_ 1549 AMP_ALTPopUpStatus 5000;
BA_ "NetworkRequest" SG_ 1549 AMP_ALTPopUpStatus 0;
BA_ "Version" SG_ 1549 AMP_ALTPopUpStatus "19.08.08";
BA_ "GenSigSendType" SG_ 1549 AMP_LogSnapshotState 4;
BA_ "GenSigStartValue" SG_ 1549 AMP_LogSnapshotState 3;
BA_ "UserSigValidity" SG_ 1549 AMP_LogSnapshotState 1;
BA_REL_ "GenSigTimeoutTime" BU_SG_REL_ CGW_CCU SG_ 1549 AMP_LogSnapshotState 5000;
BA_ "Version" SG_ 1549 AMP_LogSnapshotState "20.07.05";
BA_ "GenMsgSendType" BO_ 1550 0;
BA_ "GenMsgCycleTime" BO_ 1550 2000;
BA_ "Description" SG_ 1550 AMP_MainVolumeSetting "0~max : AMP_MaxBalanceSteP(0x085)

255 :Invalid";
BA_ "GenSigSendType" SG_ 1550 AMP_MainVolumeSetting 4;
BA_ "GenSigStartValue" SG_ 1550 AMP_MainVolumeSetting 255;
BA_ "UserSigValidity" SG_ 1550 AMP_MainVolumeSetting 1;
BA_REL_ "GenSigTimeoutTime" BU_SG_REL_ CGW_CCU SG_ 1550 AMP_MainVolumeSetting 5000;
BA_ "NetworkRequest" SG_ 1550 AMP_MainVolumeSetting 0;
BA_ "Version" SG_ 1550 AMP_MainVolumeSetting "18.12.06";
BA_ "Description" SG_ 1550 AMP_FadeSetting "0~max : AMP_MaxBassStep(0x085)

255 :Invalid";
BA_ "GenSigSendType" SG_ 1550 AMP_FadeSetting 4;
BA_ "GenSigStartValue" SG_ 1550 AMP_FadeSetting 255;
BA_ "UserSigValidity" SG_ 1550 AMP_FadeSetting 1;
BA_REL_ "GenSigTimeoutTime" BU_SG_REL_ CGW_CCU SG_ 1550 AMP_FadeSetting 5000;
BA_ "NetworkRequest" SG_ 1550 AMP_FadeSetting 0;
BA_ "Version" SG_ 1550 AMP_FadeSetting "18.12.06";
BA_ "Description" SG_ 1550 AMP_BassSetting "0~max : AMP_MaxMidStep(0x085)

255 :Invalid";
BA_ "GenSigSendType" SG_ 1550 AMP_BassSetting 4;
BA_ "GenSigStartValue" SG_ 1550 AMP_BassSetting 255;
BA_ "UserSigValidity" SG_ 1550 AMP_BassSetting 1;
BA_REL_ "GenSigTimeoutTime" BU_SG_REL_ CGW_CCU SG_ 1550 AMP_BassSetting 5000;
BA_ "NetworkRequest" SG_ 1550 AMP_BassSetting 0;
BA_ "Version" SG_ 1550 AMP_BassSetting "18.12.06";
BA_ "Description" SG_ 1550 AMP_MidSetting "0~max : AMP_MaxTrebleStep(0x085)

255 :Invalid";
BA_ "GenSigSendType" SG_ 1550 AMP_MidSetting 4;
BA_ "GenSigStartValue" SG_ 1550 AMP_MidSetting 255;
BA_ "UserSigValidity" SG_ 1550 AMP_MidSetting 1;
BA_REL_ "GenSigTimeoutTime" BU_SG_REL_ CGW_CCU SG_ 1550 AMP_MidSetting 5000;
BA_ "NetworkRequest" SG_ 1550 AMP_MidSetting 0;
BA_ "Version" SG_ 1550 AMP_MidSetting "18.12.06";
BA_ "Description" SG_ 1550 AMP_TrebleSetting "[Old Signal]

* This signal is NOT used after 05 MAR 19

Use new signal (AMP_PESSCANSetting) instead";
BA_ "GenSigSendType" SG_ 1550 AMP_TrebleSetting 4;
BA_ "GenSigStartValue" SG_ 1550 AMP_TrebleSetting 255;
BA_ "UserSigValidity" SG_ 1550 AMP_TrebleSetting 1;
BA_REL_ "GenSigTimeoutTime" BU_SG_REL_ CGW_CCU SG_ 1550 AMP_TrebleSetting 5000;
BA_ "NetworkRequest" SG_ 1550 AMP_TrebleSetting 0;
BA_ "Version" SG_ 1550 AMP_TrebleSetting "18.12.06";
BA_ "GenSigSendType" SG_ 1550 AMP_ESEVModeState 4;
BA_ "GenSigStartValue" SG_ 1550 AMP_ESEVModeState 7;
BA_ "UserSigValidity" SG_ 1550 AMP_ESEVModeState 1;
BA_REL_ "GenSigTimeoutTime" BU_SG_REL_ CGW_CCU SG_ 1550 AMP_ESEVModeState 5000;
BA_ "NetworkRequest" SG_ 1550 AMP_ESEVModeState 0;
BA_ "Version" SG_ 1550 AMP_ESEVModeState "20.07.08";
BA_ "GenSigSendType" SG_ 1550 AMP_ESEVMasterGainState 4;
BA_ "GenSigStartValue" SG_ 1550 AMP_ESEVMasterGainState 31;
BA_ "UserSigValidity" SG_ 1550 AMP_ESEVMasterGainState 1;
BA_REL_ "GenSigTimeoutTime" BU_SG_REL_ CGW_CCU SG_ 1550 AMP_ESEVMasterGainState 5000;
BA_ "NetworkRequest" SG_ 1550 AMP_ESEVMasterGainState 0;
BA_ "Version" SG_ 1550 AMP_ESEVMasterGainState "20.03.06";
BA_ "Description" SG_ 1550 AMP_BalanceSetting "0~max : AMP_MaxFadeStep(0x085)

255 :Invalid";
BA_ "GenSigSendType" SG_ 1550 AMP_BalanceSetting 4;
BA_ "GenSigStartValue" SG_ 1550 AMP_BalanceSetting 255;
BA_ "UserSigValidity" SG_ 1550 AMP_BalanceSetting 1;
BA_REL_ "GenSigTimeoutTime" BU_SG_REL_ CGW_CCU SG_ 1550 AMP_BalanceSetting 5000;
BA_ "NetworkRequest" SG_ 1550 AMP_BalanceSetting 0;
BA_ "Version" SG_ 1550 AMP_BalanceSetting "18.12.06";
BA_ "GenMsgSendType" BO_ 1551 0;
BA_ "GenMsgCycleTime" BO_ 1551 2000;
BA_ "Description" SG_ 1551 AMP_ADASVolumeState "Feedback signal for ADAS warning sound volume level";
BA_ "GenSigSendType" SG_ 1551 AMP_ADASVolumeState 4;
BA_ "GenSigStartValue" SG_ 1551 AMP_ADASVolumeState 255;
BA_ "UserSigValidity" SG_ 1551 AMP_ADASVolumeState 1;
BA_REL_ "GenSigTimeoutTime" BU_SG_REL_ CGW_CCU SG_ 1551 AMP_ADASVolumeState 5000;
BA_ "Version" SG_ 1551 AMP_ADASVolumeState "21.05.02";
BA_ "GenMsgCycleTime" BO_ 639 0;
BA_ "Description" SG_ 639 ATS_RLSeatHeaterUpSW "후석 LH 시트 열선 조절";
BA_ "GenSigSendType" SG_ 639 ATS_RLSeatHeaterUpSW 4;
BA_ "UserSigValidity" SG_ 639 ATS_RLSeatHeaterUpSW 3;
BA_REL_ "GenSigTimeoutTime" BU_SG_REL_ RLHV SG_ 639 ATS_RLSeatHeaterUpSW 0;
BA_REL_ "GenSigTimeoutTime" BU_SG_REL_ RLPSM SG_ 639 ATS_RLSeatHeaterUpSW 0;
BA_REL_ "GenSigTimeoutTime" BU_SG_REL_ RRHV SG_ 639 ATS_RLSeatHeaterUpSW 0;
BA_REL_ "GenSigTimeoutTime" BU_SG_REL_ RRPSM SG_ 639 ATS_RLSeatHeaterUpSW 0;
BA_ "NetworkRequest" SG_ 639 ATS_RLSeatHeaterUpSW 0;
BA_ "NetworkRequestHoldingTime" SG_ 639 ATS_RLSeatHeaterUpSW 5000;
BA_ "Version" SG_ 639 ATS_RLSeatHeaterUpSW "20.12.04";
BA_ "Description" SG_ 639 ATS_RRSeatVentDownSW "후석 RH 시트 통풍 조절";
BA_ "GenSigSendType" SG_ 639 ATS_RRSeatVentDownSW 4;
BA_ "UserSigValidity" SG_ 639 ATS_RRSeatVentDownSW 3;
BA_REL_ "GenSigTimeoutTime" BU_SG_REL_ RLHV SG_ 639 ATS_RRSeatVentDownSW 0;
BA_REL_ "GenSigTimeoutTime" BU_SG_REL_ RLPSM SG_ 639 ATS_RRSeatVentDownSW 0;
BA_REL_ "GenSigTimeoutTime" BU_SG_REL_ RRHV SG_ 639 ATS_RRSeatVentDownSW 0;
BA_REL_ "GenSigTimeoutTime" BU_SG_REL_ RRPSM SG_ 639 ATS_RRSeatVentDownSW 0;
BA_ "NetworkRequest" SG_ 639 ATS_RRSeatVentDownSW 0;
BA_ "NetworkRequestHoldingTime" SG_ 639 ATS_RRSeatVentDownSW 5000;
BA_ "Version" SG_ 639 ATS_RRSeatVentDownSW "20.12.04";
BA_ "Description" SG_ 639 ATS_RLSeatVentDownSW "후석 LH 시트 통풍 조절";
BA_ "GenSigSendType" SG_ 639 ATS_RLSeatVentDownSW 4;
BA_ "UserSigValidity" SG_ 639 ATS_RLSeatVentDownSW 3;
BA_REL_ "GenSigTimeoutTime" BU_SG_REL_ RLHV SG_ 639 ATS_RLSeatVentDownSW 0;
BA_REL_ "GenSigTimeoutTime" BU_SG_REL_ RLPSM SG_ 639 ATS_RLSeatVentDownSW 0;
BA_REL_ "GenSigTimeoutTime" BU_SG_REL_ RRHV SG_ 639 ATS_RLSeatVentDownSW 0;
BA_REL_ "GenSigTimeoutTime" BU_SG_REL_ RRPSM SG_ 639 ATS_RLSeatVentDownSW 0;
BA_ "NetworkRequest" SG_ 639 ATS_RLSeatVentDownSW 0;
BA_ "NetworkRequestHoldingTime" SG_ 639 ATS_RLSeatVentDownSW 5000;
BA_ "Version" SG_ 639 ATS_RLSeatVentDownSW "20.12.04";
BA_ "Description" SG_ 639 ATS_RLMemoryRestBtn "Rear Left Rest Mode Custom Save Button (Except North America)";
BA_ "GenSigSendType" SG_ 639 ATS_RLMemoryRestBtn 4;
BA_ "UserSigValidity" SG_ 639 ATS_RLMemoryRestBtn 3;
BA_REL_ "GenSigTimeoutTime" BU_SG_REL_ PSM SG_ 639 ATS_RLMemoryRestBtn 0;
BA_REL_ "GenSigTimeoutTime" BU_SG_REL_ RLPSM SG_ 639 ATS_RLMemoryRestBtn 0;
BA_ "NetworkRequest" SG_ 639 ATS_RLMemoryRestBtn 0;
BA_ "NetworkRequestHoldingTime" SG_ 639 ATS_RLMemoryRestBtn 5000;
BA_ "Version" SG_ 639 ATS_RLMemoryRestBtn "21.01.02";
BA_ "Description" SG_ 639 ATS_RLMemoryReturnBtn "Rear Left Return Mode Custom Save Button (Except North America)";
BA_ "GenSigSendType" SG_ 639 ATS_RLMemoryReturnBtn 4;
BA_ "UserSigValidity" SG_ 639 ATS_RLMemoryReturnBtn 3;
BA_REL_ "GenSigTimeoutTime" BU_SG_REL_ PSM SG_ 639 ATS_RLMemoryReturnBtn 0;
BA_REL_ "GenSigTimeoutTime" BU_SG_REL_ RLPSM SG_ 639 ATS_RLMemoryReturnBtn 0;
BA_ "NetworkRequest" SG_ 639 ATS_RLMemoryReturnBtn 0;
BA_ "NetworkRequestHoldingTime" SG_ 639 ATS_RLMemoryReturnBtn 5000;
BA_ "Version" SG_ 639 ATS_RLMemoryReturnBtn "21.01.02";
BA_ "Description" SG_ 639 ATS_RRMemoryRestBtn "Rear Right Rest Mode Custom Save Button (Except North America)";
BA_ "GenSigSendType" SG_ 639 ATS_RRMemoryRestBtn 4;
BA_ "UserSigValidity" SG_ 639 ATS_RRMemoryRestBtn 3;
BA_REL_ "GenSigTimeoutTime" BU_SG_REL_ APSM SG_ 639 ATS_RRMemoryRestBtn 0;
BA_REL_ "GenSigTimeoutTime" BU_SG_REL_ RRPSM SG_ 639 ATS_RRMemoryRestBtn 0;
BA_ "NetworkRequest" SG_ 639 ATS_RRMemoryRestBtn 0;
BA_ "NetworkRequestHoldingTime" SG_ 639 ATS_RRMemoryRestBtn 5000;
BA_ "Version" SG_ 639 ATS_RRMemoryRestBtn "21.01.02";
BA_ "Description" SG_ 639 ATS_RRMemoryReturnBtn "Rear Right Return Mode Custom Save Button (Except North America)";
BA_ "GenSigSendType" SG_ 639 ATS_RRMemoryReturnBtn 4;
BA_ "UserSigValidity" SG_ 639 ATS_RRMemoryReturnBtn 3;
BA_REL_ "GenSigTimeoutTime" BU_SG_REL_ APSM SG_ 639 ATS_RRMemoryReturnBtn 0;
BA_REL_ "GenSigTimeoutTime" BU_SG_REL_ RRPSM SG_ 639 ATS_RRMemoryReturnBtn 0;
BA_ "NetworkRequest" SG_ 639 ATS_RRMemoryReturnBtn 0;
BA_ "NetworkRequestHoldingTime" SG_ 639 ATS_RRMemoryReturnBtn 5000;
BA_ "Version" SG_ 639 ATS_RRMemoryReturnBtn "21.01.02";
BA_ "Description" SG_ 639 ATS_RRMemoryAvWtcBtn "Rear Right AV Watching Mode Custom Save Button (Except North America)";
BA_ "GenSigSendType" SG_ 639 ATS_RRMemoryAvWtcBtn 4;
BA_ "UserSigValidity" SG_ 639 ATS_RRMemoryAvWtcBtn 3;
BA_REL_ "GenSigTimeoutTime" BU_SG_REL_ APSM SG_ 639 ATS_RRMemoryAvWtcBtn 0;
BA_REL_ "GenSigTimeoutTime" BU_SG_REL_ RRPSM SG_ 639 ATS_RRMemoryAvWtcBtn 0;
BA_ "NetworkRequest" SG_ 639 ATS_RRMemoryAvWtcBtn 0;
BA_ "NetworkRequestHoldingTime" SG_ 639 ATS_RRMemoryAvWtcBtn 5000;
BA_ "Version" SG_ 639 ATS_RRMemoryAvWtcBtn "21.01.02";
BA_ "Description" SG_ 639 ATS_RRMemoryReadingBtn "Rear Right Reading Mode Custom Save Button (Except North America)";
BA_ "GenSigSendType" SG_ 639 ATS_RRMemoryReadingBtn 4;
BA_ "UserSigValidity" SG_ 639 ATS_RRMemoryReadingBtn 3;
BA_REL_ "GenSigTimeoutTime" BU_SG_REL_ APSM SG_ 639 ATS_RRMemoryReadingBtn 0;
BA_REL_ "GenSigTimeoutTime" BU_SG_REL_ RRPSM SG_ 639 ATS_RRMemoryReadingBtn 0;
BA_ "NetworkRequest" SG_ 639 ATS_RRMemoryReadingBtn 0;
BA_ "NetworkRequestHoldingTime" SG_ 639 ATS_RRMemoryReadingBtn 5000;
BA_ "Version" SG_ 639 ATS_RRMemoryReadingBtn "21.01.02";
BA_ "Description" SG_ 639 ATS_RRRestModBtnSTD "Rear Right Rest Mode Touch Button (EXCEPT North America)";
BA_ "GenSigSendType" SG_ 639 ATS_RRRestModBtnSTD 4;
BA_ "UserSigValidity" SG_ 639 ATS_RRRestModBtnSTD 3;
BA_REL_ "GenSigTimeoutTime" BU_SG_REL_ APSM SG_ 639 ATS_RRRestModBtnSTD 0;
BA_REL_ "GenSigTimeoutTime" BU_SG_REL_ RRPSM SG_ 639 ATS_RRRestModBtnSTD 0;
BA_ "NetworkRequest" SG_ 639 ATS_RRRestModBtnSTD 0;
BA_ "NetworkRequestHoldingTime" SG_ 639 ATS_RRRestModBtnSTD 5000;
BA_ "Version" SG_ 639 ATS_RRRestModBtnSTD "20.07.01";
BA_ "Description" SG_ 639 ATS_RRResetModBtnSTD "Rear Right Return Mode Touch Button (EXCEPT North America)";
BA_ "GenSigSendType" SG_ 639 ATS_RRResetModBtnSTD 4;
BA_ "UserSigValidity" SG_ 639 ATS_RRResetModBtnSTD 3;
BA_REL_ "GenSigTimeoutTime" BU_SG_REL_ APSM SG_ 639 ATS_RRResetModBtnSTD 0;
BA_REL_ "GenSigTimeoutTime" BU_SG_REL_ RRPSM SG_ 639 ATS_RRResetModBtnSTD 0;
BA_ "NetworkRequest" SG_ 639 ATS_RRResetModBtnSTD 0;
BA_ "NetworkRequestHoldingTime" SG_ 639 ATS_RRResetModBtnSTD 5000;
BA_ "Version" SG_ 639 ATS_RRResetModBtnSTD "20.07.01";
BA_ "Description" SG_ 639 ATS_RRAvWtcModBtnSTD "Rear Right AV Watching Mode Touch Button (EXCEPT North America)";
BA_ "GenSigSendType" SG_ 639 ATS_RRAvWtcModBtnSTD 4;
BA_ "UserSigValidity" SG_ 639 ATS_RRAvWtcModBtnSTD 3;
BA_REL_ "GenSigTimeoutTime" BU_SG_REL_ APSM SG_ 639 ATS_RRAvWtcModBtnSTD 0;
BA_REL_ "GenSigTimeoutTime" BU_SG_REL_ RRPSM SG_ 639 ATS_RRAvWtcModBtnSTD 0;
BA_ "NetworkRequest" SG_ 639 ATS_RRAvWtcModBtnSTD 0;
BA_ "NetworkRequestHoldingTime" SG_ 639 ATS_RRAvWtcModBtnSTD 5000;
BA_ "Version" SG_ 639 ATS_RRAvWtcModBtnSTD "20.07.01";
BA_ "Description" SG_ 639 ATS_RRReadingModBtnSTD "Rear Right Reading Mode Touch Button (EXCEPT North America)";
BA_ "GenSigSendType" SG_ 639 ATS_RRReadingModBtnSTD 4;
BA_ "UserSigValidity" SG_ 639 ATS_RRReadingModBtnSTD 3;
BA_REL_ "GenSigTimeoutTime" BU_SG_REL_ APSM SG_ 639 ATS_RRReadingModBtnSTD 0;
BA_REL_ "GenSigTimeoutTime" BU_SG_REL_ RRPSM SG_ 639 ATS_RRReadingModBtnSTD 0;
BA_REL_ "GenSigTimeoutTime" BU_SG_REL_ CGW_CCU SG_ 639 ATS_RRReadingModBtnSTD 0;
BA_ "NetworkRequest" SG_ 639 ATS_RRReadingModBtnSTD 0;
BA_ "NetworkRequestHoldingTime" SG_ 639 ATS_RRReadingModBtnSTD 5000;
BA_ "Version" SG_ 639 ATS_RRReadingModBtnSTD "20.07.01";
BA_ "Description" SG_ 639 ATS_RLRestModBtnSTD "Rear Left Rest Mode Touch Button (EXCEPT North America)";
BA_ "GenSigSendType" SG_ 639 ATS_RLRestModBtnSTD 4;
BA_ "UserSigValidity" SG_ 639 ATS_RLRestModBtnSTD 3;
BA_REL_ "GenSigTimeoutTime" BU_SG_REL_ PSM SG_ 639 ATS_RLRestModBtnSTD 0;
BA_REL_ "GenSigTimeoutTime" BU_SG_REL_ RLPSM SG_ 639 ATS_RLRestModBtnSTD 0;
BA_ "NetworkRequest" SG_ 639 ATS_RLRestModBtnSTD 0;
BA_ "NetworkRequestHoldingTime" SG_ 639 ATS_RLRestModBtnSTD 5000;
BA_ "Version" SG_ 639 ATS_RLRestModBtnSTD "20.07.01";
BA_ "Description" SG_ 639 ATS_RLResetModBtnSTD "Rear Left Return Mode Touch Button (EXCEPT North America)";
BA_ "GenSigSendType" SG_ 639 ATS_RLResetModBtnSTD 4;
BA_ "UserSigValidity" SG_ 639 ATS_RLResetModBtnSTD 3;
BA_REL_ "GenSigTimeoutTime" BU_SG_REL_ PSM SG_ 639 ATS_RLResetModBtnSTD 0;
BA_REL_ "GenSigTimeoutTime" BU_SG_REL_ RLPSM SG_ 639 ATS_RLResetModBtnSTD 0;
BA_ "NetworkRequest" SG_ 639 ATS_RLResetModBtnSTD 0;
BA_ "NetworkRequestHoldingTime" SG_ 639 ATS_RLResetModBtnSTD 5000;
BA_ "Version" SG_ 639 ATS_RLResetModBtnSTD "20.07.01";
BA_ "Description" SG_ 639 ATS_RRModestateStopBtn "Rear Right One touch mode Stop Button";
BA_ "GenSigSendType" SG_ 639 ATS_RRModestateStopBtn 4;
BA_ "UserSigValidity" SG_ 639 ATS_RRModestateStopBtn 3;
BA_REL_ "GenSigTimeoutTime" BU_SG_REL_ APSM SG_ 639 ATS_RRModestateStopBtn 0;
BA_REL_ "GenSigTimeoutTime" BU_SG_REL_ RRPSM SG_ 639 ATS_RRModestateStopBtn 0;
BA_ "NetworkRequest" SG_ 639 ATS_RRModestateStopBtn 0;
BA_ "NetworkRequestHoldingTime" SG_ 639 ATS_RRModestateStopBtn 5000;
BA_ "Version" SG_ 639 ATS_RRModestateStopBtn "20.07.01";
BA_ "Description" SG_ 639 ATS_RLModestateStopBtn "Rear Left One touch mode Stop Button";
BA_ "GenSigSendType" SG_ 639 ATS_RLModestateStopBtn 4;
BA_ "UserSigValidity" SG_ 639 ATS_RLModestateStopBtn 3;
BA_REL_ "GenSigTimeoutTime" BU_SG_REL_ PSM SG_ 639 ATS_RLModestateStopBtn 0;
BA_REL_ "GenSigTimeoutTime" BU_SG_REL_ RLPSM SG_ 639 ATS_RLModestateStopBtn 0;
BA_ "NetworkRequest" SG_ 639 ATS_RLModestateStopBtn 0;
BA_ "NetworkRequestHoldingTime" SG_ 639 ATS_RLModestateStopBtn 5000;
BA_ "Version" SG_ 639 ATS_RLModestateStopBtn "20.07.01";
BA_ "Description" SG_ 639 ATS_RLResetRestBtn "Rear Left Rest Mode Custom Initialization Button (Except North America)";
BA_ "GenSigSendType" SG_ 639 ATS_RLResetRestBtn 4;
BA_ "UserSigValidity" SG_ 639 ATS_RLResetRestBtn 3;
BA_REL_ "GenSigTimeoutTime" BU_SG_REL_ PSM SG_ 639 ATS_RLResetRestBtn 0;
BA_REL_ "GenSigTimeoutTime" BU_SG_REL_ RLPSM SG_ 639 ATS_RLResetRestBtn 0;
BA_ "NetworkRequest" SG_ 639 ATS_RLResetRestBtn 0;
BA_ "NetworkRequestHoldingTime" SG_ 639 ATS_RLResetRestBtn 5000;
BA_ "Version" SG_ 639 ATS_RLResetRestBtn "21.01.02";
BA_ "Description" SG_ 639 ATS_RLResetReturnBtn "Rear Left Return Mode Custom Initialization Button (Except North America)";
BA_ "GenSigSendType" SG_ 639 ATS_RLResetReturnBtn 4;
BA_ "UserSigValidity" SG_ 639 ATS_RLResetReturnBtn 3;
BA_REL_ "GenSigTimeoutTime" BU_SG_REL_ PSM SG_ 639 ATS_RLResetReturnBtn 0;
BA_REL_ "GenSigTimeoutTime" BU_SG_REL_ RLPSM SG_ 639 ATS_RLResetReturnBtn 0;
BA_ "NetworkRequest" SG_ 639 ATS_RLResetReturnBtn 0;
BA_ "NetworkRequestHoldingTime" SG_ 639 ATS_RLResetReturnBtn 5000;
BA_ "Version" SG_ 639 ATS_RLResetReturnBtn "21.01.02";
BA_ "Description" SG_ 639 ATS_RRResetRestBtn "Rear Right Rest Mode Custom Initialization Button (Except North America)";
BA_ "GenSigSendType" SG_ 639 ATS_RRResetRestBtn 4;
BA_ "UserSigValidity" SG_ 639 ATS_RRResetRestBtn 3;
BA_REL_ "GenSigTimeoutTime" BU_SG_REL_ APSM SG_ 639 ATS_RRResetRestBtn 0;
BA_REL_ "GenSigTimeoutTime" BU_SG_REL_ RRPSM SG_ 639 ATS_RRResetRestBtn 0;
BA_ "NetworkRequest" SG_ 639 ATS_RRResetRestBtn 0;
BA_ "NetworkRequestHoldingTime" SG_ 639 ATS_RRResetRestBtn 5000;
BA_ "Version" SG_ 639 ATS_RRResetRestBtn "21.01.02";
BA_ "Description" SG_ 639 ATS_RRResetReturnBtn "Rear Right Return Mode Custom Initialization Button (Except North America)";
BA_ "GenSigSendType" SG_ 639 ATS_RRResetReturnBtn 4;
BA_ "UserSigValidity" SG_ 639 ATS_RRResetReturnBtn 3;
BA_REL_ "GenSigTimeoutTime" BU_SG_REL_ APSM SG_ 639 ATS_RRResetReturnBtn 0;
BA_REL_ "GenSigTimeoutTime" BU_SG_REL_ RRPSM SG_ 639 ATS_RRResetReturnBtn 0;
BA_ "NetworkRequest" SG_ 639 ATS_RRResetReturnBtn 0;
BA_ "NetworkRequestHoldingTime" SG_ 639 ATS_RRResetReturnBtn 5000;
BA_ "Version" SG_ 639 ATS_RRResetReturnBtn "21.01.02";
BA_ "Description" SG_ 639 ATS_RRResetAvWtcBtn "Rear Right AV Watching Mode Custom Initialization Button (Except North America)";
BA_ "GenSigSendType" SG_ 639 ATS_RRResetAvWtcBtn 4;
BA_ "UserSigValidity" SG_ 639 ATS_RRResetAvWtcBtn 3;
BA_REL_ "GenSigTimeoutTime" BU_SG_REL_ APSM SG_ 639 ATS_RRResetAvWtcBtn 0;
BA_REL_ "GenSigTimeoutTime" BU_SG_REL_ RRPSM SG_ 639 ATS_RRResetAvWtcBtn 0;
BA_ "NetworkRequest" SG_ 639 ATS_RRResetAvWtcBtn 0;
BA_ "NetworkRequestHoldingTime" SG_ 639 ATS_RRResetAvWtcBtn 5000;
BA_ "Version" SG_ 639 ATS_RRResetAvWtcBtn "21.01.02";
BA_ "Description" SG_ 639 ATS_RRResetReadingBtn "Rear Right Reading Mode Custom Initialization Button (Except North America)";
BA_ "GenSigSendType" SG_ 639 ATS_RRResetReadingBtn 4;
BA_ "UserSigValidity" SG_ 639 ATS_RRResetReadingBtn 3;
BA_REL_ "GenSigTimeoutTime" BU_SG_REL_ APSM SG_ 639 ATS_RRResetReadingBtn 0;
BA_REL_ "GenSigTimeoutTime" BU_SG_REL_ RRPSM SG_ 639 ATS_RRResetReadingBtn 0;
BA_ "NetworkRequest" SG_ 639 ATS_RRResetReadingBtn 0;
BA_ "NetworkRequestHoldingTime" SG_ 639 ATS_RRResetReadingBtn 5000;
BA_ "Version" SG_ 639 ATS_RRResetReadingBtn "21.01.02";
BA_ "Description" SG_ 639 ATS_RRSeatHeaterUpSW "후석 RH 시트 열선 조절";
BA_ "GenSigSendType" SG_ 639 ATS_RRSeatHeaterUpSW 4;
BA_ "UserSigValidity" SG_ 639 ATS_RRSeatHeaterUpSW 3;
BA_REL_ "GenSigTimeoutTime" BU_SG_REL_ RLHV SG_ 639 ATS_RRSeatHeaterUpSW 0;
BA_REL_ "GenSigTimeoutTime" BU_SG_REL_ RLPSM SG_ 639 ATS_RRSeatHeaterUpSW 0;
BA_REL_ "GenSigTimeoutTime" BU_SG_REL_ RRHV SG_ 639 ATS_RRSeatHeaterUpSW 0;
BA_REL_ "GenSigTimeoutTime" BU_SG_REL_ RRPSM SG_ 639 ATS_RRSeatHeaterUpSW 0;
BA_ "NetworkRequest" SG_ 639 ATS_RRSeatHeaterUpSW 0;
BA_ "NetworkRequestHoldingTime" SG_ 639 ATS_RRSeatHeaterUpSW 5000;
BA_ "Version" SG_ 639 ATS_RRSeatHeaterUpSW "20.12.04";
BA_ "GenMsgSendType" BO_ 1050 0;
BA_ "Description" SG_ 1050 BCM_Crc7Val "The data area for CRC calculation is based on the data length (DLC) of the message DB.

The CRC shall be calculated over the entire data block (excluding the CRC bytes) including the user data, alive counter and Data ID 

 

- CRC Polynomial (0x1D) , Initial Value : 0x00, XOR value : 0xFF, Data ID Mode : Both, Data ID : Message ID + 0xF800 

- The initial value is for CRC calculation and the message should be sent with the calculated result value. 

The mathematical expression to 8 bit CRC polynomial is given here. G(x) = x8 + x4 + x3 + x2 + 1";
BA_ "GenSigSendType" SG_ 1050 BCM_Crc7Val 4;
BA_ "GenSigStartValue" SG_ 1050 BCM_Crc7Val 255;
BA_ "UserSigValidity" SG_ 1050 BCM_Crc7Val 0;
BA_ "Version" SG_ 1050 BCM_Crc7Val "18.11.08";
BA_ "Description" SG_ 1050 BCM_AlvCnt7Val "For the first transmission request for a data element the counter shall be initialized with 0 and shall be incremented by 1

for every subsequent send request. When the counter reaches the maximum value(0xE), then it shall restart with 0 for the next send request";
BA_ "GenSigSendType" SG_ 1050 BCM_AlvCnt7Val 4;
BA_ "UserSigValidity" SG_ 1050 BCM_AlvCnt7Val 0;
BA_ "Version" SG_ 1050 BCM_AlvCnt7Val "18.11.08";
BA_ "Description" SG_ 1050 Lamp_HiPrioHzrdReq "-Higher priority than SJB hazard

-Diag/Arm/DisArm/Balarm/Panic/MTS

-Initial Value: 2";
BA_ "GenSigSendType" SG_ 1050 Lamp_HiPrioHzrdReq 4;
BA_ "GenSigStartValue" SG_ 1050 Lamp_HiPrioHzrdReq 2;
BA_ "UserSigValidity" SG_ 1050 Lamp_HiPrioHzrdReq 0;
BA_ "NetworkRequest" SG_ 1050 Lamp_HiPrioHzrdReq 0;
BA_ "NetworkRequestHoldingTime" SG_ 1050 Lamp_HiPrioHzrdReq 5000;
BA_ "Version" SG_ 1050 Lamp_HiPrioHzrdReq "17.12.00";
BA_ "Description" SG_ 1050 Lamp_LoPrioHzrdReq "-Lower priority than SJB hazard

-TrunkOpenClose/CrashUnlock/RemoteStart

-Initial Value: 2";
BA_ "GenSigSendType" SG_ 1050 Lamp_LoPrioHzrdReq 4;
BA_ "GenSigStartValue" SG_ 1050 Lamp_LoPrioHzrdReq 2;
BA_ "UserSigValidity" SG_ 1050 Lamp_LoPrioHzrdReq 0;
BA_ "NetworkRequest" SG_ 1050 Lamp_LoPrioHzrdReq 0;
BA_ "NetworkRequestHoldingTime" SG_ 1050 Lamp_LoPrioHzrdReq 5000;
BA_ "Version" SG_ 1050 Lamp_LoPrioHzrdReq "17.12.00";
BA_ "Description" SG_ 1050 Lamp_DedicatedDrlOnReq "-Lamp on command for dedicated DRL headlamp";
BA_ "GenSigSendType" SG_ 1050 Lamp_DedicatedDrlOnReq 4;
BA_ "UserSigValidity" SG_ 1050 Lamp_DedicatedDrlOnReq 0;
BA_ "NetworkRequest" SG_ 1050 Lamp_DedicatedDrlOnReq 0;
BA_ "NetworkRequestHoldingTime" SG_ 1050 Lamp_DedicatedDrlOnReq 5000;
BA_ "Version" SG_ 1050 Lamp_DedicatedDrlOnReq "17.12.00";
BA_ "Description" SG_ 1050 Lamp_IntTailLmpOnReq "-(Old)C_INTTailOn";
BA_ "GenSigSendType" SG_ 1050 Lamp_IntTailLmpOnReq 4;
BA_ "UserSigValidity" SG_ 1050 Lamp_IntTailLmpOnReq 0;
BA_REL_ "GenSigTimeoutTime" BU_SG_REL_ RWPC SG_ 1050 Lamp_IntTailLmpOnReq 1500;
BA_ "NetworkRequest" SG_ 1050 Lamp_IntTailLmpOnReq 0;
BA_ "NetworkRequestHoldingTime" SG_ 1050 Lamp_IntTailLmpOnReq 5000;
BA_ "Version" SG_ 1050 Lamp_IntTailLmpOnReq "17.12.00";
BA_ "Description" SG_ 1050 Lamp_ExtrnlTailLmpOnReq "-(Old)C_EXTTailOn";
BA_ "GenSigSendType" SG_ 1050 Lamp_ExtrnlTailLmpOnReq 4;
BA_ "UserSigValidity" SG_ 1050 Lamp_ExtrnlTailLmpOnReq 0;
BA_ "NetworkRequest" SG_ 1050 Lamp_ExtrnlTailLmpOnReq 0;
BA_ "NetworkRequestHoldingTime" SG_ 1050 Lamp_ExtrnlTailLmpOnReq 5000;
BA_ "Version" SG_ 1050 Lamp_ExtrnlTailLmpOnReq "17.12.00";
BA_ "Description" SG_ 1050 Lamp_HdLmpLoOnReq "-(Old)C_HLampLowON";
BA_ "GenSigSendType" SG_ 1050 Lamp_HdLmpLoOnReq 4;
BA_ "UserSigValidity" SG_ 1050 Lamp_HdLmpLoOnReq 0;
BA_ "NetworkRequest" SG_ 1050 Lamp_HdLmpLoOnReq 0;
BA_ "NetworkRequestHoldingTime" SG_ 1050 Lamp_HdLmpLoOnReq 5000;
BA_ "Version" SG_ 1050 Lamp_HdLmpLoOnReq "17.12.00";
BA_ "Description" SG_ 1050 Lamp_HdLmpHiOnReq "-(Old)C_HLampHighON";
BA_ "GenSigSendType" SG_ 1050 Lamp_HdLmpHiOnReq 4;
BA_ "UserSigValidity" SG_ 1050 Lamp_HdLmpHiOnReq 0;
BA_ "NetworkRequest" SG_ 1050 Lamp_HdLmpHiOnReq 0;
BA_ "NetworkRequestHoldingTime" SG_ 1050 Lamp_HdLmpHiOnReq 5000;
BA_ "Version" SG_ 1050 Lamp_HdLmpHiOnReq "17.12.00";
BA_ "Description" SG_ 1050 Lamp_AvTailLmpSta "-Send with at the same time with C_IntTailOn

-Initiail Value: 1";
BA_ "GenSigSendType" SG_ 1050 Lamp_AvTailLmpSta 4;
BA_ "GenSigStartValue" SG_ 1050 Lamp_AvTailLmpSta 1;
BA_ "UserSigValidity" SG_ 1050 Lamp_AvTailLmpSta 0;
BA_REL_ "GenSigTimeoutTime" BU_SG_REL_ ATS SG_ 1050 Lamp_AvTailLmpSta 1500;
BA_ "NetworkRequest" SG_ 1050 Lamp_AvTailLmpSta 0;
BA_ "NetworkRequestHoldingTime" SG_ 1050 Lamp_AvTailLmpSta 5000;
BA_ "Version" SG_ 1050 Lamp_AvTailLmpSta "17.12.00";
BA_ "GenMsgSendType" BO_ 1052 0;
BA_ "Description" SG_ 1052 BCM_Crc9Val "The data area for CRC calculation is based on the data length (DLC) of the message DB.

The CRC shall be calculated over the entire data block (excluding the CRC bytes) including the user data, alive counter and Data ID 

 

- CRC Polynomial (0x1D) , Initial Value : 0x00, XOR value : 0xFF, Data ID Mode : Both, Data ID : Message ID + 0xF800 

- The initial value is for CRC calculation and the message should be sent with the calculated result value. 

The mathematical expression to 8 bit CRC polynomial is given here. G(x) = x8 + x4 + x3 + x2 + 1";
BA_ "GenSigSendType" SG_ 1052 BCM_Crc9Val 4;
BA_ "GenSigStartValue" SG_ 1052 BCM_Crc9Val 255;
BA_ "UserSigValidity" SG_ 1052 BCM_Crc9Val 0;
BA_ "Version" SG_ 1052 BCM_Crc9Val "18.11.08";
BA_ "Description" SG_ 1052 BCM_AlvCnt9Val "For the first transmission request for a data element the counter shall be initialized with 0 and shall be incremented by 1

for every subsequent send request. When the counter reaches the maximum value(0xE), then it shall restart with 0 for the next send request";
BA_ "GenSigSendType" SG_ 1052 BCM_AlvCnt9Val 4;
BA_ "UserSigValidity" SG_ 1052 BCM_AlvCnt9Val 0;
BA_ "Version" SG_ 1052 BCM_AlvCnt9Val "18.11.08";
BA_ "Description" SG_ 1052 Lamp_AutoLtSnsrNightSta "This signal indicates autolight sensor output";
BA_ "GenSigSendType" SG_ 1052 Lamp_AutoLtSnsrNightSta 4;
BA_ "GenSigStartValue" SG_ 1052 Lamp_AutoLtSnsrNightSta 1;
BA_ "UserSigValidity" SG_ 1052 Lamp_AutoLtSnsrNightSta 0;
BA_REL_ "GenSigTimeoutTime" BU_SG_REL_ ATS SG_ 1052 Lamp_AutoLtSnsrNightSta 1500;
BA_ "NetworkRequest" SG_ 1052 Lamp_AutoLtSnsrNightSta 0;
BA_ "NetworkRequestHoldingTime" SG_ 1052 Lamp_AutoLtSnsrNightSta 5000;
BA_ "Version" SG_ 1052 Lamp_AutoLtSnsrNightSta "20.04.06";
BA_ "Description" SG_ 1052 Lamp_VendorInfo "Rain seosor Vendor info (LIN to CAN signal)

- 001 : TRW(BCS)

- 010 : HELLA";
BA_ "GenSigSendType" SG_ 1052 Lamp_VendorInfo 4;
BA_ "GenSigStartValue" SG_ 1052 Lamp_VendorInfo 7;
BA_ "UserSigValidity" SG_ 1052 Lamp_VendorInfo 0;
BA_ "NetworkRequest" SG_ 1052 Lamp_VendorInfo 0;
BA_ "NetworkRequestHoldingTime" SG_ 1052 Lamp_VendorInfo 5000;
BA_ "Version" SG_ 1052 Lamp_VendorInfo "20.05.03";
BA_ "Description" SG_ 1052 Lamp_AutoLtSnsrHorVal "This signal indicates autolight sensor output (for HUD)";
BA_ "GenSigSendType" SG_ 1052 Lamp_AutoLtSnsrHorVal 4;
BA_ "UserSigValidity" SG_ 1052 Lamp_AutoLtSnsrHorVal 0;
BA_REL_ "GenSigTimeoutTime" BU_SG_REL_ ATS SG_ 1052 Lamp_AutoLtSnsrHorVal 1500;
BA_ "NetworkRequest" SG_ 1052 Lamp_AutoLtSnsrHorVal 0;
BA_ "NetworkRequestHoldingTime" SG_ 1052 Lamp_AutoLtSnsrHorVal 5000;
BA_ "Version" SG_ 1052 Lamp_AutoLtSnsrHorVal "17.12.00";
BA_ "Description" SG_ 1052 Lamp_AutoLtSnsrVerVal "This signal indicates autolight sensor output (for HUD)";
BA_ "GenSigSendType" SG_ 1052 Lamp_AutoLtSnsrVerVal 4;
BA_ "UserSigValidity" SG_ 1052 Lamp_AutoLtSnsrVerVal 0;
BA_ "NetworkRequest" SG_ 1052 Lamp_AutoLtSnsrVerVal 0;
BA_ "NetworkRequestHoldingTime" SG_ 1052 Lamp_AutoLtSnsrVerVal 5000;
BA_ "Version" SG_ 1052 Lamp_AutoLtSnsrVerVal "17.12.00";
BA_ "Description" SG_ 1052 Wiper_RainAmount "Amount of rain on windshield (LIN to CAN Signal)

- LIN Signal Name : VAL_RAIN_AMOUNT

- 0~150 : PH=0.5*HEX%

- 151~254 : Reserved

- 255 (1111 1111) : Invalid";
BA_ "GenSigSendType" SG_ 1052 Wiper_RainAmount 4;
BA_ "GenSigStartValue" SG_ 1052 Wiper_RainAmount 255;
BA_ "UserSigValidity" SG_ 1052 Wiper_RainAmount 0;
BA_ "NetworkRequest" SG_ 1052 Wiper_RainAmount 0;
BA_ "NetworkRequestHoldingTime" SG_ 1052 Wiper_RainAmount 5000;
BA_ "Version" SG_ 1052 Wiper_RainAmount "20.07.04";
BA_ "GenMsgSendType" BO_ 2424579841 0;
BA_ "VFrameFormat" BO_ 2424579841 1;
BA_ "Description" SG_ 2424579841 DATC_Crc11Val "The data area for CRC calculation is based on the data length (DLC) of the message DB.

The CRC shall be calculated over the entire data block (excluding the CRC bytes) including the user data, alive counter and Data ID

 

- CRC Polynomial (0x1021) , Initial Value : 0xFFFF, XOR value : 0x0000, Data ID : Message ID + 0xF800 

- The initial value is for CRC calculation and the message should be sent with the calculated result value. 

- The mathematical expression to 16 bit CRC polynomial is given here. G(x) = x16 + x12 + x5 + 1";
BA_ "GenSigSendType" SG_ 2424579841 DATC_Crc11Val 4;
BA_ "GenSigStartValue" SG_ 2424579841 DATC_Crc11Val 65535;
BA_ "UserSigValidity" SG_ 2424579841 DATC_Crc11Val 3;
BA_ "Version" SG_ 2424579841 DATC_Crc11Val "18.11.08";
BA_ "Description" SG_ 2424579841 DATC_AlvCnt11Val "For the first transmission request for a data element the counter shall be initialized with 0 and shall be incremented by 1 for every subsequent send request. 

When the counter reaches the maximum value(0xFF), then it shall restart with 0 for the next send request";
BA_ "GenSigSendType" SG_ 2424579841 DATC_AlvCnt11Val 4;
BA_ "UserSigValidity" SG_ 2424579841 DATC_AlvCnt11Val 3;
BA_ "Version" SG_ 2424579841 DATC_AlvCnt11Val "18.11.08";
BA_ "Description" SG_ 2424579841 DATC_TunnelFuncOff4AutoDfgReq "DATC Turn off Tunnel Function for ADS";
BA_ "GenSigSendType" SG_ 2424579841 DATC_TunnelFuncOff4AutoDfgReq 4;
BA_ "UserSigValidity" SG_ 2424579841 DATC_TunnelFuncOff4AutoDfgReq 7;
BA_ "Version" SG_ 2424579841 DATC_TunnelFuncOff4AutoDfgReq "17.11.00";
BA_ "Description" SG_ 2424579841 DATC_RrCtlLckSta "Rear Lock Status Informed  DATC  to AVN";
BA_ "GenSigSendType" SG_ 2424579841 DATC_RrCtlLckSta 4;
BA_ "UserSigValidity" SG_ 2424579841 DATC_RrCtlLckSta 7;
BA_REL_ "GenSigTimeoutTime" BU_SG_REL_ ATS SG_ 2424579841 DATC_RrCtlLckSta 1500;
BA_ "Version" SG_ 2424579841 DATC_RrCtlLckSta "17.11.00";
BA_ "Description" SG_ 2424579841 DATC_DrvrStHtrUSMSta "If the 'Auto Comfort Control' function is applied separately to the Seat and Steering Wheel, 

this signal is used.";
BA_ "GenSigSendType" SG_ 2424579841 DATC_DrvrStHtrUSMSta 4;
BA_ "UserSigValidity" SG_ 2424579841 DATC_DrvrStHtrUSMSta 7;
BA_REL_ "GenSigTimeoutTime" BU_SG_REL_ SHVU_RR SG_ 2424579841 DATC_DrvrStHtrUSMSta 1500;
BA_ "Version" SG_ 2424579841 DATC_DrvrStHtrUSMSta "17.11.00";
BA_ "Description" SG_ 2424579841 DATC_WshFldUSMSta "This signal indicate Washer Fulid USM State.";
BA_ "GenSigSendType" SG_ 2424579841 DATC_WshFldUSMSta 4;
BA_ "UserSigValidity" SG_ 2424579841 DATC_WshFldUSMSta 7;
BA_ "Version" SG_ 2424579841 DATC_WshFldUSMSta "18.06.00";
BA_ "Description" SG_ 2424579841 DATC_DfgLgcUSMSta "This signal indicates USM States of DefLogic

(DEF 해제복귀 로직 USM 설정값 송신 신호)";
BA_ "GenSigSendType" SG_ 2424579841 DATC_DfgLgcUSMSta 4;
BA_ "GenSigStartValue" SG_ 2424579841 DATC_DfgLgcUSMSta 3;
BA_ "UserSigValidity" SG_ 2424579841 DATC_DfgLgcUSMSta 3;
BA_ "Version" SG_ 2424579841 DATC_DfgLgcUSMSta "18.07.03";
BA_ "Description" SG_ 2424579841 DATC_AutoFrshUSMSta "This signal indicates USM States of Auto Fresh

(결로방지 해제 복귀 USM 설정 상태 송신 신호)";
BA_ "GenSigSendType" SG_ 2424579841 DATC_AutoFrshUSMSta 4;
BA_ "GenSigStartValue" SG_ 2424579841 DATC_AutoFrshUSMSta 3;
BA_ "UserSigValidity" SG_ 2424579841 DATC_AutoFrshUSMSta 3;
BA_ "Version" SG_ 2424579841 DATC_AutoFrshUSMSta "18.07.03";
BA_ "Description" SG_ 2424579841 DATC_HptIntnstySta "This signal indicate the Haptic Intensity of Touch Button in the Heater Control.";
BA_ "GenSigSendType" SG_ 2424579841 DATC_HptIntnstySta 4;
BA_ "UserSigValidity" SG_ 2424579841 DATC_HptIntnstySta 7;
BA_ "Version" SG_ 2424579841 DATC_HptIntnstySta "18.11.01";
BA_ "GenMsgSendType" BO_ 2307022849 0;
BA_ "GenMsgCycleTimeFast" BO_ 2307022849 0;
BA_ "GenMsgNrOfRepetition" BO_ 2307022849 0;
BA_ "VFrameFormat" BO_ 2307022849 1;
BA_ "Description" SG_ 2307022849 EMS_Crc5Val "The data area for CRC calculation is based on the data length (DLC) of the message DB.

The CRC shall be calculated over the entire data block (excluding the CRC bytes) including the user data, alive counter and Data ID

 

- CRC Polynomial (0x1021) , Initial Value : 0xFFFF, XOR value : 0x0000, Data ID : Message ID + 0xF800 

- The initial value is for CRC calculation and the message should be sent with the calculated result value. 

- The mathematical expression to 16 bit CRC polynomial is given here. G(x) = x16 + x12 + x5 + 1";
BA_ "GenSigStartValue" SG_ 2307022849 EMS_Crc5Val 65535;
BA_ "UserSigValidity" SG_ 2307022849 EMS_Crc5Val 3;
BA_ "RoutingFactor" SG_ 2307022849 EMS_Crc5Val 2;
BA_ "Version" SG_ 2307022849 EMS_Crc5Val "18.11.08";
BA_ "Description" SG_ 2307022849 EMS_AlvCnt5Val "For the first transmission request for a data element the counter shall be initialized with 0 and shall be incremented by 1 for every subsequent send request. 

When the counter reaches the maximum value(0xFF), then it shall restart with 0 for the next send request";
BA_ "UserSigValidity" SG_ 2307022849 EMS_AlvCnt5Val 3;
BA_ "RoutingFactor" SG_ 2307022849 EMS_AlvCnt5Val 2;
BA_ "Version" SG_ 2307022849 EMS_AlvCnt5Val "18.11.08";
BA_ "Description" SG_ 2307022849 ENG_ImmoLmpSta "This signals indicates that a status of Immobilizer lamp.";
BA_ "UserSigValidity" SG_ 2307022849 ENG_ImmoLmpSta 3;
BA_ "RoutingFactor" SG_ 2307022849 ENG_ImmoLmpSta 2;
BA_ "Version" SG_ 2307022849 ENG_ImmoLmpSta "17.12.00";
BA_ "Description" SG_ 2307022849 ENG_MilSta "The signal indicates the status of the 'Check Engine' light. Lamp activation is either effected statically or clocked (500 ms cycle, code sequence).

An evaluation within 10 ms is required to map the activation process as precisely as possible.

In case of a bus timeout, the value 1 has to be assumed.";
BA_ "UserSigValidity" SG_ 2307022849 ENG_MilSta 3;
BA_ "RoutingFactor" SG_ 2307022849 ENG_MilSta 2;
BA_ "Version" SG_ 2307022849 ENG_MilSta "17.12.00";
BA_ "Description" SG_ 2307022849 ENG_ImmoSta "Status of immobilizer.";
BA_ "UserSigValidity" SG_ 2307022849 ENG_ImmoSta 3;
BA_ "RoutingFactor" SG_ 2307022849 ENG_ImmoSta 2;
BA_ "Version" SG_ 2307022849 ENG_ImmoSta "17.12.00";
BA_ "Description" SG_ 2307022849 OBD_RbmInhbtSta "This variable is set to 1 if there is a malfunction of any component used to determine the standardized vehicle operations (i.e. vehicle speed, ambient temperature, elevation, idle operation, engine cold start, time of operation, etc.)

Calculations shall resume as soon as the malfunction is no longer present.

If this value is set to 1, the OBD II system shall disable all numerators and denominators calculations";
BA_ "UserSigValidity" SG_ 2307022849 OBD_RbmInhbtSta 3;
BA_ "RoutingFactor" SG_ 2307022849 OBD_RbmInhbtSta 2;
BA_ "Version" SG_ 2307022849 OBD_RbmInhbtSta "17.12.00";
BA_ "Description" SG_ 2307022849 ENG_AtmsphPrsrVal "The value AMP_CAN specifies the atmospheric pressure in the unit [mmHg]. It is calculated from the altitude correction factor MAF_FAC_ALTI_MMV. (Modeling Value)

However, when AMP sensor is equipped, the value AMP_CAN is calculated from the sensor output value.



The Hex-Limits for AMP_CAN are 0 ... 1FH (0 ... 31 dec; 5 Bit) and the physical output is limited to 458.98 ... 792.78 mmHg.



Calculation of AMP_CAN: 

AMP_CAN [hex] = ( MAF_FAC_ALTI_MMV [dec] - 77 [dec] ) * 0.5535714";
BA_ "GenSigStartValue" SG_ 2307022849 ENG_AtmsphPrsrVal 28;
BA_ "UserSigValidity" SG_ 2307022849 ENG_AtmsphPrsrVal 3;
BA_ "RoutingFactor" SG_ 2307022849 ENG_AtmsphPrsrVal 2;
BA_ "Version" SG_ 2307022849 ENG_AtmsphPrsrVal "17.12.00";
BA_ "Description" SG_ 2307022849 ENG_AltFdbckLoadVal "This signal is Filtered electrical load PWM signal from Alternator.

The FR signal duty cycle is an indication of the generator load. It can be used to increase the engine idle speed or calculate the torque consumption of the alternator.";
BA_ "GenSigStartValue" SG_ 2307022849 ENG_AltFdbckLoadVal 255;
BA_ "UserSigValidity" SG_ 2307022849 ENG_AltFdbckLoadVal 3;
BA_ "RoutingFactor" SG_ 2307022849 ENG_AltFdbckLoadVal 2;
BA_ "Version" SG_ 2307022849 ENG_AltFdbckLoadVal "17.12.00";
BA_ "Description" SG_ 2307022849 ENG_BattVoltVal "The battery voltage after main relay is transferred.";
BA_ "UserSigValidity" SG_ 2307022849 ENG_BattVoltVal 3;
BA_ "RoutingFactor" SG_ 2307022849 ENG_BattVoltVal 2;
BA_ "Version" SG_ 2307022849 ENG_BattVoltVal "17.12.00";
BA_ "Description" SG_ 2307022849 ENG_FuelTempVal "Fuel temperature in EMS sensed via an A/D converter; converted into degrees centigrade (°C).";
BA_ "GenSigStartValue" SG_ 2307022849 ENG_FuelTempVal 255;
BA_ "UserSigValidity" SG_ 2307022849 ENG_FuelTempVal 3;
BA_ "RoutingFactor" SG_ 2307022849 ENG_FuelTempVal 2;
BA_ "Version" SG_ 2307022849 ENG_FuelTempVal "17.12.00";
BA_ "GenMsgSendType" BO_ 2307022850 0;
BA_ "GenMsgCycleTimeFast" BO_ 2307022850 0;
BA_ "GenMsgNrOfRepetition" BO_ 2307022850 0;
BA_ "VFrameFormat" BO_ 2307022850 1;
BA_ "Description" SG_ 2307022850 SCC_DrvOvrRidSta "This signal provides bit information whether the demand torque by the driver is higher than the torque requested by SCC system or not. This signal should be set by an engine control system only if the acceleration pedal is actuated by the driver (so that a failure can be avoided when SCC demands loss torque).";
BA_ "UserSigValidity" SG_ 2307022850 SCC_DrvOvrRidSta 3;
BA_ "RoutingFactor" SG_ 2307022850 SCC_DrvOvrRidSta 2;
BA_ "Version" SG_ 2307022850 SCC_DrvOvrRidSta "17.12.00";
BA_ "Description" SG_ 2307022850 ISA_IsaFuncSta "This signal indicates that if ISA function is active or not.

If ISA function is activated then CF_Ems_IsaAct = 1. Although “ISA Main” switch is on, if the ISA function is deactivated then CF_Ems_IsaAct should be set to ‘0’.";
BA_ "UserSigValidity" SG_ 2307022850 ISA_IsaFuncSta 3;
BA_ "RoutingFactor" SG_ 2307022850 ISA_IsaFuncSta 2;
BA_ "Version" SG_ 2307022850 ISA_IsaFuncSta "17.12.00";
BA_ "Description" SG_ 2307022850 SCC_StrtLimFuncSta "This Signal is Start Limitation Function operation bit

0x0: No Start Limitation function operation

0x1: Start Limitation function operation";
BA_ "UserSigValidity" SG_ 2307022850 SCC_StrtLimFuncSta 3;
BA_ "RoutingFactor" SG_ 2307022850 SCC_StrtLimFuncSta 2;
BA_ "Version" SG_ 2307022850 SCC_StrtLimFuncSta "17.12.00";
BA_ "Description" SG_ 2307022850 EMS_SafetyFunctSta "This signal is Safety function operation bit.";
BA_ "UserSigValidity" SG_ 2307022850 EMS_SafetyFunctSta 3;
BA_ "RoutingFactor" SG_ 2307022850 EMS_SafetyFunctSta 2;
BA_ "Version" SG_ 2307022850 EMS_SafetyFunctSta "18.01.01";
BA_ "Description" SG_ 2307022850 InAirTempVal "IntAirTemp indicates intake air temperature of an engine.

A TCU controls oil pressure during gear shifting and also changes an air-con load compensation factor using this signal.";
BA_ "UserSigValidity" SG_ 2307022850 InAirTempVal 3;
BA_ "RoutingFactor" SG_ 2307022850 InAirTempVal 2;
BA_ "Version" SG_ 2307022850 InAirTempVal "18.01.01";
BA_ "Description" SG_ 2307022850 SCC_SccFlrDetSta "When it is set, the signal indicates that EMS cannot accept the engine torque request for SCC, TQI_ACC, because of a failure or failures in EMS which may be recovered within the same ignition cycle. EMS stores DTC for the failure.

In case that there is no failure or the failure is cleared, the signal gets reset.";
BA_ "UserSigValidity" SG_ 2307022850 SCC_SccFlrDetSta 3;
BA_ "RoutingFactor" SG_ 2307022850 SCC_SccFlrDetSta 2;
BA_ "Version" SG_ 2307022850 SCC_SccFlrDetSta "17.12.00";
BA_ "Description" SG_ 2307022850 OBD_RbmSta "For the calculation of the denominators for Rate-Based Monitoring(RBM), CARB defined the standardized vehicle operations, which must be met to increment the denominator counter.

So, this variable is to give a status information(fulfilled or not) about all conditions for the standardized

vehicle operations.



Bit0 : Minimum trip length condition

Bit1 : Vehicle speed condition

Bit2 : Continuous idle condition

Bit3 : Ambient temperature condition

Bit4 : Maximum altitude condition

Bit5 : Reserved

Bit6 : Reserved";
BA_ "UserSigValidity" SG_ 2307022850 OBD_RbmSta 3;
BA_ "RoutingFactor" SG_ 2307022850 OBD_RbmSta 2;
BA_ "Version" SG_ 2307022850 OBD_RbmSta "17.12.00";
BA_ "Description" SG_ 2307022850 AAF_WrnLamp "Air Flap Warning Lamp/Message Request Signal indicates whether Warning Lamp/Message should be displayed in the display screen in order to warn AAF System failure to customer.";
BA_ "UserSigValidity" SG_ 2307022850 AAF_WrnLamp 4;
BA_ "RoutingFactor" SG_ 2307022850 AAF_WrnLamp 2;
BA_ "Version" SG_ 2307022850 AAF_WrnLamp "18.08.02";
BA_ "Description" SG_ 2307022850 OBD_IgnCycCntVal "Number of driving cycle since first ECU power-up.

The counter is incremented each time a driving cycle with engine running for a specified time duration is detected. This value is only initialized with 0 on saved RAM lost (or reprogramming).

Signal value will be reset to '0' after max-range value (65535)";
BA_ "UserSigValidity" SG_ 2307022850 OBD_IgnCycCntVal 3;
BA_ "RoutingFactor" SG_ 2307022850 OBD_IgnCycCntVal 2;
BA_ "Version" SG_ 2307022850 OBD_IgnCycCntVal "17.12.00";
BA_ "Description" SG_ 2307022850 SCC_FuncFlrDetSta "When it is set, the signal indicates that EMS cannot accept the engine torque request for SCC, TQI_ACC, because of a failure or failures in EMS which cannot be recovered within the same ignition cycle. EMS stores DTC for the failure.

In case that there is no failure, the signal gets reset.";
BA_ "UserSigValidity" SG_ 2307022850 SCC_FuncFlrDetSta 3;
BA_ "RoutingFactor" SG_ 2307022850 SCC_FuncFlrDetSta 2;
BA_ "Version" SG_ 2307022850 SCC_FuncFlrDetSta "17.12.00";
BA_ "Description" SG_ 2307022850 OBD_DnmntrCalcVal "The counter for the general denominator CTR_CDN_OBD is incremented each time a valid driving cycle with standardized vehicle operation is recognized. 

The numbers of driving cycles are counted since the first ECU power up. This value is only initialized with 0 on saved RAM lost (or reprogramming).";
BA_ "UserSigValidity" SG_ 2307022850 OBD_DnmntrCalcVal 3;
BA_ "RoutingFactor" SG_ 2307022850 OBD_DnmntrCalcVal 2;
BA_ "Version" SG_ 2307022850 OBD_DnmntrCalcVal "17.12.00";
BA_ "Description" SG_ 2307022850 SCC_SccOffStaDetSta "When it is set, the signal indicates that EMS cannot accept the engine torque request for SCC, TQI_ACC, but it is not related any failures in EMS. Therefore, EMS does not store DTC.

In case that the condition is cleared, the signal gets reset.";
BA_ "UserSigValidity" SG_ 2307022850 SCC_SccOffStaDetSta 3;
BA_ "RoutingFactor" SG_ 2307022850 SCC_SccOffStaDetSta 2;
BA_ "Version" SG_ 2307022850 SCC_SccOffStaDetSta "17.12.00";
BA_ "Description" SG_ 2307022850 SCC_BrkLtSwFlrDetSta "Failure signal to SCC when a failure occurs in the brake light switch acquisition of engine control";
BA_ "UserSigValidity" SG_ 2307022850 SCC_BrkLtSwFlrDetSta 3;
BA_ "RoutingFactor" SG_ 2307022850 SCC_BrkLtSwFlrDetSta 2;
BA_ "Version" SG_ 2307022850 SCC_BrkLtSwFlrDetSta "17.12.00";
BA_ "GenMsgSendType" BO_ 2307022851 0;
BA_ "GenMsgCycleTimeFast" BO_ 2307022851 0;
BA_ "GenMsgNrOfRepetition" BO_ 2307022851 0;
BA_ "VFrameFormat" BO_ 2307022851 1;
BA_ "Description" SG_ 2307022851 ENG_TransmsnTyp "A/T or M/T information generated by automatic variant coding.

A/T information is got from the “TCU_TYPE” signal of TCU1 message. (See TCU1 message information)";
BA_ "UserSigValidity" SG_ 2307022851 ENG_TransmsnTyp 3;
BA_ "RoutingFactor" SG_ 2307022851 ENG_TransmsnTyp 2;
BA_ "Version" SG_ 2307022851 ENG_TransmsnTyp "17.11.00";
BA_ "Description" SG_ 2307022851 ENG_IsgEquipped "Information if ISG is equipped or not in the vehicle.

Auto Stop related information display page at CLU is activated dependinng on this signal.";
BA_ "UserSigValidity" SG_ 2307022851 ENG_IsgEquipped 3;
BA_ "RoutingFactor" SG_ 2307022851 ENG_IsgEquipped 2;
BA_ "Version" SG_ 2307022851 ENG_IsgEquipped "19.05.02";
BA_ "Description" SG_ 2307022851 ENG_EngDsplceTyp "This signal indicates the engine displacement (volume).";
BA_ "UserSigValidity" SG_ 2307022851 ENG_EngDsplceTyp 3;
BA_REL_ "GenSigTimeoutTime" BU_SG_REL_ AMP SG_ 2307022851 ENG_EngDsplceTyp 1500;
BA_ "RoutingFactor" SG_ 2307022851 ENG_EngDsplceTyp 2;
BA_ "Version" SG_ 2307022851 ENG_EngDsplceTyp "17.12.00";
BA_ "GenMsgCycleTime" BO_ 2563127553 0;
BA_ "VFrameFormat" BO_ 2563127553 1;
BA_ "GenSigSendType" SG_ 2563127553 AMP_CabinTalkVolumeStep 4;
BA_ "GenSigStartValue" SG_ 2563127553 AMP_CabinTalkVolumeStep 255;
BA_ "UserSigValidity" SG_ 2563127553 AMP_CabinTalkVolumeStep 1;
BA_ "Version" SG_ 2563127553 AMP_CabinTalkVolumeStep "18.12.06";
BA_ "Description" SG_ 2563127553 DATC_Beep1VolumeStep "Command for DATC Touch Beep Sound Volume Setting 

-range : 0 ~ max

-max : value of AMP_MaxBeep1VolumeState

-This Signal's Feedback is DATC_Beep1VolumeState@AMP";
BA_ "GenSigSendType" SG_ 2563127553 DATC_Beep1VolumeStep 4;
BA_ "GenSigStartValue" SG_ 2563127553 DATC_Beep1VolumeStep 255;
BA_ "UserSigValidity" SG_ 2563127553 DATC_Beep1VolumeStep 1;
BA_REL_ "GenSigTimeoutTime" BU_SG_REL_ AMP SG_ 2563127553 DATC_Beep1VolumeStep 0;
BA_ "Version" SG_ 2563127553 DATC_Beep1VolumeStep "20.03.03";
BA_ "Description" SG_ 2563127553 DATC_Beep1Frequency "Command for Touch Beep Sound Frequency Setting of DATC

-range : 20 Hz ~ 20000Hz";
BA_ "GenSigSendType" SG_ 2563127553 DATC_Beep1Frequency 4;
BA_ "GenSigStartValue" SG_ 2563127553 DATC_Beep1Frequency 65535;
BA_ "UserSigValidity" SG_ 2563127553 DATC_Beep1Frequency 1;
BA_REL_ "GenSigTimeoutTime" BU_SG_REL_ AMP SG_ 2563127553 DATC_Beep1Frequency 0;
BA_ "Version" SG_ 2563127553 DATC_Beep1Frequency "20.03.03";
BA_ "Description" SG_ 2563127553 DATC_Beep1_OutputCh_Select "Command for Set Beep1 Output Channel to identify which Speakers will output Sound

- per bit, 0 means 'Not Output Channel' and 1 means 'Output Channel'

bit0 : FL / bit1 : FR / bit2 : RL / bit3 : RR / bit4 : CTR / bit5 : Surround L /

bit6 : Surround R / bit7 : SWF / bit8 : Headrest L / bit9 : Headrest R / bit10 : Loof L /

bit11 : Loof CTR / bit12 : Loof R / bit13~bit15 : Reserved

- This Signal's Feedback is DATC_Beep1_OutputCh_State@AMP";
BA_ "GenSigSendType" SG_ 2563127553 DATC_Beep1_OutputCh_Select 4;
BA_ "GenSigStartValue" SG_ 2563127553 DATC_Beep1_OutputCh_Select 65535;
BA_ "UserSigValidity" SG_ 2563127553 DATC_Beep1_OutputCh_Select 1;
BA_REL_ "GenSigTimeoutTime" BU_SG_REL_ AMP SG_ 2563127553 DATC_Beep1_OutputCh_Select 0;
BA_ "Version" SG_ 2563127553 DATC_Beep1_OutputCh_Select "20.03.03";
BA_ "GenMsgCycleTime" BO_ 2458165761 0;
BA_ "VFrameFormat" BO_ 2458165761 1;
BA_ "GenSigSendType" SG_ 2458165761 C_HazardFromIBOX 4;
BA_ "UserSigValidity" SG_ 2458165761 C_HazardFromIBOX 0;
BA_ "NetworkRequest" SG_ 2458165761 C_HazardFromIBOX 0;
BA_ "NetworkRequestHoldingTime" SG_ 2458165761 C_HazardFromIBOX 2000;
BA_ "Version" SG_ 2458165761 C_HazardFromIBOX "19.07.01";
BA_ "GenSigSendType" SG_ 2458165761 C_RemoteWdwCMDHU 4;
BA_ "GenSigStartValue" SG_ 2458165761 C_RemoteWdwCMDHU 3;
BA_ "UserSigValidity" SG_ 2458165761 C_RemoteWdwCMDHU 0;
BA_ "Version" SG_ 2458165761 C_RemoteWdwCMDHU "18.10.05";
BA_ "GenSigSendType" SG_ 2458165761 C_EsyAcsProfileID_HU 4;
BA_ "UserSigValidity" SG_ 2458165761 C_EsyAcsProfileID_HU 0;
BA_REL_ "GenSigTimeoutTime" BU_SG_REL_ PSM SG_ 2458165761 C_EsyAcsProfileID_HU 0;
BA_ "Version" SG_ 2458165761 C_EsyAcsProfileID_HU "18.09.04";
BA_ "GenSigSendType" SG_ 2458165761 C_TeleStrgWhlHeatingCmdIBOX 4;
BA_ "GenSigStartValue" SG_ 2458165761 C_TeleStrgWhlHeatingCmdIBOX 3;
BA_ "UserSigValidity" SG_ 2458165761 C_TeleStrgWhlHeatingCmdIBOX 0;
BA_ "NetworkRequest" SG_ 2458165761 C_TeleStrgWhlHeatingCmdIBOX 0;
BA_ "Version" SG_ 2458165761 C_TeleStrgWhlHeatingCmdIBOX "18.09.04";
BA_ "GenSigSendType" SG_ 2458165761 C_TeleDefoggerHeatingCmdIBOX 4;
BA_ "GenSigStartValue" SG_ 2458165761 C_TeleDefoggerHeatingCmdIBOX 3;
BA_ "UserSigValidity" SG_ 2458165761 C_TeleDefoggerHeatingCmdIBOX 0;
BA_ "NetworkRequest" SG_ 2458165761 C_TeleDefoggerHeatingCmdIBOX 0;
BA_ "Version" SG_ 2458165761 C_TeleDefoggerHeatingCmdIBOX "18.09.04";
BA_ "Description" SG_ 2458165761 HU_ICU_RearDefSet "Rear window defog control";
BA_ "GenSigSendType" SG_ 2458165761 HU_ICU_RearDefSet 4;
BA_ "GenSigStartValue" SG_ 2458165761 HU_ICU_RearDefSet 3;
BA_ "UserSigValidity" SG_ 2458165761 HU_ICU_RearDefSet 3;
BA_ "Version" SG_ 2458165761 HU_ICU_RearDefSet "20.01.02";
BA_ "GenSigSendType" SG_ 2458165761 C_PanicFromIBOX 4;
BA_ "UserSigValidity" SG_ 2458165761 C_PanicFromIBOX 0;
BA_ "NetworkRequest" SG_ 2458165761 C_PanicFromIBOX 0;
BA_ "NetworkRequestHoldingTime" SG_ 2458165761 C_PanicFromIBOX 2000;
BA_ "Version" SG_ 2458165761 C_PanicFromIBOX "19.07.01";
BA_ "GenSigSendType" SG_ 2458165761 C_PreCrankReq 4;
BA_ "UserSigValidity" SG_ 2458165761 C_PreCrankReq 0;
BA_ "NetworkRequest" SG_ 2458165761 C_PreCrankReq 0;
BA_ "Version" SG_ 2458165761 C_PreCrankReq "18.09.04";
BA_ "GenSigSendType" SG_ 2458165761 C_TeleAstSeatOpCmdIBOX 4;
BA_ "UserSigValidity" SG_ 2458165761 C_TeleAstSeatOpCmdIBOX 3;
BA_REL_ "GenSigTimeoutTime" BU_SG_REL_ PSM SG_ 2458165761 C_TeleAstSeatOpCmdIBOX 0;
BA_REL_ "GenSigTimeoutTime" BU_SG_REL_ APSM SG_ 2458165761 C_TeleAstSeatOpCmdIBOX 0;
BA_ "Version" SG_ 2458165761 C_TeleAstSeatOpCmdIBOX "18.09.04";
BA_ "GenSigSendType" SG_ 2458165761 C_TeleDrvSeatOpCmdIBOX 4;
BA_ "UserSigValidity" SG_ 2458165761 C_TeleDrvSeatOpCmdIBOX 3;
BA_REL_ "GenSigTimeoutTime" BU_SG_REL_ PSM SG_ 2458165761 C_TeleDrvSeatOpCmdIBOX 0;
BA_REL_ "GenSigTimeoutTime" BU_SG_REL_ APSM SG_ 2458165761 C_TeleDrvSeatOpCmdIBOX 0;
BA_ "Version" SG_ 2458165761 C_TeleDrvSeatOpCmdIBOX "18.09.04";
BA_ "GenSigSendType" SG_ 2458165761 C_TeleRRSeatOpCmdIBOX 4;
BA_ "UserSigValidity" SG_ 2458165761 C_TeleRRSeatOpCmdIBOX 3;
BA_REL_ "GenSigTimeoutTime" BU_SG_REL_ RLPSM SG_ 2458165761 C_TeleRRSeatOpCmdIBOX 0;
BA_REL_ "GenSigTimeoutTime" BU_SG_REL_ RRPSM SG_ 2458165761 C_TeleRRSeatOpCmdIBOX 0;
BA_REL_ "GenSigTimeoutTime" BU_SG_REL_ RLHV SG_ 2458165761 C_TeleRRSeatOpCmdIBOX 0;
BA_REL_ "GenSigTimeoutTime" BU_SG_REL_ RRHV SG_ 2458165761 C_TeleRRSeatOpCmdIBOX 0;
BA_REL_ "GenSigTimeoutTime" BU_SG_REL_ SHVU_RR SG_ 2458165761 C_TeleRRSeatOpCmdIBOX 0;
BA_REL_ "GenSigTimeoutTime" BU_SG_REL_ ATS SG_ 2458165761 C_TeleRRSeatOpCmdIBOX 0;
BA_ "Version" SG_ 2458165761 C_TeleRRSeatOpCmdIBOX "18.09.04";
BA_ "GenSigSendType" SG_ 2458165761 C_TeleRLSeatOpCmdIBOX 4;
BA_ "UserSigValidity" SG_ 2458165761 C_TeleRLSeatOpCmdIBOX 3;
BA_REL_ "GenSigTimeoutTime" BU_SG_REL_ RLPSM SG_ 2458165761 C_TeleRLSeatOpCmdIBOX 0;
BA_REL_ "GenSigTimeoutTime" BU_SG_REL_ RRPSM SG_ 2458165761 C_TeleRLSeatOpCmdIBOX 0;
BA_REL_ "GenSigTimeoutTime" BU_SG_REL_ RLHV SG_ 2458165761 C_TeleRLSeatOpCmdIBOX 0;
BA_REL_ "GenSigTimeoutTime" BU_SG_REL_ RRHV SG_ 2458165761 C_TeleRLSeatOpCmdIBOX 0;
BA_REL_ "GenSigTimeoutTime" BU_SG_REL_ SHVU_RR SG_ 2458165761 C_TeleRLSeatOpCmdIBOX 0;
BA_REL_ "GenSigTimeoutTime" BU_SG_REL_ ATS SG_ 2458165761 C_TeleRLSeatOpCmdIBOX 0;
BA_ "Version" SG_ 2458165761 C_TeleRLSeatOpCmdIBOX "18.09.04";
BA_ "GenSigSendType" SG_ 2458165761 C_HazardFromCCS 4;
BA_ "UserSigValidity" SG_ 2458165761 C_HazardFromCCS 0;
BA_ "NetworkRequest" SG_ 2458165761 C_HazardFromCCS 0;
BA_ "NetworkRequestHoldingTime" SG_ 2458165761 C_HazardFromCCS 2000;
BA_ "Version" SG_ 2458165761 C_HazardFromCCS "19.07.01";
BA_ "GenSigSendType" SG_ 2458165761 C_CtrlDrUnlockRlyIBOX 4;
BA_ "UserSigValidity" SG_ 2458165761 C_CtrlDrUnlockRlyIBOX 0;
BA_ "NetworkRequest" SG_ 2458165761 C_CtrlDrUnlockRlyIBOX 0;
BA_ "NetworkRequestHoldingTime" SG_ 2458165761 C_CtrlDrUnlockRlyIBOX 2000;
BA_ "Version" SG_ 2458165761 C_CtrlDrUnlockRlyIBOX "19.07.01";
BA_ "GenSigSendType" SG_ 2458165761 C_PanicFromCCS 4;
BA_ "UserSigValidity" SG_ 2458165761 C_PanicFromCCS 0;
BA_ "NetworkRequest" SG_ 2458165761 C_PanicFromCCS 0;
BA_ "NetworkRequestHoldingTime" SG_ 2458165761 C_PanicFromCCS 2000;
BA_ "Version" SG_ 2458165761 C_PanicFromCCS "19.07.01";
BA_ "GenSigSendType" SG_ 2458165761 C_CtrlDrUnlockRlyCCS 4;
BA_ "UserSigValidity" SG_ 2458165761 C_CtrlDrUnlockRlyCCS 0;
BA_ "NetworkRequest" SG_ 2458165761 C_CtrlDrUnlockRlyCCS 0;
BA_ "NetworkRequestHoldingTime" SG_ 2458165761 C_CtrlDrUnlockRlyCCS 2000;
BA_ "Version" SG_ 2458165761 C_CtrlDrUnlockRlyCCS "19.07.01";
BA_ "GenSigSendType" SG_ 2458165761 C_CtrlDrLockRlyCCS 4;
BA_ "UserSigValidity" SG_ 2458165761 C_CtrlDrLockRlyCCS 0;
BA_ "NetworkRequest" SG_ 2458165761 C_CtrlDrLockRlyCCS 0;
BA_ "NetworkRequestHoldingTime" SG_ 2458165761 C_CtrlDrLockRlyCCS 2000;
BA_ "Version" SG_ 2458165761 C_CtrlDrLockRlyCCS "19.07.01";
BA_ "GenSigSendType" SG_ 2458165761 C_CtrlDrLockRlyIBOX 4;
BA_ "UserSigValidity" SG_ 2458165761 C_CtrlDrLockRlyIBOX 0;
BA_ "NetworkRequest" SG_ 2458165761 C_CtrlDrLockRlyIBOX 0;
BA_ "NetworkRequestHoldingTime" SG_ 2458165761 C_CtrlDrLockRlyIBOX 2000;
BA_ "Version" SG_ 2458165761 C_CtrlDrLockRlyIBOX "19.07.01";
BA_ "GenSigSendType" SG_ 2458165761 C_TeleHeatingCmdIBOX 4;
BA_ "GenSigStartValue" SG_ 2458165761 C_TeleHeatingCmdIBOX 3;
BA_ "UserSigValidity" SG_ 2458165761 C_TeleHeatingCmdIBOX 0;
BA_ "NetworkRequest" SG_ 2458165761 C_TeleHeatingCmdIBOX 0;
BA_ "Version" SG_ 2458165761 C_TeleHeatingCmdIBOX "18.09.04";
BA_ "GenMsgSendType" BO_ 2479160833 0;
BA_ "GenMsgCycleTime" BO_ 2479160833 2000;
BA_ "VFrameFormat" BO_ 2479160833 1;
BA_ "GenSigSendType" SG_ 2479160833 HU_Type 4;
BA_ "GenSigStartValue" SG_ 2479160833 HU_Type 255;
BA_ "UserSigValidity" SG_ 2479160833 HU_Type 1;
BA_REL_ "GenSigTimeoutTime" BU_SG_REL_ AMP SG_ 2479160833 HU_Type 5000;
BA_ "NetworkRequest" SG_ 2479160833 HU_Type 0;
BA_ "NetworkRequestHoldingTime" SG_ 2479160833 HU_Type 7000;
BA_ "Version" SG_ 2479160833 HU_Type "21.08.01";
BA_ "GenSigSendType" SG_ 2479160833 HU_DistributeInfo 4;
BA_ "GenSigStartValue" SG_ 2479160833 HU_DistributeInfo 255;
BA_ "UserSigValidity" SG_ 2479160833 HU_DistributeInfo 1;
BA_REL_ "GenSigTimeoutTime" BU_SG_REL_ AMP SG_ 2479160833 HU_DistributeInfo 5000;
BA_ "NetworkRequest" SG_ 2479160833 HU_DistributeInfo 0;
BA_ "Version" SG_ 2479160833 HU_DistributeInfo "19.02.08";
BA_ "Description" SG_ 2479160833 HU_OptionInfo "Bit0 : Navi (0: Not Support / 1: Support)

Bit1 : USM (0: Not Support / 1: Support)

Bit2 : TMS (0: Not Support / 1: Support)

Bit3 : Multi Profile (0: Not Support(No Profile or Single Profile)  / 1: Support)

Bit4 : Camera Guideline (0: Displayed by Camera / 1: Displayed by H/U)

Bit5 : LVDS Interface (0:MIPI, 1:Non-MIPI)

Bit6 : Welcome/Goodbye Animation Support (0: Not Support / 1: Support)

Bit7 : Drive/Custom Mode Support (0: Not Support / 1 : Support)

Bit8 : Automatic brightness adjustment function Support (0: Not Support / 1 : Support) 

Bit9~Bit14 : Reserved

Bit15 : Invalid";
BA_ "GenSigSendType" SG_ 2479160833 HU_OptionInfo 4;
BA_ "GenSigStartValue" SG_ 2479160833 HU_OptionInfo 32768;
BA_ "UserSigValidity" SG_ 2479160833 HU_OptionInfo 0;
BA_REL_ "GenSigTimeoutTime" BU_SG_REL_ AMP SG_ 2479160833 HU_OptionInfo 5000;
BA_ "Version" SG_ 2479160833 HU_OptionInfo "21.08.01";
BA_ "Description" SG_ 2479160833 HU_CamViewDispStatus "Information for Camera View displayed status";
BA_ "GenSigSendType" SG_ 2479160833 HU_CamViewDispStatus 4;
BA_ "UserSigValidity" SG_ 2479160833 HU_CamViewDispStatus 1;
BA_ "Version" SG_ 2479160833 HU_CamViewDispStatus "19.07.05";
BA_ "Description" SG_ 2479160833 HU_NaviHandshakingSupport "This is a signal to send whether handshaking logic is applied related to Navigation's 'Map based ADAS' specification";
BA_ "GenSigSendType" SG_ 2479160833 HU_NaviHandshakingSupport 4;
BA_ "UserSigValidity" SG_ 2479160833 HU_NaviHandshakingSupport 1;
BA_ "Version" SG_ 2479160833 HU_NaviHandshakingSupport "20.05.02";
BA_ "GenSigSendType" SG_ 2479160833 HU_AMP_EQVariant 4;
BA_ "GenSigStartValue" SG_ 2479160833 HU_AMP_EQVariant 31;
BA_ "UserSigValidity" SG_ 2479160833 HU_AMP_EQVariant 1;
BA_REL_ "GenSigTimeoutTime" BU_SG_REL_ AMP SG_ 2479160833 HU_AMP_EQVariant 5000;
BA_ "Version" SG_ 2479160833 HU_AMP_EQVariant "18.08.03";
BA_ "Description" SG_ 2479160833 HU_AdasSupport "0x0 : Not Support

0x1 : ADAS Support (General Map) - Send map information based on General Map

0x2 : ADAS Support (Map based ADAS v1) - Send map information based on Map based ADAS v1 or v1.5

0x3 : ADAS Support (Map based ADAS v2) - Send map information based on Map based ADAS v2.0

0x4 : ADAS Support (Map based ADAS v2.0 & Handshaking) - Send map information based on Map based ADAS v2.0 & Support Handshaking 

0x5 : ADAS Support (Map based ADAS v2.3)  

 - 2nd CAN DB :  Send map information based on Map based ADAS v2.3 

 - 3rd CAN DB : Send map information based on Map based ADAS v2.3 & Support Handshaking";
BA_ "GenSigSendType" SG_ 2479160833 HU_AdasSupport 4;
BA_ "GenSigStartValue" SG_ 2479160833 HU_AdasSupport 7;
BA_ "UserSigValidity" SG_ 2479160833 HU_AdasSupport 1;
BA_ "NetworkRequest" SG_ 2479160833 HU_AdasSupport 0;
BA_ "NetworkRequestHoldingTime" SG_ 2479160833 HU_AdasSupport 5000;
BA_ "Version" SG_ 2479160833 HU_AdasSupport "20.05.02";
BA_ "Description" SG_ 2479160833 HU_Navi_RspADASMapMsg "This signal indicates an ADAS map message response from H_U to ECU 

which is stored the  required Map based ADAS messages for each ECU



Each bit indicates the request messages as follows.

(1: Sending message / 0 : Doens't sending message)

- Bit 0 : H_U_NAVI_V2_STUB_E

- Bit 1 : HU_NAVI_V2_PROSHORT_E_00 (Curvature info)

- Bit 2 : HU_NAVI_V2_PROSHORT_E_00 (Info execpt curvature)

- Bit 3 : HU_NAVI_V2_PROSHORT_E_01

- Bit 4 : HU_NAVI_V2_PROSHORT_E_02

- Bit 5 : HU_NAVI_V2_PROLONG_E

- Bit 6 : HU_NAVI_V2_SEG_SUB_E, 

             HU_NAVI_V2_STUB_SUB_E, 

             HU_NAVI_V2_PROSHORT_SUB_E, 

             HU_NAVI_V2_PROLONG_SUB_E

- Bit 7 : HU_NAVI_V2_PATH_PE_00, 

             HU_NAVI_V2_PATH_PE_01

- Bit 8~15 : Reserved";
BA_ "GenSigSendType" SG_ 2479160833 HU_Navi_RspADASMapMsg 4;
BA_ "UserSigValidity" SG_ 2479160833 HU_Navi_RspADASMapMsg 3;
BA_ "Version" SG_ 2479160833 HU_Navi_RspADASMapMsg "19.09.06";
BA_ "GenMsgSendType" BO_ 2281833729 0;
BA_ "GenMsgCycleTimeFast" BO_ 2281833729 0;
BA_ "GenMsgNrOfRepetition" BO_ 2281833729 0;
BA_ "VFrameFormat" BO_ 2281833729 1;
BA_ "Description" SG_ 2281833729 ICSC_Crc2Val "The data area for CRC calculation is based on the data length (DLC) of the message DB.

The CRC shall be calculated over the entire data block (excluding the CRC bytes) including the user data, alive counter and Data ID

 

- CRC Polynomial (0x1021) , Initial Value : 0xFFFF, XOR value : 0x0000, Data ID : Message ID + 0xF800 

- The initial value is for CRC calculation and the message should be sent with the calculated result value. 

- The mathematical expression to 16 bit CRC polynomial is given here. G(x) = x16 + x12 + x5 + 1";
BA_ "GenSigStartValue" SG_ 2281833729 ICSC_Crc2Val 65535;
BA_ "UserSigValidity" SG_ 2281833729 ICSC_Crc2Val 3;
BA_ "RoutingFactor" SG_ 2281833729 ICSC_Crc2Val 2;
BA_ "Version" SG_ 2281833729 ICSC_Crc2Val "18.11.08";
BA_ "Description" SG_ 2281833729 ICSC_AlvCnt2Val "For the first transmission request for a data element the counter shall be initialized with 0 and shall be incremented by 1 for every subsequent send request. 

When the counter reaches the maximum value(0xFF), then it shall restart with 0 for the next send request";
BA_ "UserSigValidity" SG_ 2281833729 ICSC_AlvCnt2Val 3;
BA_ "RoutingFactor" SG_ 2281833729 ICSC_AlvCnt2Val 2;
BA_ "Version" SG_ 2281833729 ICSC_AlvCnt2Val "18.11.08";
BA_ "Description" SG_ 2281833729 DMIC_DrvModSta "This signal is feedback state of driving mode for Cluster/AVN

This message is for DMIC(Driving Mode Integrated Control)";
BA_ "UserSigValidity" SG_ 2281833729 DMIC_DrvModSta 3;
BA_REL_ "GenSigTimeoutTime" BU_SG_REL_ DSAU SG_ 2281833729 DMIC_DrvModSta 1500;
BA_REL_ "GenSigTimeoutTime" BU_SG_REL_ ASAU SG_ 2281833729 DMIC_DrvModSta 1500;
BA_ "RoutingFactor" SG_ 2281833729 DMIC_DrvModSta 2;
BA_ "Version" SG_ 2281833729 DMIC_DrvModSta "20.07.10";
BA_ "Description" SG_ 2281833729 DMIC_SmtShftModSta "This signal is a smart shift mode flag.";
BA_ "UserSigValidity" SG_ 2281833729 DMIC_SmtShftModSta 3;
BA_ "RoutingFactor" SG_ 2281833729 DMIC_SmtShftModSta 2;
BA_ "Version" SG_ 2281833729 DMIC_SmtShftModSta "17.12.00";
BA_ "Description" SG_ 2281833729 DMIC_EngModSta "This Signal is the request on mode transition for Controlling the Driving Mode.";
BA_ "UserSigValidity" SG_ 2281833729 DMIC_EngModSta 3;
BA_REL_ "GenSigTimeoutTime" BU_SG_REL_ AMP SG_ 2281833729 DMIC_EngModSta 1500;
BA_ "RoutingFactor" SG_ 2281833729 DMIC_EngModSta 2;
BA_ "Version" SG_ 2281833729 DMIC_EngModSta "19.09.00";
BA_ "Description" SG_ 2281833729 DMIC_IndEngModSta "This signal is for feedback about individual mode setting on AVN.";
BA_ "UserSigValidity" SG_ 2281833729 DMIC_IndEngModSta 3;
BA_ "RoutingFactor" SG_ 2281833729 DMIC_IndEngModSta 2;
BA_ "Version" SG_ 2281833729 DMIC_IndEngModSta "19.09.00";
BA_ "Description" SG_ 2281833729 DMIC_TmModSta "This Signal is the request on mode transition for Controlling the Driving Mode.";
BA_ "UserSigValidity" SG_ 2281833729 DMIC_TmModSta 3;
BA_ "RoutingFactor" SG_ 2281833729 DMIC_TmModSta 2;
BA_ "Version" SG_ 2281833729 DMIC_TmModSta "19.09.00";
BA_ "Description" SG_ 2281833729 DMIC_EscModSta "This Signal is the request on mode transition for Controlling the Driving Mode.";
BA_ "UserSigValidity" SG_ 2281833729 DMIC_EscModSta 3;
BA_ "RoutingFactor" SG_ 2281833729 DMIC_EscModSta 2;
BA_ "Version" SG_ 2281833729 DMIC_EscModSta "17.12.00";
BA_ "Description" SG_ 2281833729 DMIC_MdpsModSta "This Signal is the request on mode transition for Controlling the Driving Mode.";
BA_ "UserSigValidity" SG_ 2281833729 DMIC_MdpsModSta 3;
BA_ "RoutingFactor" SG_ 2281833729 DMIC_MdpsModSta 2;
BA_ "Version" SG_ 2281833729 DMIC_MdpsModSta "19.09.00";
BA_ "Description" SG_ 2281833729 DMIC_IndMdpsModSta "This signal is for feedback about individual mode setting on AVN.";
BA_ "UserSigValidity" SG_ 2281833729 DMIC_IndMdpsModSta 3;
BA_ "RoutingFactor" SG_ 2281833729 DMIC_IndMdpsModSta 2;
BA_ "Version" SG_ 2281833729 DMIC_IndMdpsModSta "19.09.00";
BA_ "GenMsgSendType" BO_ 2281833730 0;
BA_ "GenMsgCycleTimeFast" BO_ 2281833730 0;
BA_ "GenMsgNrOfRepetition" BO_ 2281833730 0;
BA_ "VFrameFormat" BO_ 2281833730 1;
BA_ "Description" SG_ 2281833730 DMIC_EcsModSta "This Signal is the request on mode transition for Controlling the Driving Mode.";
BA_ "UserSigValidity" SG_ 2281833730 DMIC_EcsModSta 3;
BA_ "RoutingFactor" SG_ 2281833730 DMIC_EcsModSta 2;
BA_ "Version" SG_ 2281833730 DMIC_EcsModSta "19.09.00";
BA_ "Description" SG_ 2281833730 DMIC_IndAwdModSta "This signal is for feedback about individual mode setting on AVN.";
BA_ "UserSigValidity" SG_ 2281833730 DMIC_IndAwdModSta 3;
BA_ "RoutingFactor" SG_ 2281833730 DMIC_IndAwdModSta 2;
BA_ "Version" SG_ 2281833730 DMIC_IndAwdModSta "17.12.00";
BA_ "Description" SG_ 2281833730 DMIC_IndEcsModSta "This signal is for feedback about individual mode setting on AVN.";
BA_ "UserSigValidity" SG_ 2281833730 DMIC_IndEcsModSta 3;
BA_ "RoutingFactor" SG_ 2281833730 DMIC_IndEcsModSta 2;
BA_ "Version" SG_ 2281833730 DMIC_IndEcsModSta "19.09.00";
BA_ "Description" SG_ 2281833730 DMIC_IndRwsModSta "This signal is for feedback about individual mode setting on AVN.";
BA_ "UserSigValidity" SG_ 2281833730 DMIC_IndRwsModSta 3;
BA_ "RoutingFactor" SG_ 2281833730 DMIC_IndRwsModSta 2;
BA_ "Version" SG_ 2281833730 DMIC_IndRwsModSta "17.11.00";
BA_ "Description" SG_ 2281833730 DMIC_IndBrkModSta "This signal is for feedback about individual mode setting on AVN.";
BA_ "UserSigValidity" SG_ 2281833730 DMIC_IndBrkModSta 3;
BA_ "RoutingFactor" SG_ 2281833730 DMIC_IndBrkModSta 2;
BA_ "Version" SG_ 2281833730 DMIC_IndBrkModSta "18.08.05";
BA_ "Description" SG_ 2281833730 DMIC_AwdModSta "This Signal is the request on mode transition for Controlling the Driving Mode.";
BA_ "UserSigValidity" SG_ 2281833730 DMIC_AwdModSta 3;
BA_ "RoutingFactor" SG_ 2281833730 DMIC_AwdModSta 2;
BA_ "Version" SG_ 2281833730 DMIC_AwdModSta "17.12.00";
BA_ "GenMsgSendType" BO_ 2281833731 0;
BA_ "GenMsgCycleTimeFast" BO_ 2281833731 0;
BA_ "GenMsgNrOfRepetition" BO_ 2281833731 0;
BA_ "VFrameFormat" BO_ 2281833731 1;
BA_ "Description" SG_ 2281833731 DMIC_DrvModTyp "This signal indicates drive mode type.";
BA_ "UserSigValidity" SG_ 2281833731 DMIC_DrvModTyp 3;
BA_ "RoutingFactor" SG_ 2281833731 DMIC_DrvModTyp 2;
BA_ "Version" SG_ 2281833731 DMIC_DrvModTyp "17.12.00";
BA_ "Description" SG_ 2281833731 DMIC_EngFltSta "This signal indicates fault status of individual systems.";
BA_ "UserSigValidity" SG_ 2281833731 DMIC_EngFltSta 3;
BA_ "RoutingFactor" SG_ 2281833731 DMIC_EngFltSta 2;
BA_ "Version" SG_ 2281833731 DMIC_EngFltSta "17.12.00";
BA_ "Description" SG_ 2281833731 DMIC_MdpsFltSta "This signal indicates fault status of individual systems.";
BA_ "UserSigValidity" SG_ 2281833731 DMIC_MdpsFltSta 3;
BA_ "RoutingFactor" SG_ 2281833731 DMIC_MdpsFltSta 2;
BA_ "Version" SG_ 2281833731 DMIC_MdpsFltSta "17.12.00";
BA_ "Description" SG_ 2281833731 DMIC_EcsFltSta "This signal indicates fault status of individual systems.";
BA_ "UserSigValidity" SG_ 2281833731 DMIC_EcsFltSta 3;
BA_ "RoutingFactor" SG_ 2281833731 DMIC_EcsFltSta 2;
BA_ "Version" SG_ 2281833731 DMIC_EcsFltSta "17.12.00";
BA_ "Description" SG_ 2281833731 DMIC_AwdFltSta "This signal indicates fault status of individual systems.";
BA_ "UserSigValidity" SG_ 2281833731 DMIC_AwdFltSta 3;
BA_ "RoutingFactor" SG_ 2281833731 DMIC_AwdFltSta 2;
BA_ "Version" SG_ 2281833731 DMIC_AwdFltSta "17.12.00";
BA_ "Description" SG_ 2281833731 DMIC_RwsFltSta "This signal indicates fault status of individual systems.";
BA_ "UserSigValidity" SG_ 2281833731 DMIC_RwsFltSta 3;
BA_ "RoutingFactor" SG_ 2281833731 DMIC_RwsFltSta 2;
BA_ "Version" SG_ 2281833731 DMIC_RwsFltSta "17.11.00";
BA_ "Description" SG_ 2281833731 DMIC_BrkFltSta "This signal indicates fault status of individual systems.";
BA_ "UserSigValidity" SG_ 2281833731 DMIC_BrkFltSta 3;
BA_ "RoutingFactor" SG_ 2281833731 DMIC_BrkFltSta 2;
BA_ "Version" SG_ 2281833731 DMIC_BrkFltSta "18.08.05";
BA_ "Description" SG_ 2281833731 DMIC_DrvModFltSta "This signal is for Driving mode fault status. From this signal, AVN can deactivate any driving in mode selection menu.";
BA_ "UserSigValidity" SG_ 2281833731 DMIC_DrvModFltSta 3;
BA_ "RoutingFactor" SG_ 2281833731 DMIC_DrvModFltSta 2;
BA_ "Version" SG_ 2281833731 DMIC_DrvModFltSta "17.12.00";
BA_ "GenMsgSendType" BO_ 1041 0;
BA_ "Description" SG_ 1041 ICU_Crc2Val "The data area for CRC calculation is based on the data length (DLC) of the message DB.

The CRC shall be calculated over the entire data block (excluding the CRC bytes) including the user data, alive counter and Data ID 

 

- CRC Polynomial (0x1D) , Initial Value : 0x00, XOR value : 0xFF, Data ID Mode : Both, Data ID : Message ID + 0xF800 

- The initial value is for CRC calculation and the message should be sent with the calculated result value. 

The mathematical expression to 8 bit CRC polynomial is given here. G(x) = x8 + x4 + x3 + x2 + 1";
BA_ "GenSigSendType" SG_ 1041 ICU_Crc2Val 4;
BA_ "GenSigStartValue" SG_ 1041 ICU_Crc2Val 255;
BA_ "UserSigValidity" SG_ 1041 ICU_Crc2Val 0;
BA_REL_ "GenSigTimeoutTime" BU_SG_REL_ vHS_M SG_ 1041 ICU_Crc2Val 1500;
BA_ "Version" SG_ 1041 ICU_Crc2Val "18.11.08";
BA_ "Description" SG_ 1041 ICU_AlvCnt2Val "For the first transmission request for a data element the counter shall be initialized with 0 and shall be incremented by 1

for every subsequent send request. When the counter reaches the maximum value(0xE), then it shall restart with 0 for the next send request";
BA_ "GenSigSendType" SG_ 1041 ICU_AlvCnt2Val 4;
BA_ "UserSigValidity" SG_ 1041 ICU_AlvCnt2Val 0;
BA_ "Version" SG_ 1041 ICU_AlvCnt2Val "18.11.08";
BA_ "Description" SG_ 1041 Autocut_DlvryModSta "-(Old)C_SJB_DeliveryMode

-Initial value: 1";
BA_ "GenSigSendType" SG_ 1041 Autocut_DlvryModSta 4;
BA_ "GenSigStartValue" SG_ 1041 Autocut_DlvryModSta 1;
BA_ "UserSigValidity" SG_ 1041 Autocut_DlvryModSta 0;
BA_ "NetworkRequest" SG_ 1041 Autocut_DlvryModSta 0;
BA_ "NetworkRequestHoldingTime" SG_ 1041 Autocut_DlvryModSta 5000;
BA_ "Version" SG_ 1041 Autocut_DlvryModSta "17.12.00";
BA_ "Description" SG_ 1041 Warn_AsstStBltSwSta "-Default value: 0x1 (Belt)



-Initial value: 0x1 (Belt)



-Timeout value: 0x1 (Belt)";
BA_ "GenSigSendType" SG_ 1041 Warn_AsstStBltSwSta 4;
BA_ "GenSigStartValue" SG_ 1041 Warn_AsstStBltSwSta 1;
BA_ "UserSigValidity" SG_ 1041 Warn_AsstStBltSwSta 0;
BA_REL_ "GenSigTimeoutTime" BU_SG_REL_ APSM SG_ 1041 Warn_AsstStBltSwSta 1500;
BA_REL_ "GenSigTimeoutTime" BU_SG_REL_ RLPSM SG_ 1041 Warn_AsstStBltSwSta 1500;
BA_REL_ "GenSigTimeoutTime" BU_SG_REL_ RRPSM SG_ 1041 Warn_AsstStBltSwSta 1500;
BA_REL_ "GenSigTimeoutTime" BU_SG_REL_ ASAU SG_ 1041 Warn_AsstStBltSwSta 1500;
BA_ "NetworkRequest" SG_ 1041 Warn_AsstStBltSwSta 0;
BA_ "NetworkRequestHoldingTime" SG_ 1041 Warn_AsstStBltSwSta 5000;
BA_ "Version" SG_ 1041 Warn_AsstStBltSwSta "17.12.00";
BA_ "GenSigSendType" SG_ 1041 Warn_BrkFldSwSta 4;
BA_ "UserSigValidity" SG_ 1041 Warn_BrkFldSwSta 0;
BA_ "NetworkRequest" SG_ 1041 Warn_BrkFldSwSta 0;
BA_ "NetworkRequestHoldingTime" SG_ 1041 Warn_BrkFldSwSta 5000;
BA_ "Version" SG_ 1041 Warn_BrkFldSwSta "17.12.00";
BA_ "GenSigSendType" SG_ 1041 Warn_DrvStBltSwSta 4;
BA_ "UserSigValidity" SG_ 1041 Warn_DrvStBltSwSta 0;
BA_REL_ "GenSigTimeoutTime" BU_SG_REL_ ATS SG_ 1041 Warn_DrvStBltSwSta 1500;
BA_REL_ "GenSigTimeoutTime" BU_SG_REL_ DSAU SG_ 1041 Warn_DrvStBltSwSta 1500;
BA_REL_ "GenSigTimeoutTime" BU_SG_REL_ ASAU SG_ 1041 Warn_DrvStBltSwSta 1500;
BA_ "NetworkRequest" SG_ 1041 Warn_DrvStBltSwSta 0;
BA_ "NetworkRequestHoldingTime" SG_ 1041 Warn_DrvStBltSwSta 5000;
BA_ "Version" SG_ 1041 Warn_DrvStBltSwSta "17.12.00";
BA_ "GenSigSendType" SG_ 1041 Warn_HoodSwSta 4;
BA_ "UserSigValidity" SG_ 1041 Warn_HoodSwSta 0;
BA_ "NetworkRequest" SG_ 1041 Warn_HoodSwSta 0;
BA_ "NetworkRequestHoldingTime" SG_ 1041 Warn_HoodSwSta 5000;
BA_ "Version" SG_ 1041 Warn_HoodSwSta "17.12.00";
BA_ "Description" SG_ 1041 Warn_PassStOccSta "Passenger Seated State







-Default value: 0x0 (미탑승)



-Initial value: 0x0 (미탑승)



-Timeout value: 0x0 (미탑승)";
BA_ "GenSigSendType" SG_ 1041 Warn_PassStOccSta 4;
BA_ "UserSigValidity" SG_ 1041 Warn_PassStOccSta 0;
BA_REL_ "GenSigTimeoutTime" BU_SG_REL_ APSM SG_ 1041 Warn_PassStOccSta 1500;
BA_ "NetworkRequest" SG_ 1041 Warn_PassStOccSta 0;
BA_ "NetworkRequestHoldingTime" SG_ 1041 Warn_PassStOccSta 5000;
BA_ "Version" SG_ 1041 Warn_PassStOccSta "17.12.00";
BA_ "GenSigSendType" SG_ 1041 Warn_RrCtrStBltSwSta 4;
BA_ "UserSigValidity" SG_ 1041 Warn_RrCtrStBltSwSta 0;
BA_ "NetworkRequest" SG_ 1041 Warn_RrCtrStBltSwSta 0;
BA_ "NetworkRequestHoldingTime" SG_ 1041 Warn_RrCtrStBltSwSta 5000;
BA_ "Version" SG_ 1041 Warn_RrCtrStBltSwSta "17.12.00";
BA_ "GenSigSendType" SG_ 1041 Warn_RrLftStBltSwSta 4;
BA_ "UserSigValidity" SG_ 1041 Warn_RrLftStBltSwSta 0;
BA_REL_ "GenSigTimeoutTime" BU_SG_REL_ RLPSM SG_ 1041 Warn_RrLftStBltSwSta 1500;
BA_REL_ "GenSigTimeoutTime" BU_SG_REL_ RRPSM SG_ 1041 Warn_RrLftStBltSwSta 1500;
BA_ "NetworkRequest" SG_ 1041 Warn_RrLftStBltSwSta 0;
BA_ "NetworkRequestHoldingTime" SG_ 1041 Warn_RrLftStBltSwSta 5000;
BA_ "Version" SG_ 1041 Warn_RrLftStBltSwSta "17.12.00";
BA_ "GenSigSendType" SG_ 1041 Warn_RrRtStBltSwSta 4;
BA_ "UserSigValidity" SG_ 1041 Warn_RrRtStBltSwSta 0;
BA_REL_ "GenSigTimeoutTime" BU_SG_REL_ RLPSM SG_ 1041 Warn_RrRtStBltSwSta 1500;
BA_REL_ "GenSigTimeoutTime" BU_SG_REL_ RRPSM SG_ 1041 Warn_RrRtStBltSwSta 1500;
BA_ "NetworkRequest" SG_ 1041 Warn_RrRtStBltSwSta 0;
BA_ "NetworkRequestHoldingTime" SG_ 1041 Warn_RrRtStBltSwSta 5000;
BA_ "Version" SG_ 1041 Warn_RrRtStBltSwSta "17.12.00";
BA_ "Description" SG_ 1041 Warn_HoodSwMemorySta "Hood swtich open->close information(memory)



This signal is for oil level warning lamp reset In case hood open->close when IG-OFF, 0x01 sent for 5 sec at next IG-ON";
BA_ "GenSigSendType" SG_ 1041 Warn_HoodSwMemorySta 4;
BA_ "UserSigValidity" SG_ 1041 Warn_HoodSwMemorySta 3;
BA_ "NetworkRequest" SG_ 1041 Warn_HoodSwMemorySta 0;
BA_ "NetworkRequestHoldingTime" SG_ 1041 Warn_HoodSwMemorySta 5000;
BA_ "Version" SG_ 1041 Warn_HoodSwMemorySta "17.12.00";
BA_ "Description" SG_ 1041 Warn_WshrFldSwSta "Washer Fluid Switch Signal

This signal indicates Washer Fluid Switch Signal

0x0:Off/0x1:On";
BA_ "GenSigSendType" SG_ 1041 Warn_WshrFldSwSta 4;
BA_ "UserSigValidity" SG_ 1041 Warn_WshrFldSwSta 3;
BA_ "NetworkRequest" SG_ 1041 Warn_WshrFldSwSta 0;
BA_ "NetworkRequestHoldingTime" SG_ 1041 Warn_WshrFldSwSta 5000;
BA_ "Version" SG_ 1041 Warn_WshrFldSwSta "17.12.00";
BA_ "GenMsgSendType" BO_ 1042 0;
BA_ "Description" SG_ 1042 ICU_Crc3Val "The data area for CRC calculation is based on the data length (DLC) of the message DB.

The CRC shall be calculated over the entire data block (excluding the CRC bytes) including the user data, alive counter and Data ID 

 

- CRC Polynomial (0x1D) , Initial Value : 0x00, XOR value : 0xFF, Data ID Mode : Both, Data ID : Message ID + 0xF800 

- The initial value is for CRC calculation and the message should be sent with the calculated result value. 

The mathematical expression to 8 bit CRC polynomial is given here. G(x) = x8 + x4 + x3 + x2 + 1";
BA_ "GenSigSendType" SG_ 1042 ICU_Crc3Val 4;
BA_ "GenSigStartValue" SG_ 1042 ICU_Crc3Val 255;
BA_ "UserSigValidity" SG_ 1042 ICU_Crc3Val 0;
BA_REL_ "GenSigTimeoutTime" BU_SG_REL_ vHS_M SG_ 1042 ICU_Crc3Val 1500;
BA_ "Version" SG_ 1042 ICU_Crc3Val "18.11.08";
BA_ "Description" SG_ 1042 ICU_AlvCnt3Val "For the first transmission request for a data element the counter shall be initialized with 0 and shall be incremented by 1

for every subsequent send request. When the counter reaches the maximum value(0xE), then it shall restart with 0 for the next send request";
BA_ "GenSigSendType" SG_ 1042 ICU_AlvCnt3Val 4;
BA_ "UserSigValidity" SG_ 1042 ICU_AlvCnt3Val 0;
BA_ "Version" SG_ 1042 ICU_AlvCnt3Val "18.11.08";
BA_ "Description" SG_ 1042 Warn_DrvStOccSta "Driver Presence Detection MAT Switch Status";
BA_ "GenSigSendType" SG_ 1042 Warn_DrvStOccSta 4;
BA_ "UserSigValidity" SG_ 1042 Warn_DrvStOccSta 0;
BA_ "NetworkRequest" SG_ 1042 Warn_DrvStOccSta 0;
BA_ "NetworkRequestHoldingTime" SG_ 1042 Warn_DrvStOccSta 5000;
BA_ "Version" SG_ 1042 Warn_DrvStOccSta "20.04.02";
BA_ "Description" SG_ 1042 ExtLamp_BckUpLmpSta "This signal is used for control the Back-up Lamp function.";
BA_ "GenSigSendType" SG_ 1042 ExtLamp_BckUpLmpSta 4;
BA_ "UserSigValidity" SG_ 1042 ExtLamp_BckUpLmpSta 0;
BA_ "NetworkRequest" SG_ 1042 ExtLamp_BckUpLmpSta 0;
BA_ "NetworkRequestHoldingTime" SG_ 1042 ExtLamp_BckUpLmpSta 5000;
BA_ "Version" SG_ 1042 ExtLamp_BckUpLmpSta "18.10.06";
BA_ "Description" SG_ 1042 ExtLamp_StpLmpSta "This signal is used for control the Stop lamp function.";
BA_ "GenSigSendType" SG_ 1042 ExtLamp_StpLmpSta 4;
BA_ "UserSigValidity" SG_ 1042 ExtLamp_StpLmpSta 0;
BA_ "NetworkRequest" SG_ 1042 ExtLamp_StpLmpSta 0;
BA_ "NetworkRequestHoldingTime" SG_ 1042 ExtLamp_StpLmpSta 5000;
BA_ "Version" SG_ 1042 ExtLamp_StpLmpSta "18.10.06";
BA_ "Description" SG_ 1042 OTAModeACCOffReq "ACC off request during OTA mode for battery saver";
BA_ "GenSigSendType" SG_ 1042 OTAModeACCOffReq 4;
BA_ "TimeoutValue" SG_ 1042 OTAModeACCOffReq "0x0";
BA_ "UserSigValidity" SG_ 1042 OTAModeACCOffReq 0;
BA_ "NetworkRequest" SG_ 1042 OTAModeACCOffReq 0;
BA_ "Version" SG_ 1042 OTAModeACCOffReq "20.09.00";
BA_ "Description" SG_ 1042 C_ICUIGNOffReq "IGN off request(Not engine running state only) for battery saver";
BA_ "GenSigSendType" SG_ 1042 C_ICUIGNOffReq 4;
BA_ "TimeoutValue" SG_ 1042 C_ICUIGNOffReq "0x0";
BA_ "UserSigValidity" SG_ 1042 C_ICUIGNOffReq 0;
BA_ "NetworkRequest" SG_ 1042 C_ICUIGNOffReq 0;
BA_ "Version" SG_ 1042 C_ICUIGNOffReq "19.12.00";
BA_ "GenMsgSendType" BO_ 1043 0;
BA_ "Description" SG_ 1043 ICU_Crc4Val "The data area for CRC calculation is based on the data length (DLC) of the message DB.

The CRC shall be calculated over the entire data block (excluding the CRC bytes) including the user data, alive counter and Data ID 

 

- CRC Polynomial (0x1D) , Initial Value : 0x00, XOR value : 0xFF, Data ID Mode : Both, Data ID : Message ID + 0xF800 

- The initial value is for CRC calculation and the message should be sent with the calculated result value. 

The mathematical expression to 8 bit CRC polynomial is given here. G(x) = x8 + x4 + x3 + x2 + 1";
BA_ "GenSigSendType" SG_ 1043 ICU_Crc4Val 4;
BA_ "GenSigStartValue" SG_ 1043 ICU_Crc4Val 255;
BA_ "UserSigValidity" SG_ 1043 ICU_Crc4Val 0;
BA_REL_ "GenSigTimeoutTime" BU_SG_REL_ vHS_M SG_ 1043 ICU_Crc4Val 1500;
BA_ "Version" SG_ 1043 ICU_Crc4Val "18.11.08";
BA_ "Description" SG_ 1043 Lamp_TrnSigLmpRtActiveSt "Turn Signal Lamp Blink Info";
BA_ "GenSigSendType" SG_ 1043 Lamp_TrnSigLmpRtActiveSt 4;
BA_ "UserSigValidity" SG_ 1043 Lamp_TrnSigLmpRtActiveSt 0;
BA_ "NetworkRequest" SG_ 1043 Lamp_TrnSigLmpRtActiveSt 0;
BA_ "NetworkRequestHoldingTime" SG_ 1043 Lamp_TrnSigLmpRtActiveSt 5000;
BA_ "Version" SG_ 1043 Lamp_TrnSigLmpRtActiveSt "19.11.00";
BA_ "Description" SG_ 1043 ICU_AlvCnt4Val "For the first transmission request for a data element the counter shall be initialized with 0 and shall be incremented by 1

for every subsequent send request. When the counter reaches the maximum value(0xE), then it shall restart with 0 for the next send request";
BA_ "GenSigSendType" SG_ 1043 ICU_AlvCnt4Val 4;
BA_ "UserSigValidity" SG_ 1043 ICU_AlvCnt4Val 0;
BA_ "Version" SG_ 1043 ICU_AlvCnt4Val "18.11.08";
BA_ "GenSigSendType" SG_ 1043 ExtLamp_TrnSigLmpLftBlnkngSta 4;
BA_ "UserSigValidity" SG_ 1043 ExtLamp_TrnSigLmpLftBlnkngSta 0;
BA_ "NetworkRequest" SG_ 1043 ExtLamp_TrnSigLmpLftBlnkngSta 0;
BA_ "NetworkRequestHoldingTime" SG_ 1043 ExtLamp_TrnSigLmpLftBlnkngSta 5000;
BA_ "Version" SG_ 1043 ExtLamp_TrnSigLmpLftBlnkngSta "17.12.00";
BA_ "GenSigSendType" SG_ 1043 ExtLamp_TrnSigLmpRtBlnkngSta 4;
BA_ "UserSigValidity" SG_ 1043 ExtLamp_TrnSigLmpRtBlnkngSta 0;
BA_ "NetworkRequest" SG_ 1043 ExtLamp_TrnSigLmpRtBlnkngSta 0;
BA_ "NetworkRequestHoldingTime" SG_ 1043 ExtLamp_TrnSigLmpRtBlnkngSta 5000;
BA_ "Version" SG_ 1043 ExtLamp_TrnSigLmpRtBlnkngSta "17.12.00";
BA_ "Description" SG_ 1043 ExtLamp_ExtrnlTailLmpSta "-(Old)C_EXTTail_Act";
BA_ "GenSigSendType" SG_ 1043 ExtLamp_ExtrnlTailLmpSta 4;
BA_ "UserSigValidity" SG_ 1043 ExtLamp_ExtrnlTailLmpSta 0;
BA_ "NetworkRequest" SG_ 1043 ExtLamp_ExtrnlTailLmpSta 0;
BA_ "NetworkRequestHoldingTime" SG_ 1043 ExtLamp_ExtrnlTailLmpSta 5000;
BA_ "Version" SG_ 1043 ExtLamp_ExtrnlTailLmpSta "17.12.00";
BA_ "GenSigSendType" SG_ 1043 ExtLamp_HzrdSwSta 4;
BA_ "UserSigValidity" SG_ 1043 ExtLamp_HzrdSwSta 0;
BA_REL_ "GenSigTimeoutTime" BU_SG_REL_ ICC SG_ 1043 ExtLamp_HzrdSwSta 1500;
BA_ "NetworkRequest" SG_ 1043 ExtLamp_HzrdSwSta 0;
BA_ "NetworkRequestHoldingTime" SG_ 1043 ExtLamp_HzrdSwSta 5000;
BA_ "Version" SG_ 1043 ExtLamp_HzrdSwSta "17.12.00";
BA_ "Description" SG_ 1043 ExtLamp_RrFgLmpSta "-(Old)C_RearFog_Act";
BA_ "GenSigSendType" SG_ 1043 ExtLamp_RrFgLmpSta 4;
BA_ "UserSigValidity" SG_ 1043 ExtLamp_RrFgLmpSta 0;
BA_ "NetworkRequest" SG_ 1043 ExtLamp_RrFgLmpSta 0;
BA_ "NetworkRequestHoldingTime" SG_ 1043 ExtLamp_RrFgLmpSta 5000;
BA_ "Version" SG_ 1043 ExtLamp_RrFgLmpSta "17.12.00";
BA_ "Description" SG_ 1043 IntLamp_InlTailLmpSta "-(Old)C_INTTail_Act";
BA_ "GenSigSendType" SG_ 1043 IntLamp_InlTailLmpSta 4;
BA_ "UserSigValidity" SG_ 1043 IntLamp_InlTailLmpSta 0;
BA_ "NetworkRequest" SG_ 1043 IntLamp_InlTailLmpSta 0;
BA_ "NetworkRequestHoldingTime" SG_ 1043 IntLamp_InlTailLmpSta 5000;
BA_ "Version" SG_ 1043 IntLamp_InlTailLmpSta "17.12.00";
BA_ "GenSigSendType" SG_ 1043 Lamp_TrnSigLmpLftOnReq 4;
BA_ "UserSigValidity" SG_ 1043 Lamp_TrnSigLmpLftOnReq 0;
BA_ "NetworkRequest" SG_ 1043 Lamp_TrnSigLmpLftOnReq 0;
BA_ "NetworkRequestHoldingTime" SG_ 1043 Lamp_TrnSigLmpLftOnReq 5000;
BA_ "Version" SG_ 1043 Lamp_TrnSigLmpLftOnReq "17.12.05";
BA_ "GenSigSendType" SG_ 1043 Lamp_TrnSigLmpRtOnReq 4;
BA_ "UserSigValidity" SG_ 1043 Lamp_TrnSigLmpRtOnReq 0;
BA_ "NetworkRequest" SG_ 1043 Lamp_TrnSigLmpRtOnReq 0;
BA_ "NetworkRequestHoldingTime" SG_ 1043 Lamp_TrnSigLmpRtOnReq 5000;
BA_ "Version" SG_ 1043 Lamp_TrnSigLmpRtOnReq "17.12.05";
BA_ "Description" SG_ 1043 Lamp_TrnSigLmpLftActiveSt "Turn Signal Lmap Blink Info";
BA_ "GenSigSendType" SG_ 1043 Lamp_TrnSigLmpLftActiveSt 4;
BA_ "UserSigValidity" SG_ 1043 Lamp_TrnSigLmpLftActiveSt 0;
BA_ "NetworkRequest" SG_ 1043 Lamp_TrnSigLmpLftActiveSt 0;
BA_ "NetworkRequestHoldingTime" SG_ 1043 Lamp_TrnSigLmpLftActiveSt 5000;
BA_ "Version" SG_ 1043 Lamp_TrnSigLmpLftActiveSt "19.11.00";
BA_ "GenMsgSendType" BO_ 1044 0;
BA_ "Description" SG_ 1044 ICU_Crc5Val "The data area for CRC calculation is based on the data length (DLC) of the message DB.

The CRC shall be calculated over the entire data block (excluding the CRC bytes) including the user data, alive counter and Data ID 

 

- CRC Polynomial (0x1D) , Initial Value : 0x00, XOR value : 0xFF, Data ID Mode : Both, Data ID : Message ID + 0xF800 

- The initial value is for CRC calculation and the message should be sent with the calculated result value. 

The mathematical expression to 8 bit CRC polynomial is given here. G(x) = x8 + x4 + x3 + x2 + 1";
BA_ "GenSigSendType" SG_ 1044 ICU_Crc5Val 4;
BA_ "GenSigStartValue" SG_ 1044 ICU_Crc5Val 255;
BA_ "UserSigValidity" SG_ 1044 ICU_Crc5Val 0;
BA_REL_ "GenSigTimeoutTime" BU_SG_REL_ vHS_M SG_ 1044 ICU_Crc5Val 1500;
BA_ "Version" SG_ 1044 ICU_Crc5Val "18.11.08";
BA_ "Description" SG_ 1044 ICU_AlvCnt5Val "For the first transmission request for a data element the counter shall be initialized with 0 and shall be incremented by 1

for every subsequent send request. When the counter reaches the maximum value(0xE), then it shall restart with 0 for the next send request";
BA_ "GenSigSendType" SG_ 1044 ICU_AlvCnt5Val 4;
BA_ "UserSigValidity" SG_ 1044 ICU_AlvCnt5Val 0;
BA_ "Version" SG_ 1044 ICU_AlvCnt5Val "18.11.08";
BA_ "Description" SG_ 1044 Trunk_TrnkInReleaseSwSta "-Trunk Inner Release SW";
BA_ "GenSigSendType" SG_ 1044 Trunk_TrnkInReleaseSwSta 4;
BA_ "UserSigValidity" SG_ 1044 Trunk_TrnkInReleaseSwSta 0;
BA_ "NetworkRequest" SG_ 1044 Trunk_TrnkInReleaseSwSta 0;
BA_ "NetworkRequestHoldingTime" SG_ 1044 Trunk_TrnkInReleaseSwSta 5000;
BA_ "Version" SG_ 1044 Trunk_TrnkInReleaseSwSta "17.12.00";
BA_ "Description" SG_ 1044 Trunk_TrnkTlgtOutReleaseSwSta "-(Old)C_TRUNK_LID

-Trunk/Tailgate Outter Release SW";
BA_ "GenSigSendType" SG_ 1044 Trunk_TrnkTlgtOutReleaseSwSta 4;
BA_ "UserSigValidity" SG_ 1044 Trunk_TrnkTlgtOutReleaseSwSta 0;
BA_ "NetworkRequest" SG_ 1044 Trunk_TrnkTlgtOutReleaseSwSta 0;
BA_ "NetworkRequestHoldingTime" SG_ 1044 Trunk_TrnkTlgtOutReleaseSwSta 5000;
BA_ "Version" SG_ 1044 Trunk_TrnkTlgtOutReleaseSwSta "17.12.00";
BA_ "Description" SG_ 1044 Trunk_TrnkTlgtSwSta "Full Lock SW Status Signal



(TailGate/TrunkLid Tpye all)



1. Luggage or Trunkroom Lamp On/Off



2. TailGate/TrunkLid Open Ind in cluster



3. Normal Open SW



  - SW Off: Full Lock(Full Close state)



  - SW On: ^Full Lock";
BA_ "GenSigSendType" SG_ 1044 Trunk_TrnkTlgtSwSta 4;
BA_ "UserSigValidity" SG_ 1044 Trunk_TrnkTlgtSwSta 0;
BA_REL_ "GenSigTimeoutTime" BU_SG_REL_ AMP SG_ 1044 Trunk_TrnkTlgtSwSta 1500;
BA_ "NetworkRequest" SG_ 1044 Trunk_TrnkTlgtSwSta 0;
BA_ "NetworkRequestHoldingTime" SG_ 1044 Trunk_TrnkTlgtSwSta 5000;
BA_ "Version" SG_ 1044 Trunk_TrnkTlgtSwSta "17.12.00";
BA_ "Description" SG_ 1044 Trunk_GlvBxTrnkLkSwSta "- Glove Box Trunk Lock SW";
BA_ "GenSigSendType" SG_ 1044 Trunk_GlvBxTrnkLkSwSta 4;
BA_ "UserSigValidity" SG_ 1044 Trunk_GlvBxTrnkLkSwSta 0;
BA_ "NetworkRequest" SG_ 1044 Trunk_GlvBxTrnkLkSwSta 0;
BA_ "NetworkRequestHoldingTime" SG_ 1044 Trunk_GlvBxTrnkLkSwSta 5000;
BA_ "Version" SG_ 1044 Trunk_GlvBxTrnkLkSwSta "17.12.00";
BA_ "GenSigSendType" SG_ 1044 Trunk_TrnkTlgtReleaseRlySta 4;
BA_ "UserSigValidity" SG_ 1044 Trunk_TrnkTlgtReleaseRlySta 0;
BA_ "NetworkRequest" SG_ 1044 Trunk_TrnkTlgtReleaseRlySta 0;
BA_ "NetworkRequestHoldingTime" SG_ 1044 Trunk_TrnkTlgtReleaseRlySta 5000;
BA_ "Version" SG_ 1044 Trunk_TrnkTlgtReleaseRlySta "17.12.00";
BA_ "Description" SG_ 1044 USM_OneTouchTrnSigFuncSta "This signal is 



- For One Touch Turn Signal Function,



 the advanced version of One Touch triple turn signal



- Communicated with Cluster for setting USM



- Periodic Event Signal to notice current staus to USM of Cluster";
BA_ "GenSigSendType" SG_ 1044 USM_OneTouchTrnSigFuncSta 4;
BA_ "UserSigValidity" SG_ 1044 USM_OneTouchTrnSigFuncSta 0;
BA_ "NetworkRequest" SG_ 1044 USM_OneTouchTrnSigFuncSta 0;
BA_ "NetworkRequestHoldingTime" SG_ 1044 USM_OneTouchTrnSigFuncSta 5000;
BA_ "Version" SG_ 1044 USM_OneTouchTrnSigFuncSta "17.12.00";
BA_ "GenSigSendType" SG_ 1044 Defog_DfgrRlySta 4;
BA_ "UserSigValidity" SG_ 1044 Defog_DfgrRlySta 0;
BA_ "NetworkRequest" SG_ 1044 Defog_DfgrRlySta 0;
BA_ "NetworkRequestHoldingTime" SG_ 1044 Defog_DfgrRlySta 5000;
BA_ "Version" SG_ 1044 Defog_DfgrRlySta "17.12.00";
BA_ "GenMsgSendType" BO_ 1046 0;
BA_ "Description" SG_ 1046 ICU_Crc6Val "The data area for CRC calculation is based on the data length (DLC) of the message DB.

The CRC shall be calculated over the entire data block (excluding the CRC bytes) including the user data, alive counter and Data ID 

 

- CRC Polynomial (0x1D) , Initial Value : 0x00, XOR value : 0xFF, Data ID Mode : Both, Data ID : Message ID + 0xF800 

- The initial value is for CRC calculation and the message should be sent with the calculated result value. 

The mathematical expression to 8 bit CRC polynomial is given here. G(x) = x8 + x4 + x3 + x2 + 1";
BA_ "GenSigSendType" SG_ 1046 ICU_Crc6Val 4;
BA_ "GenSigStartValue" SG_ 1046 ICU_Crc6Val 255;
BA_ "UserSigValidity" SG_ 1046 ICU_Crc6Val 0;
BA_REL_ "GenSigTimeoutTime" BU_SG_REL_ vHS_M SG_ 1046 ICU_Crc6Val 1500;
BA_ "Version" SG_ 1046 ICU_Crc6Val "18.11.08";
BA_ "Description" SG_ 1046 ICU_AlvCnt6Val "For the first transmission request for a data element the counter shall be initialized with 0 and shall be incremented by 1

for every subsequent send request. When the counter reaches the maximum value(0xE), then it shall restart with 0 for the next send request";
BA_ "GenSigSendType" SG_ 1046 ICU_AlvCnt6Val 4;
BA_ "UserSigValidity" SG_ 1046 ICU_AlvCnt6Val 0;
BA_ "Version" SG_ 1046 ICU_AlvCnt6Val "18.11.08";
BA_ "Description" SG_ 1046 Lamp_RrTrnSigLmpLftOpnSta "Rear T/SIG Lamp



Left OpenStatus";
BA_ "GenSigSendType" SG_ 1046 Lamp_RrTrnSigLmpLftOpnSta 4;
BA_ "UserSigValidity" SG_ 1046 Lamp_RrTrnSigLmpLftOpnSta 0;
BA_ "NetworkRequest" SG_ 1046 Lamp_RrTrnSigLmpLftOpnSta 0;
BA_ "NetworkRequestHoldingTime" SG_ 1046 Lamp_RrTrnSigLmpLftOpnSta 5000;
BA_ "Version" SG_ 1046 Lamp_RrTrnSigLmpLftOpnSta "17.12.00";
BA_ "Description" SG_ 1046 Lamp_RrTrnSigLmpRtOpnSta "Rear T/SIG Lamp



Right OpenStatus";
BA_ "GenSigSendType" SG_ 1046 Lamp_RrTrnSigLmpRtOpnSta 4;
BA_ "UserSigValidity" SG_ 1046 Lamp_RrTrnSigLmpRtOpnSta 0;
BA_ "NetworkRequest" SG_ 1046 Lamp_RrTrnSigLmpRtOpnSta 0;
BA_ "NetworkRequestHoldingTime" SG_ 1046 Lamp_RrTrnSigLmpRtOpnSta 5000;
BA_ "Version" SG_ 1046 Lamp_RrTrnSigLmpRtOpnSta "17.12.00";
BA_ "Description" SG_ 1046 Lamp_FrTrnSigLmpLftOpnSta "Front T/SIG Lamp



Left OpenStatus";
BA_ "GenSigSendType" SG_ 1046 Lamp_FrTrnSigLmpLftOpnSta 4;
BA_ "UserSigValidity" SG_ 1046 Lamp_FrTrnSigLmpLftOpnSta 0;
BA_ "NetworkRequest" SG_ 1046 Lamp_FrTrnSigLmpLftOpnSta 0;
BA_ "NetworkRequestHoldingTime" SG_ 1046 Lamp_FrTrnSigLmpLftOpnSta 5000;
BA_ "Version" SG_ 1046 Lamp_FrTrnSigLmpLftOpnSta "17.12.00";
BA_ "Description" SG_ 1046 Lamp_FrTrnSigLmpRtOpnSta "Front T/SIG Lamp



Right OpenStatus";
BA_ "GenSigSendType" SG_ 1046 Lamp_FrTrnSigLmpRtOpnSta 4;
BA_ "UserSigValidity" SG_ 1046 Lamp_FrTrnSigLmpRtOpnSta 0;
BA_ "NetworkRequest" SG_ 1046 Lamp_FrTrnSigLmpRtOpnSta 0;
BA_ "NetworkRequestHoldingTime" SG_ 1046 Lamp_FrTrnSigLmpRtOpnSta 5000;
BA_ "Version" SG_ 1046 Lamp_FrTrnSigLmpRtOpnSta "17.12.00";
BA_ "GenMsgSendType" BO_ 1040 0;
BA_ "Description" SG_ 1040 ICU_Crc10Val "The data area for CRC calculation is based on the data length (DLC) of the message DB.

The CRC shall be calculated over the entire data block (excluding the CRC bytes) including the user data, alive counter and Data ID 

 

- CRC Polynomial (0x1D) , Initial Value : 0x00, XOR value : 0xFF, Data ID Mode : Both, Data ID : Message ID + 0xF800 

- The initial value is for CRC calculation and the message should be sent with the calculated result value. 

The mathematical expression to 8 bit CRC polynomial is given here. G(x) = x8 + x4 + x3 + x2 + 1";
BA_ "GenSigSendType" SG_ 1040 ICU_Crc10Val 4;
BA_ "GenSigStartValue" SG_ 1040 ICU_Crc10Val 255;
BA_ "UserSigValidity" SG_ 1040 ICU_Crc10Val 0;
BA_REL_ "GenSigTimeoutTime" BU_SG_REL_ vHS_M SG_ 1040 ICU_Crc10Val 1500;
BA_ "Version" SG_ 1040 ICU_Crc10Val "18.11.08";
BA_ "Description" SG_ 1040 BmsFailWarning "If a 12V lithium battery fails, it is a signal that is sent according to the type of fault.";
BA_ "GenSigSendType" SG_ 1040 BmsFailWarning 4;
BA_ "UserSigValidity" SG_ 1040 BmsFailWarning 0;
BA_ "Version" SG_ 1040 BmsFailWarning "20.04.05";
BA_ "Description" SG_ 1040 ICU_AlvCnt10Val "For the first transmission request for a data element the counter shall be initialized with 0 and shall be incremented by 1

for every subsequent send request. When the counter reaches the maximum value(0xE), then it shall restart with 0 for the next send request";
BA_ "GenSigSendType" SG_ 1040 ICU_AlvCnt10Val 4;
BA_ "UserSigValidity" SG_ 1040 ICU_AlvCnt10Val 0;
BA_ "Version" SG_ 1040 ICU_AlvCnt10Val "18.11.08";
BA_ "Description" SG_ 1040 ICU_BS2SoC "This signal is battery State of Charge as calculated by battery sensor.";
BA_ "GenSigSendType" SG_ 1040 ICU_BS2SoC 4;
BA_ "GenSigStartValue" SG_ 1040 ICU_BS2SoC 255;
BA_ "UserSigValidity" SG_ 1040 ICU_BS2SoC 3;
BA_REL_ "GenSigTimeoutTime" BU_SG_REL_ AMP SG_ 1040 ICU_BS2SoC 1500;
BA_ "Version" SG_ 1040 ICU_BS2SoC "20.08.07";
BA_ "Description" SG_ 1040 ICU_BS2NCap "Nominal capacity";
BA_ "GenSigSendType" SG_ 1040 ICU_BS2NCap 4;
BA_ "GenSigStartValue" SG_ 1040 ICU_BS2NCap 255;
BA_ "UserSigValidity" SG_ 1040 ICU_BS2NCap 3;
BA_ "Version" SG_ 1040 ICU_BS2NCap "17.12.00";
BA_ "Description" SG_ 1040 ICU_BS2OpnCirVol "Last open circuit voltage";
BA_ "GenSigSendType" SG_ 1040 ICU_BS2OpnCirVol 4;
BA_ "GenSigStartValue" SG_ 1040 ICU_BS2OpnCirVol 4095;
BA_ "UserSigValidity" SG_ 1040 ICU_BS2OpnCirVol 3;
BA_ "Version" SG_ 1040 ICU_BS2OpnCirVol "17.12.00";
BA_ "Description" SG_ 1040 ICU_BS2_FSOC "This signal indicates whether the state of SOC signal is fault or not";
BA_ "GenSigSendType" SG_ 1040 ICU_BS2_FSOC 4;
BA_ "GenSigStartValue" SG_ 1040 ICU_BS2_FSOC 1;
BA_ "UserSigValidity" SG_ 1040 ICU_BS2_FSOC 3;
BA_ "Version" SG_ 1040 ICU_BS2_FSOC "18.08.03";
BA_ "Description" SG_ 1040 ICU_BS2_FSOH "This signal indicates whether the state of SOH signal is fault or not";
BA_ "GenSigSendType" SG_ 1040 ICU_BS2_FSOH 4;
BA_ "GenSigStartValue" SG_ 1040 ICU_BS2_FSOH 1;
BA_ "UserSigValidity" SG_ 1040 ICU_BS2_FSOH 3;
BA_ "Version" SG_ 1040 ICU_BS2_FSOH "18.08.03";
BA_ "Description" SG_ 1040 ICU_BS2_FSOF "This signal indicates whether the state of SOF signal is fault or not";
BA_ "GenSigSendType" SG_ 1040 ICU_BS2_FSOF 4;
BA_ "GenSigStartValue" SG_ 1040 ICU_BS2_FSOF 1;
BA_ "UserSigValidity" SG_ 1040 ICU_BS2_FSOF 3;
BA_ "Version" SG_ 1040 ICU_BS2_FSOF "18.08.03";
BA_ "Description" SG_ 1040 ICU_BS2_FQSTAT "This signal indicates whether quiescent current is high or not compared to pre-defined value";
BA_ "GenSigSendType" SG_ 1040 ICU_BS2_FQSTAT 4;
BA_ "GenSigStartValue" SG_ 1040 ICU_BS2_FQSTAT 1;
BA_ "UserSigValidity" SG_ 1040 ICU_BS2_FQSTAT 3;
BA_ "Version" SG_ 1040 ICU_BS2_FQSTAT "18.08.03";
BA_ "Description" SG_ 1040 ICU_BS2SoH "This signal is battery State of Health(SOH) as calculated by battery sensor.



This value shows reduction rate of nominal capacity.



This value can be used for diagnosis information of application system.";
BA_ "GenSigSendType" SG_ 1040 ICU_BS2SoH 4;
BA_ "GenSigStartValue" SG_ 1040 ICU_BS2SoH 255;
BA_ "UserSigValidity" SG_ 1040 ICU_BS2SoH 3;
BA_ "Version" SG_ 1040 ICU_BS2SoH "17.12.00";
BA_ "Description" SG_ 1040 ICU_BS2SoF "This signal is battery State of Function(SOF) as calculated by battery sensor.



This value shows information about the battery ability to crank the engine (both of warm & cold cranking).



This value is prediction value of the minimum voltage for the next cranking.";
BA_ "GenSigSendType" SG_ 1040 ICU_BS2SoF 4;
BA_ "GenSigStartValue" SG_ 1040 ICU_BS2SoF 255;
BA_ "UserSigValidity" SG_ 1040 ICU_BS2SoF 3;
BA_ "Version" SG_ 1040 ICU_BS2SoF "17.12.00";
BA_ "GenMsgSendType" BO_ 579 0;
BA_ "Description" SG_ 579 OHCL_Opt "This signal is OHCL(OverHead Console Lamp)  ECU Option state";
BA_ "GenSigSendType" SG_ 579 OHCL_Opt 4;
BA_ "TimeoutValue" SG_ 579 OHCL_Opt "Old Value";
BA_ "UserSigValidity" SG_ 579 OHCL_Opt 3;
BA_REL_ "GenSigTimeoutTime" BU_SG_REL_ ATS SG_ 579 OHCL_Opt 1000;
BA_ "Version" SG_ 579 OHCL_Opt "19.12.01";
BA_ "Description" SG_ 579 OHCL_Sys_sta "This signal is OHCL (OverHead Console Lamp) system state";
BA_ "GenSigSendType" SG_ 579 OHCL_Sys_sta 4;
BA_ "TimeoutValue" SG_ 579 OHCL_Sys_sta "0x3";
BA_ "UserSigValidity" SG_ 579 OHCL_Sys_sta 3;
BA_REL_ "GenSigTimeoutTime" BU_SG_REL_ ATS SG_ 579 OHCL_Sys_sta 1000;
BA_ "Version" SG_ 579 OHCL_Sys_sta "19.12.01";
BA_ "Description" SG_ 579 OHCL_DoorOn_Sta "This signal is door lamp switch On/Off status";
BA_ "GenSigSendType" SG_ 579 OHCL_DoorOn_Sta 4;
BA_ "TimeoutValue" SG_ 579 OHCL_DoorOn_Sta "Old Value";
BA_ "UserSigValidity" SG_ 579 OHCL_DoorOn_Sta 3;
BA_REL_ "GenSigTimeoutTime" BU_SG_REL_ ATS SG_ 579 OHCL_DoorOn_Sta 1000;
BA_ "Version" SG_ 579 OHCL_DoorOn_Sta "19.12.01";
BA_ "Description" SG_ 579 OHCL_RrMapLftOn_Sta "This signal is rear left map lamp On/Off status";
BA_ "GenSigSendType" SG_ 579 OHCL_RrMapLftOn_Sta 4;
BA_ "TimeoutValue" SG_ 579 OHCL_RrMapLftOn_Sta "Old Value";
BA_ "UserSigValidity" SG_ 579 OHCL_RrMapLftOn_Sta 3;
BA_REL_ "GenSigTimeoutTime" BU_SG_REL_ ATS SG_ 579 OHCL_RrMapLftOn_Sta 1000;
BA_ "Version" SG_ 579 OHCL_RrMapLftOn_Sta "19.12.01";
BA_ "Description" SG_ 579 OHCL_RrMapRtOn_Sta "This signal is rear right map lamp On/Off status";
BA_ "GenSigSendType" SG_ 579 OHCL_RrMapRtOn_Sta 4;
BA_ "TimeoutValue" SG_ 579 OHCL_RrMapRtOn_Sta "Old Value";
BA_ "UserSigValidity" SG_ 579 OHCL_RrMapRtOn_Sta 3;
BA_REL_ "GenSigTimeoutTime" BU_SG_REL_ ATS SG_ 579 OHCL_RrMapRtOn_Sta 1000;
BA_ "Version" SG_ 579 OHCL_RrMapRtOn_Sta "19.12.01";
BA_ "Description" SG_ 579 OHCL_RrRoomOn_Sta "This signal is rear room map lamp On/Off status ( all )";
BA_ "GenSigSendType" SG_ 579 OHCL_RrRoomOn_Sta 4;
BA_ "TimeoutValue" SG_ 579 OHCL_RrRoomOn_Sta "Old Value";
BA_ "UserSigValidity" SG_ 579 OHCL_RrRoomOn_Sta 3;
BA_REL_ "GenSigTimeoutTime" BU_SG_REL_ ATS SG_ 579 OHCL_RrRoomOn_Sta 1000;
BA_ "Version" SG_ 579 OHCL_RrRoomOn_Sta "19.12.01";
BA_ "Description" SG_ 579 OHCL_RrMoodOn_Sta "This signal is rear mood map lamp On/Off status";
BA_ "GenSigSendType" SG_ 579 OHCL_RrMoodOn_Sta 4;
BA_ "TimeoutValue" SG_ 579 OHCL_RrMoodOn_Sta "Old Value";
BA_ "UserSigValidity" SG_ 579 OHCL_RrMoodOn_Sta 3;
BA_REL_ "GenSigTimeoutTime" BU_SG_REL_ ATS SG_ 579 OHCL_RrMoodOn_Sta 1000;
BA_ "Version" SG_ 579 OHCL_RrMoodOn_Sta "19.12.01";
BA_ "Description" SG_ 579 OHCL_LEDClr_Sta "This signal is interior lamps lighting color status";
BA_ "GenSigSendType" SG_ 579 OHCL_LEDClr_Sta 4;
BA_ "TimeoutValue" SG_ 579 OHCL_LEDClr_Sta "Old Value";
BA_ "UserSigValidity" SG_ 579 OHCL_LEDClr_Sta 3;
BA_REL_ "GenSigTimeoutTime" BU_SG_REL_ ATS SG_ 579 OHCL_LEDClr_Sta 1000;
BA_ "Version" SG_ 579 OHCL_LEDClr_Sta "19.12.01";
BA_ "Description" SG_ 579 OHCL_LEDBgtns_Sta "This signal is interior lamps brightness status";
BA_ "GenSigSendType" SG_ 579 OHCL_LEDBgtns_Sta 4;
BA_ "TimeoutValue" SG_ 579 OHCL_LEDBgtns_Sta "Old Value";
BA_ "UserSigValidity" SG_ 579 OHCL_LEDBgtns_Sta 3;
BA_REL_ "GenSigTimeoutTime" BU_SG_REL_ ATS SG_ 579 OHCL_LEDBgtns_Sta 1000;
BA_ "Version" SG_ 579 OHCL_LEDBgtns_Sta "19.12.01";
BA_ "Description" SG_ 579 OHCL_TllTlLmpSta "This signal is PAB tell tale lamp status signal

( ACU_TllTlLmpDis feedback signal )";
BA_ "GenSigSendType" SG_ 579 OHCL_TllTlLmpSta 4;
BA_ "GenSigStartValue" SG_ 579 OHCL_TllTlLmpSta 3;
BA_ "UserSigValidity" SG_ 579 OHCL_TllTlLmpSta 3;
BA_ "Version" SG_ 579 OHCL_TllTlLmpSta "20.07.08";
BA_ "Description" SG_ 579 OHCL_FrMapLftOn_Sta "This signal is front left map lamp On/Off status";
BA_ "GenSigSendType" SG_ 579 OHCL_FrMapLftOn_Sta 4;
BA_ "TimeoutValue" SG_ 579 OHCL_FrMapLftOn_Sta "0x0";
BA_ "UserSigValidity" SG_ 579 OHCL_FrMapLftOn_Sta 3;
BA_REL_ "GenSigTimeoutTime" BU_SG_REL_ ATS SG_ 579 OHCL_FrMapLftOn_Sta 1000;
BA_ "Version" SG_ 579 OHCL_FrMapLftOn_Sta "19.12.01";
BA_ "Description" SG_ 579 OHCL_FrMapRtOn_Sta "This signal is front right map lamp On/Off status";
BA_ "GenSigSendType" SG_ 579 OHCL_FrMapRtOn_Sta 4;
BA_ "TimeoutValue" SG_ 579 OHCL_FrMapRtOn_Sta "Old Value";
BA_ "UserSigValidity" SG_ 579 OHCL_FrMapRtOn_Sta 3;
BA_REL_ "GenSigTimeoutTime" BU_SG_REL_ ATS SG_ 579 OHCL_FrMapRtOn_Sta 1000;
BA_ "Version" SG_ 579 OHCL_FrMapRtOn_Sta "19.12.01";
BA_ "Description" SG_ 579 OHCL_FrRoomOn_Sta "This signal is front room lamp On/Off status ( all )";
BA_ "GenSigSendType" SG_ 579 OHCL_FrRoomOn_Sta 4;
BA_ "TimeoutValue" SG_ 579 OHCL_FrRoomOn_Sta "Old Value";
BA_ "UserSigValidity" SG_ 579 OHCL_FrRoomOn_Sta 3;
BA_REL_ "GenSigTimeoutTime" BU_SG_REL_ ATS SG_ 579 OHCL_FrRoomOn_Sta 1000;
BA_ "Version" SG_ 579 OHCL_FrRoomOn_Sta "19.12.01";
BA_ "Description" SG_ 579 OHCL_FrMoodOn_Sta "This signal is front mood map lamp On/Off status";
BA_ "GenSigSendType" SG_ 579 OHCL_FrMoodOn_Sta 4;
BA_ "UserSigValidity" SG_ 579 OHCL_FrMoodOn_Sta 3;
BA_REL_ "GenSigTimeoutTime" BU_SG_REL_ ATS SG_ 579 OHCL_FrMoodOn_Sta 1000;
BA_ "Version" SG_ 579 OHCL_FrMoodOn_Sta "19.12.01";
BA_ "GenMsgSendType" BO_ 1067 0;
BA_ "Description" SG_ 1067 HWSW_SysSta "This signal indicates normal or failure status of HSWS. 



 - HSWS : Haptic Steering Warning System";
BA_ "GenSigSendType" SG_ 1067 HWSW_SysSta 4;
BA_ "UserSigValidity" SG_ 1067 HWSW_SysSta 3;
BA_ "NetworkRequest" SG_ 1067 HWSW_SysSta 0;
BA_ "NetworkRequestHoldingTime" SG_ 1067 HWSW_SysSta 5000;
BA_ "Version" SG_ 1067 HWSW_SysSta "17.11.00";
BA_ "GenSigSendType" SG_ 1067 USM_CmdSta 4;
BA_ "UserSigValidity" SG_ 1067 USM_CmdSta 0;
BA_REL_ "GenSigTimeoutTime" BU_SG_REL_ PSM SG_ 1067 USM_CmdSta 1500;
BA_ "NetworkRequest" SG_ 1067 USM_CmdSta 0;
BA_ "NetworkRequestHoldingTime" SG_ 1067 USM_CmdSta 5000;
BA_ "Version" SG_ 1067 USM_CmdSta "17.11.00";
BA_ "GenSigSendType" SG_ 1067 SCM_HptWrngUSMSta 4;
BA_ "UserSigValidity" SG_ 1067 SCM_HptWrngUSMSta 0;
BA_ "NetworkRequest" SG_ 1067 SCM_HptWrngUSMSta 0;
BA_ "NetworkRequestHoldingTime" SG_ 1067 SCM_HptWrngUSMSta 5000;
BA_ "Version" SG_ 1067 SCM_HptWrngUSMSta "18.11.06";
BA_ "Description" SG_ 1067 SCM_Haptic_OPT "Steering Wheel Haptic Warning Option Information";
BA_ "GenSigSendType" SG_ 1067 SCM_Haptic_OPT 4;
BA_ "UserSigValidity" SG_ 1067 SCM_Haptic_OPT 0;
BA_ "Version" SG_ 1067 SCM_Haptic_OPT "18.07.01";
BA_ "Description" SG_ 1067 SCM_TeleMvmntVal "STEERING COLUMN TELE POSITION";
BA_ "GenSigSendType" SG_ 1067 SCM_TeleMvmntVal 4;
BA_ "UserSigValidity" SG_ 1067 SCM_TeleMvmntVal 0;
BA_ "NetworkRequest" SG_ 1067 SCM_TeleMvmntVal 0;
BA_ "NetworkRequestHoldingTime" SG_ 1067 SCM_TeleMvmntVal 5000;
BA_ "Version" SG_ 1067 SCM_TeleMvmntVal "18.05.02";
BA_ "Description" SG_ 1067 SCM_TiltMvmntVal "STEERING COLUMN TILT POSITION";
BA_ "GenSigSendType" SG_ 1067 SCM_TiltMvmntVal 4;
BA_ "UserSigValidity" SG_ 1067 SCM_TiltMvmntVal 0;
BA_ "NetworkRequest" SG_ 1067 SCM_TiltMvmntVal 0;
BA_ "NetworkRequestHoldingTime" SG_ 1067 SCM_TiltMvmntVal 5000;
BA_ "Version" SG_ 1067 SCM_TiltMvmntVal "20.05.02";
BA_ "Description" SG_ 1067 SCM_PlyBckSta "This signal indicates the steering column playback status for IMS";
BA_ "GenSigSendType" SG_ 1067 SCM_PlyBckSta 4;
BA_ "UserSigValidity" SG_ 1067 SCM_PlyBckSta 0;
BA_REL_ "GenSigTimeoutTime" BU_SG_REL_ PSM SG_ 1067 SCM_PlyBckSta 1500;
BA_ "NetworkRequest" SG_ 1067 SCM_PlyBckSta 0;
BA_ "NetworkRequestHoldingTime" SG_ 1067 SCM_PlyBckSta 5000;
BA_ "Version" SG_ 1067 SCM_PlyBckSta "18.07.01";
BA_ "Description" SG_ 1067 SCM_SWVerMajor1 "Indicate the SCM software version as follows:

- The software version is displayed in three digits.

- The Major and Minor digits are separated by '.'

- Signal values are transmitted to ASCII codes.



※ Example

SCM_SWVerMajor1 : 0x41 (HEX) -> ASCII CODE : 'A' 

SCM_SWVerMinor1 : 0x30 (HEX) -> ASCII CODE : '0'

SCM_SWVerMinor2 : 0x33 (HEX) -> ASCII CODE : '3'

=> SCM S/W Ver is displayed 'A.03'";
BA_ "GenSigSendType" SG_ 1067 SCM_SWVerMajor1 4;
BA_ "UserSigValidity" SG_ 1067 SCM_SWVerMajor1 0;
BA_ "Version" SG_ 1067 SCM_SWVerMajor1 "20.12.04";
BA_ "Description" SG_ 1067 SCM_SWVerMinor1 "Indicate the SCM software version as follows:

- The software version is displayed in three digits.

- The Major and Minor digits are separated by '.'

- Signal values are transmitted to ASCII codes.



※ Example

SCM_SWVerMajor1 : 0x41 (HEX) -> ASCII CODE : 'A' 

SCM_SWVerMinor1 : 0x30 (HEX) -> ASCII CODE : '0'

SCM_SWVerMinor2 : 0x33 (HEX) -> ASCII CODE : '3'

=> SCM S/W Ver is displayed 'A.03'";
BA_ "GenSigSendType" SG_ 1067 SCM_SWVerMinor1 4;
BA_ "UserSigValidity" SG_ 1067 SCM_SWVerMinor1 0;
BA_ "Version" SG_ 1067 SCM_SWVerMinor1 "18.10.06";
BA_ "Description" SG_ 1067 SCM_SWVerMinor2 "Indicate the SCM software version as follows:

- The software version is displayed in three digits.

- The Major and Minor digits are separated by '.'

- Signal values are transmitted to ASCII codes.



※ Example

SCM_SWVerMajor1 : 0x41 (HEX) -> ASCII CODE : 'A' 

SCM_SWVerMinor1 : 0x30 (HEX) -> ASCII CODE : '0'

SCM_SWVerMinor2 : 0x33 (HEX) -> ASCII CODE : '3'

=> SCM S/W Ver is displayed 'A.03'";
BA_ "GenSigSendType" SG_ 1067 SCM_SWVerMinor2 4;
BA_ "UserSigValidity" SG_ 1067 SCM_SWVerMinor2 0;
BA_ "Version" SG_ 1067 SCM_SWVerMinor2 "18.10.06";
VAL_ 1548 AMP_ASDModeState 0 "Not use" 1 "ASD OFF" 2 "Reserved" 3 "ASD ON" 4 "Reserved" 5 "Reserved" 6 "Reserved" 7 "Invalid" ;
VAL_ 1548 AMP_SPDIFInfo 0 "Not used" 1 "Unlock" 2 "Null" 3 "PCM" 4 "Compressed" 5 "Reserved" 6 "Reserved" 7 "Invalid" ;
VAL_ 1548 AMP_NaviModeState 0 "Navi Off" 1 "Navi ON" 2 "Unused" 3 "Invalid" ;
VAL_ 1548 AMP_EngASDMasterGainState 0 "Reserved" 1 "Reserved" 2 "Reserved" 3 "MasterGain" 4 "MasterGain" 5 "MasterGain" 6 "MasterGain" 7 "MasterGain" 8 "MasterGain" 9 "MasterGain" 10 "MasterGain" 11 "MasterGain" 12 "MasterGain" 13 "MasterGain" 14 "MasterGain" 15 "MasterGain" 16 "MasterGain" 17 "MasterGain" 18 "MasterGain" 19 "MasterGain" 20 "MasterGain" 21 "MasterGain" 22 "MasterGain" 23 "MasterGain" 24 "MasterGain" 25 "MasterGain" 26 "MasterGain" 27 "MasterGain" 28 "Reserved" 29 "Reserved" 30 "Reserved" 31 "invalid" ;
VAL_ 1548 AMP_SDVCStepState 0 "off" 1 "low" 2 "mid" 3 "high" 7 "Invalid" ;
VAL_ 1548 AMP_Beep1KBDModeState 0 "Beep1 mode off" 1 "Beep1 mode On" 2 "Unsed" 3 "InValid" ;
VAL_ 1548 AMP_Beep1ModeState 0 "Beep1 mode off" 1 "Beep1 mode On" 2 "Unsed" 3 "InValid" ;
VAL_ 1548 HU_InitInfo 0 "Not used" 1 "Init_request" 2 "Init_completed" 3 "Invalid" ;
VAL_ 1548 AMP_MasterBeepVolumeState 0 "Invalid" 1 "level 1" 2 "level 2" 3 "level 3" 4 "level 4" 5 "level 5" 6 "Invalid" 7 "Invalid" ;
VAL_ 1548 AMP_ANCModeState 0 "Not used" 1 "ANC Off" 2 "ANC On" 3 "Invalid" ;
VAL_ 1548 AMP_DistrInfoState 255 "Invalid" ;
VAL_ 1548 AMP_TTSModeState 0 "TTS Off" 1 "TTS ON" 2 "Unused" 3 "Invalid" ;
VAL_ 1548 AMP_INFORM_TO_IPM 0 "off" 1 "Warning Sound Supportable" 2 "Reserved" 3 "Invalid" ;
VAL_ 1548 AMP_StartUpComplete 0 "Not used" 1 "Start-up completed" 2 "Reserved" 3 "Invalid" ;
VAL_ 1549 AMP_VirtualVenueModeStatus 0 "Off" 1 "Living room" 2 "Concert Hall" 3 "Stadium" 4 "Reserved" 5 "Reserved" 6 "Reserved" 7 "Invalid" ;
VAL_ 1549 AMP_EQState 0 "null" 1 "EQ Active" 2 "EQ loading" 3 "invalid" ;
VAL_ 1549 AMP_DriverModeStatus 0 "Off" 1 "On" 2 "Reserved" 3 "Invalid" ;
VAL_ 1549 AMP_WrnPromptModeSta 0 "Off" 1 "On" 2 "Reserved" 3 "Invalid" ;
VAL_ 1549 AMP_ESEVwarning 0 "knock sensor working normally" 1 "when detection knock sensor failure" 3 "AMP wakes up and does not detect knock sensor status" ;
VAL_ 1549 AMP_SPDIFMuteSt 0 "SPDIF Un- Mutef" 1 "SPDIF Mute On" 2 "Unused" 3 "Invalid" ;
VAL_ 1549 AMP_RANCwarning 0 "Normal" 1 "Fail" 2 "Reserved" 3 "Invalid" ;
VAL_ 1549 AMP_RANCstate 0 "RANC On" 1 "RANC Off" 2 "RANC Off2" 3 "RANC Off3" 4 "Reserved" 5 "Reserved" 6 "Reserved" 7 "Invalid" ;
VAL_ 1549 AMP_QLIModeStatus 0 "Off" 1 "Reference" 2 "Audience" 3 "OnStage" 4 "Reserved" 5 "Reserved" 6 "Reserved" 7 "Invalid" ;
VAL_ 1549 AMP_AudioSource 0 "Off" 1 "AM" 2 "FM" 3 "Reserved" 4 "XM_SIRIUS" 5 "DMB(South Korea Only)" 6 "Reserved" 7 "Reserved" 8 "Reserved" 9 "Reserved" 10 "Reserved" 11 "Reserved" 12 "Reserved" 13 "Reserved" 14 "Reserved" 15 "HDAudio(2ch)" 16 "CD(CDDA_MP3)" 17 "DVD DD" 18 "DVD DTS" 19 "RSE CD_MP3_VCD" 20 "RSE DD" 21 "RSE DTS" 22 "Reserved" 23 "Reserved" 24 "Reserved" 25 "Reserved" 26 "Reserved" 27 "Reserved" 28 "Reserved" 29 "Reserved" 30 "Reserved" 31 "Reserved" 32 "USB MP3" 33 "BT MP3" 34 "iPod" 35 "AUX" 36 "RSE AUX" 37 "HF(SPDIF)" 38 "MTS(SPDIF)" 39 "MTS(analog)" 40 "ZUNE" 41 "0x29~0xFE:Reserved" 254 "0x29~0xFE:Reserved" 255 "Invalid" ;
VAL_ 1549 AMP_QuietModeState 0 "QuietMode Off" 1 "QuietMode On" 2 "Reserved" 3 "Invalid" ;
VAL_ 1549 AMP_QLSModeState 0 "QLS OFF" 1 "On Stage" 2 "Audience" 3 "Invalid" ;
VAL_ 1549 AMP_VoiceGuideTTSLevelStatus 0 "Default" 1 "Level1" 2 "Level2" 3 "Level3" 4 "Reserved" 5 "Reserved" 6 "Reserved" 7 "Invalid" ;
VAL_ 1549 AMP_VoiceGuideTTSStatus 0 "Off" 1 "On" 2 "Reserved" 3 "Invalid" ;
VAL_ 1549 AMP_MuteState 0 "Not mute" 1 "mute" 2 "Unsed" 3 "Invalid" ;
VAL_ 1549 AMP_ALTPopUpStatus 0 "Close" 1 "PopUp" 2 "Error" 3 "Invalid" ;
VAL_ 1549 AMP_LogSnapshotState 0 "Reserved" 1 "Log Snapshot" 2 "Reserved" 3 "Invalid" ;
VAL_ 1550 AMP_MainVolumeSetting 0 "0x0x0~0xFD:AMP_MaxVolumeSteP(0x085)" 253 "0x0x0~0xFD:AMP_MaxVolumeSteP(0x085)" 254 "Invalid" 255 "Invalid" ;
VAL_ 1550 AMP_FadeSetting 0 "0x0x0~0xFE:AMP_MaxFadeStep(0x085)" 254 "0x0x0~0xFE:AMP_MaxFadeStep(0x085)" 255 "Invalid" ;
VAL_ 1550 AMP_BassSetting 0 "0x0x0~0xFE:AMP_MaxBassStep(0x085)" 254 "0x0x0~0xFE:AMP_MaxBassStep(0x085)" 255 "Invalid" ;
VAL_ 1550 AMP_MidSetting 0 "0x0x0~0xFE:AMP_MaxMidStep(0x085)" 254 "0x0x0~0xFE:AMP_MaxMidStep(0x085)" 255 "Invalid" ;
VAL_ 1550 AMP_TrebleSetting 0 "0x0x0~0xFE:AMP_MaxTrebleStep(0x085)" 254 "0x0x0~0xFE:AMP_MaxTrebleStep(0x085)" 255 "Invalid" ;
VAL_ 1550 AMP_ESEVModeState 0 "Not use" 1 "ASD OFF" 2 "Reserved" 3 "ASD ON" 4 "Reserved" 5 "Reserved" 6 "Reserved" 7 "Invalid" ;
VAL_ 1550 AMP_ESEVMasterGainState 0 "Reserved" 1 "Reserved" 2 "Reserved" 3 "MasterGain" 4 "MasterGain" 5 "MasterGain" 6 "MasterGain" 7 "MasterGain" 8 "MasterGain" 9 "MasterGain" 10 "MasterGain" 11 "MasterGain" 12 "MasterGain" 13 "MasterGain" 14 "MasterGain" 15 "MasterGain" 16 "MasterGain" 17 "MasterGain" 18 "MasterGain" 19 "MasterGain" 20 "MasterGain" 21 "MasterGain" 22 "MasterGain" 23 "MasterGain" 24 "MasterGain" 25 "MasterGain" 26 "MasterGain" 27 "MasterGain" 28 "Reserved" 29 "Reserved" 30 "Reserved" 31 "Invalid" ;
VAL_ 1550 AMP_BalanceSetting 0 "0x0x0~0xFE:AMP_MaxBalanceSteP(0x085)" 254 "0x0x0~0xFE:AMP_MaxBalanceSteP(0x085)" 255 "Invalid" ;
VAL_ 1551 AMP_ADASVolumeState 0 "Off" 1 "Level 1" 2 "Level 2" 3 "Level 3" 4 "Level 4" 5 "Level 5" 6 "Level 6" 7 "Level 7" 8 "Level 8" 9 "Level 9" 10 "Level 10" 11 "Reserved" 12 "Reserved" 13 "Reserved" 14 "Reserved" 15 "Invalid" ;
VAL_ 639 ATS_RLSeatHeaterUpSW 0 "Default" 1 "Short On" 2 "Long On" 3 "Invalid" ;
VAL_ 639 ATS_RRSeatVentDownSW 0 "Default" 1 "Short On" 2 "Long On" 3 "Invalid" ;
VAL_ 639 ATS_RLSeatVentDownSW 0 "Default" 1 "Short On" 2 "Long On" 3 "Invalid" ;
VAL_ 639 ATS_RLMemoryRestBtn 0 "Default" 1 "Off" 2 "On" 3 "Invalid" ;
VAL_ 639 ATS_RLMemoryReturnBtn 0 "Default" 1 "Off" 2 "On" 3 "Invalid" ;
VAL_ 639 ATS_RRMemoryRestBtn 0 "Default" 1 "Off" 2 "On" 3 "Invalid" ;
VAL_ 639 ATS_RRMemoryReturnBtn 0 "Default" 1 "Off" 2 "On" 3 "Invalid" ;
VAL_ 639 ATS_RRMemoryAvWtcBtn 0 "Default" 1 "Off" 2 "On" 3 "Invalid" ;
VAL_ 639 ATS_RRMemoryReadingBtn 0 "Default" 1 "Off" 2 "On" 3 "Invalid" ;
VAL_ 639 ATS_RRRestModBtnSTD 0 "Default" 1 "Off" 2 "On" 3 "Invalid" ;
VAL_ 639 ATS_RRResetModBtnSTD 0 "Default" 1 "Off" 2 "On" 3 "Invalid" ;
VAL_ 639 ATS_RRAvWtcModBtnSTD 0 "Default" 1 "Off" 2 "On" 3 "Invalid" ;
VAL_ 639 ATS_RRReadingModBtnSTD 0 "Default" 1 "Off" 2 "On" 3 "Invalid" ;
VAL_ 639 ATS_RLRestModBtnSTD 0 "Default" 1 "Off" 2 "On" 3 "Invalid" ;
VAL_ 639 ATS_RLResetModBtnSTD 0 "Default" 1 "Off" 2 "On" 3 "Invalid" ;
VAL_ 639 ATS_RRModestateStopBtn 0 "Default" 1 "Off" 2 "On" 3 "Invalid" ;
VAL_ 639 ATS_RLModestateStopBtn 0 "Default" 1 "Off" 2 "On" 3 "Invalid" ;
VAL_ 639 ATS_RLResetRestBtn 0 "Default" 1 "Off" 2 "On" 3 "Invalid" ;
VAL_ 639 ATS_RLResetReturnBtn 0 "Default" 1 "Off" 2 "On" 3 "Invalid" ;
VAL_ 639 ATS_RRResetRestBtn 0 "Default" 1 "Off" 2 "On" 3 "Invalid" ;
VAL_ 639 ATS_RRResetReturnBtn 0 "Default" 1 "Off" 2 "On" 3 "Invalid" ;
VAL_ 639 ATS_RRResetAvWtcBtn 0 "Default" 1 "Off" 2 "On" 3 "Invalid" ;
VAL_ 639 ATS_RRResetReadingBtn 0 "Default" 1 "Off" 2 "On" 3 "Invalid" ;
VAL_ 639 ATS_RRSeatHeaterUpSW 0 "Default" 1 "Short On" 2 "Long On" 3 "Invalid" ;
VAL_ 1050 Lamp_HiPrioHzrdReq 0 "Off" 1 "High On" 2 "High Inactive" 3 "Reserved" 4 "Reserved" 5 "Reseved" 6 "Not Used" 7 "Error Indicator" ;
VAL_ 1050 Lamp_LoPrioHzrdReq 0 "Off" 1 "Low On" 2 "Low Inactive" 3 "Reserved" 4 "Reserved" 5 "Reseved" 6 "Not Used" 7 "Error Indicator" ;
VAL_ 1050 Lamp_DedicatedDrlOnReq 0 "Off" 1 "On" 2 "Not Used" 3 "Error Indicator" ;
VAL_ 1050 Lamp_IntTailLmpOnReq 0 "Off" 1 "On" 2 "Not Used" 3 "Error Indicator" ;
VAL_ 1050 Lamp_ExtrnlTailLmpOnReq 0 "Off" 1 "On" 2 "Not Used" 3 "Error Indicator" ;
VAL_ 1050 Lamp_HdLmpLoOnReq 0 "Off" 1 "On" 2 "Not Used" 3 "Error Indicator" ;
VAL_ 1050 Lamp_HdLmpHiOnReq 0 "Off" 1 "On" 2 "Not Used" 3 "Error Indicator" ;
VAL_ 1050 Lamp_AvTailLmpSta 0 "Off" 1 "On" 2 "Not Used" 3 "Error Indicator" ;
VAL_ 1052 Lamp_AutoLtSnsrNightSta 0 "Off" 1 "Night" 2 "Not Used" 3 "Error Indicator" ;
VAL_ 1052 Lamp_VendorInfo 0 "Not Used" 1 "TRW(BCS)" 2 "HELLA" 3 "Not Used" 4 "Not Used" 5 "Not Used" 6 "Not Used" 7 "Error Indicator" ;
VAL_ 2424579841 DATC_TunnelFuncOff4AutoDfgReq 0 "Default" 1 "Tunnel Turn off" 2 "Not Used" 3 "Error Indicator" ;
VAL_ 2424579841 DATC_RrCtlLckSta 0 "Default" 1 "Rear Lock OFF" 2 "Rear Lock ON" 3 "Error Indicator" ;
VAL_ 2424579841 DATC_DrvrStHtrUSMSta 0 "NOT APPLY" 1 "OFF" 2 "ON" 3 "Error Indicator" ;
VAL_ 2424579841 DATC_WshFldUSMSta 0 "Default" 1 "OFF" 2 "ON" 3 "Invalid" ;
VAL_ 2424579841 DATC_DfgLgcUSMSta 0 "Default" 1 "OFF" 2 "ON" 3 "Invalid" ;
VAL_ 2424579841 DATC_AutoFrshUSMSta 0 "Default" 1 "OFF" 2 "ON" 3 "Invalid" ;
VAL_ 2424579841 DATC_HptIntnstySta 0 "Default" 1 "Haptic OFF" 2 "Haptic Intensity Level 1" 3 "Haptic Intensity Level 2" 4 "Haptic Intensity Level 3" 5 "Haptic Intensity Level 4" 6 "Haptic Intensity Level 5" 7 "Reserved" 8 "Reserved" 9 "Reserved" 10 "Reserved" 11 "Reserved" 12 "Reserved" 13 "Reserved" 14 "Reserved" 15 "Invalid" ;
VAL_ 2307022849 EMS_Crc5Val 65535 "Signal Invalid (Message with unused CRC. CRC signal is transmitted fixed value)" ;
VAL_ 2307022849 EMS_AlvCnt5Val 255 "Signal Invalid (Message with unused Alive counter. Alive counter signal is transmitted fixed value)" ;
VAL_ 2307022849 ENG_ImmoLmpSta 0 "Immobilizer lamp OFF" 1 "Immobilizer lamp ON" ;
VAL_ 2307022849 ENG_MilSta 0 "Check Engine lamp OFF" 1 "Check Engine lamp ON" ;
VAL_ 2307022849 ENG_ImmoSta 0 "Immobilizer active" 1 "Immobilizer passive" ;
VAL_ 2307022849 OBD_RbmInhbtSta 0 "Enable of standardized vehicle operation and all numerators/denominators for RBM" 1 "Inhibition of standardized vehicle operation and all numerators/denominators for RMB" ;
VAL_ 2307022849 ENG_AtmsphPrsrVal 28 "Error indicator" ;
VAL_ 2307022849 ENG_AltFdbckLoadVal 255 "Error indicator" ;
VAL_ 2307022849 ENG_BattVoltVal 255 "Error indicator" ;
VAL_ 2307022849 ENG_FuelTempVal 255 "Error indicator" ;
VAL_ 2307022850 SCC_DrvOvrRidSta 0 "No Driver Override" 1 "Driver Override" ;
VAL_ 2307022850 ISA_IsaFuncSta 0 "ISA function is not active" 1 "ISA function is active" ;
VAL_ 2307022850 SCC_StrtLimFuncSta 0 "No Start Limition Function Operation" 1 "Start Limition Function Operation" ;
VAL_ 2307022850 EMS_SafetyFunctSta 0 "No Safety Function operation" 1 "Safety Function operation" ;
VAL_ 2307022850 InAirTempVal 255 "Error indicator" ;
VAL_ 2307022850 SCC_SccFlrDetSta 0 "No Failure detected" 1 "Failure detected" ;
VAL_ 2307022850 AAF_WrnLamp 0 "Warning Lamp & Message Off" 1 "Warning Lamp & Message On" ;
VAL_ 2307022850 SCC_FuncFlrDetSta 0 "No Failure detected" 1 "Failure detected" ;
VAL_ 2307022850 SCC_SccOffStaDetSta 0 "No switch off condition detected" 1 "Switch off condition detected" ;
VAL_ 2307022850 SCC_BrkLtSwFlrDetSta 0 "No Failure detected" 1 "Failure detected" ;
VAL_ 2307022851 ENG_TransmsnTyp 0 "A/T vehicle (Step Shift A/T)" 10 "CVT vehicle (CVT A/T)" 11 "DCT vehicle (DCT A/T)" 15 "M/T vehicle" ;
VAL_ 2307022851 ENG_IsgEquipped 0 "ISG is not equipped" 1 "ISG is equipped" 2 "Reserved" 3 "Error" ;
VAL_ 2307022851 ENG_EngDsplceTyp 255 "Error indicator" ;
VAL_ 2563127553 AMP_CabinTalkVolumeStep 0 "0x0x0~0xFD:CabinTalk Volume" 253 "0x0x0~0xFD:CabinTalk Volume" 254 "Req. amp supported CabinTalk Set" 255 "Invalid" ;
VAL_ 2563127553 DATC_Beep1VolumeStep 0 "0x0x0~0xFE:DATC Beep1 Volume" 254 "0x0x0~0xFE:DATC Beep1 Volume" 255 "Invalid" ;
VAL_ 2563127553 DATC_Beep1Frequency 20 "0x0x14~0x4E20:Valid for Hz step" 20000 "0x0x14~0x4E20:Valid for Hz step" 65535 "Invalid" ;
VAL_ 2563127553 DATC_Beep1_OutputCh_Select 65535 "Invaild" ;
VAL_ 2458165761 C_HazardFromIBOX 0 "Off" 1 "On (Remote Hazard On)" ;
VAL_ 2458165761 C_RemoteWdwCMDHU 0 "None" 1 "Auto Up" 2 "Auto Down" 3 "invalid" ;
VAL_ 2458165761 C_EsyAcsProfileID_HU 0 "Default" 1 "Profile 1" 2 "Profile 2" 3 "Invalid" ;
VAL_ 2458165761 C_TeleStrgWhlHeatingCmdIBOX 0 "Off (default)" 1 "On(Remote Heating On)" 2 "Reserved" 3 "Invalid" ;
VAL_ 2458165761 C_TeleDefoggerHeatingCmdIBOX 0 "Off (default)" 1 "On(Remote Heating On)" 2 "Reserved" 3 "Invalid" ;
VAL_ 2458165761 HU_ICU_RearDefSet 0 "Defog Off" 1 "Defog On" 2 "reserved" 3 "Invalid" ;
VAL_ 2458165761 C_PanicFromIBOX 0 "Off" 1 "On (Remote Horn and Hazard On)" ;
VAL_ 2458165761 C_PreCrankReq 0 "Default" 1 "Req On" 2 "Not Support" 3 "Invalid" ;
VAL_ 2458165761 C_TeleAstSeatOpCmdIBOX 0 "Init" 1 "Unused" 2 "Seat Heat&Vent OFF" 3 "Seat_Vent_Low" 4 "Seat_Vent_Mid" 5 "Seat_Vent_High" 6 "Seat_Heat_Low" 7 "Seat_Heat_Mid" 8 "Seat_Heat_High" 9 "Unused" 10 "Unused" 11 "Unused" 12 "Unused" 13 "Unused" 14 "Unused" 15 "Invalid" ;
VAL_ 2458165761 C_TeleDrvSeatOpCmdIBOX 0 "Init" 1 "Unused" 2 "Seat Heat&Vent OFF" 3 "Seat_Vent_Low" 4 "Seat_Vent_Mid" 5 "Seat_Vent_High" 6 "Seat_Heat_Low" 7 "Seat_Heat_Mid" 8 "Seat_Heat_High" 9 "Unused" 10 "Unused" 11 "Unused" 12 "Unused" 13 "Unused" 14 "Unused" 15 "Invalid" ;
VAL_ 2458165761 C_TeleRRSeatOpCmdIBOX 0 "Init" 1 "Unused" 2 "Seat Heat&Vent OFF" 3 "Seat_Vent_Low" 4 "Seat_Vent_Mid" 5 "Seat_Vent_High" 6 "Seat_Heat_Low" 7 "Seat_Heat_Mid" 8 "Seat_Heat_High" 9 "Unused" 10 "Unused" 11 "Unused" 12 "Unused" 13 "Unused" 14 "Unused" 15 "Invalid" ;
VAL_ 2458165761 C_TeleRLSeatOpCmdIBOX 0 "Init" 1 "Unused" 2 "Seat Heat&Vent OFF" 3 "Seat_Vent_Low" 4 "Seat_Vent_Mid" 5 "Seat_Vent_High" 6 "Seat_Heat_Low" 7 "Seat_Heat_Mid" 8 "Seat_Heat_High" 9 "Unused" 10 "Unused" 11 "Unused" 12 "Unused" 13 "Unused" 14 "Unused" 15 "Invalid" ;
VAL_ 2458165761 C_HazardFromCCS 0 "Off" 1 "On (Remote Hazard On)" 2 "Reserved" 3 "Invalid" ;
VAL_ 2458165761 C_CtrlDrUnlockRlyIBOX 0 "0ff" 1 "On (Remote Unlock Command)" ;
VAL_ 2458165761 C_PanicFromCCS 0 "Off" 1 "On (Remote Horn and Hazard On)" 2 "Reserved" 3 "Invalid" ;
VAL_ 2458165761 C_CtrlDrUnlockRlyCCS 0 "0ff" 1 "On (Remote Unlock Command)" 2 "Reserved" 3 "Invalid" ;
VAL_ 2458165761 C_CtrlDrLockRlyCCS 0 "Off (default)" 1 "On (remote Lock Command)" 2 "Reserved" 3 "Invalid" ;
VAL_ 2458165761 C_CtrlDrLockRlyIBOX 0 "Off (default)" 1 "On (remote Lock Command)" ;
VAL_ 2458165761 C_TeleHeatingCmdIBOX 0 "Off (default)" 1 "On(Remote Heating On)" 2 "Reserved" 3 "Invalid" ;
VAL_ 2479160833 HU_Type 0 "RESERVED" 1 "RESERVED" 2 "RESERVED" 3 "RESERVED" 4 "RESERVED" 5 "RESERVED" 6 "RESERVED" 7 "RESERVED" 8 "RESERVED" 9 "RESERVED" 10 "RESERVED" 11 "RESERVED" 12 "RESERVED" 13 "RESERVED" 14 "RESERVED" 15 "RESERVED" 16 "AVN(Tuner DVD KOR)" 17 "AVN(Tuner DVD EUR)" 18 "AVN(Tuner DVD China)" 19 "AVN(Tuner DVD Japan)" 20 "AVN(Tuner DVD EUR)" 21 "AVN(Tuner CDP KOR)" 22 "AVN(Tuner CDP EUR)" 23 "AVN(Tuner CDP China)" 24 "AVN(Tuner CDP Japan)" 25 "AVN(Tuner CDP EUR)" 26 "RESERVED" 27 "RESERVED" 28 "RESERVED" 29 "RESERVED" 30 "RESERVED" 31 "RESERVED" 32 "AVNT (Open)" 33 "AVNT (Not open)" 34 "RESERVED" 35 "RESERVED" 36 "RESERVED" 37 "RESERVED" 38 "RESERVED" 39 "RESERVED" 40 "RESERVED" 41 "RESERVED" 42 "RESERVED" 43 "RESERVED" 44 "RESERVED" 45 "RESERVED" 46 "RESERVED" 47 "RESERVED" 48 "Economic Audio" 49 "RESERVED" 50 "RESERVED" 51 "RESERVED" 52 "RESERVED" 53 "RESERVED" 54 "RESERVED" 55 "RESERVED" 56 "RESERVED" 57 "RESERVED" 58 "RESERVED" 59 "RESERVED" 60 "RESERVED" 61 "RESERVED" 62 "RESERVED" 63 "RESERVED" 64 "Standard Audio (3.0 below)" 65 "Standard Audio 4.0" 66 "STD Audio-3.0Below,No interwork" 67 "Audio 4.0 Value" 68 "RESERVED" 69 "RESERVED" 70 "RESERVED" 71 "RESERVED" 72 "RESERVED" 73 "RESERVED" 74 "RESERVED" 75 "RESERVED" 76 "RESERVED" 77 "RESERVED" 78 "RESERVED" 79 "RESERVED" 80 "AV(Tuner DVD KOR)" 81 "AV(Tuner DVD EUR)" 82 "AV(Tuner DVD China)" 83 "AV(Tuner DVD Japan)" 84 "AV(Tuner DVD EUR)" 85 "AV(Tuner CDP KOR)" 86 "AV(Tuner CDP EUR)" 87 "AV(Tuner CDP China)" 88 "AV(Tuner CDP Japan)" 89 "AV(Tuner CDP EUR)" 90 "RESERVED" 91 "RESERVED" 92 "RESERVED" 93 "RESERVED" 94 "RESERVED" 95 "RESERVED" 96 "AVN 4.0" 97 "Premium AVN2.0" 98 "EU AVN 2.0" 99 "Super Premium w Navi" 100 "Super Premium w_o Navi" 101 "Premium w Navi" 102 "Premium w_o Navi" 103 "Display Audio w_o Navi" 104 "Integrated AVN 1.0 Mobis" 105 "Gen5 Standard Nav Wide" 106 "RESERVED" 107 "RESERVED" 108 "RESERVED" 109 "RESERVED" 110 "RESERVED" 111 "RESERVED" 112 "Compact AVN & Integrated AVN 1.0 LG" 113 "Standard-class Gen6 Navigation" 114 "RESERVED" 115 "RESERVED" 116 "RESERVED" 117 "RESERVED" 118 "RESERVED" 119 "RESERVED" 120 "RESERVED" 121 "RESERVED" 122 "RESERVED" 123 "RESERVED" 124 "RESERVED" 125 "RESERVED" 126 "RESERVED" 127 "RESERVED" 128 "Premium Navi 5th Gen(w_Navi)" 129 "Premium Navi 5th Gen(w_o Navi)" 130 "Premium Navi 6th Gen(w_Navi)" 131 "Premium Navi 6th Gen(w_o Navi)" 132 "ccNC(w Navi)" 133 "ccNC(w_o Navi)" 134 "ccIC(w Navi)" 135 "ccIC(w_o Navi)" 136 "RESERVED" 137 "RESERVED" 138 "RESERVED" 139 "RESERVED" 140 "RESERVED" 141 "RESERVED" 142 "RESERVED" 143 "RESERVED" 144 "RESERVED" 145 "RESERVED" 146 "RESERVED" 147 "RESERVED" 148 "RESERVED" 149 "RESERVED" 150 "RESERVED" 151 "RESERVED" 152 "RESERVED" 153 "RESERVED" 154 "RESERVED" 155 "RESERVED" 156 "RESERVED" 157 "RESERVED" 158 "RESERVED" 159 "RESERVED" 160 "RESERVED" 161 "RESERVED" 162 "RESERVED" 163 "RESERVED" 164 "RESERVED" 165 "RESERVED" 166 "RESERVED" 167 "RESERVED" 168 "RESERVED" 169 "RESERVED" 170 "RESERVED" 171 "RESERVED" 172 "RESERVED" 173 "RESERVED" 174 "RESERVED" 175 "RESERVED" 176 "RESERVED" 177 "RESERVED" 178 "RESERVED" 179 "RESERVED" 180 "RESERVED" 181 "RESERVED" 182 "RESERVED" 183 "RESERVED" 184 "RESERVED" 185 "RESERVED" 186 "RESERVED" 187 "RESERVED" 188 "RESERVED" 189 "RESERVED" 190 "RESERVED" 191 "RESERVED" 192 "RESERVED" 193 "RESERVED" 194 "RESERVED" 195 "RESERVED" 196 "RESERVED" 197 "RESERVED" 198 "RESERVED" 199 "RESERVED" 200 "RESERVED" 201 "RESERVED" 202 "RESERVED" 203 "RESERVED" 204 "RESERVED" 205 "RESERVED" 206 "RESERVED" 207 "RESERVED" 208 "RESERVED" 209 "RESERVED" 210 "RESERVED" 211 "RESERVED" 212 "RESERVED" 213 "RESERVED" 214 "RESERVED" 215 "RESERVED" 216 "RESERVED" 217 "RESERVED" 218 "RESERVED" 219 "RESERVED" 220 "RESERVED" 221 "RESERVED" 222 "RESERVED" 223 "RESERVED" 224 "RESERVED" 225 "RESERVED" 226 "RESERVED" 227 "RESERVED" 228 "RESERVED" 229 "RESERVED" 230 "RESERVED" 231 "RESERVED" 232 "RESERVED" 233 "RESERVED" 234 "RESERVED" 235 "RESERVED" 236 "RESERVED" 237 "RESERVED" 238 "India PIO w_o CLU interface" 239 "India PIO w_CLU interface" 240 "RESERVED" 241 "Gen 1 China OEM Navigation" 242 "RESERVED" 243 "RESERVED" 244 "RESERVED" 245 "RESERVED" 246 "RESERVED" 247 "RESERVED" 248 "RESERVED" 249 "RESERVED" 250 "PIO AVN" 251 "China  Local OEM Display Audio" 252 "China OPIO w_o CLU interface" 253 "China OPIO w_CLU interface" 254 "China Local OEM AVNT" 255 "Invalid" ;
VAL_ 2479160833 HU_DistributeInfo 0 "Default (Korea)" 1 "Korea" 2 "North America" 3 "Canada" 4 "East Europe" 5 "West Europe" 6 "China" 7 "India" 8 "Australia" 9 "Middle East" 10 "Africa" 11 "South America" 12 "Russia" 13 "Reserved" 14 "General" 15 "0x0F~0xFE:Reserved" 254 "0x0F~0xFE:Reserved" 255 "Invalid" ;
VAL_ 2479160833 HU_OptionInfo 0 "0x0x0000~0x01FF:Bit allocation" 511 "0x0x0000~0x01FF:Bit allocation" 512 "0x0200~0x7FFF:RESERVED" 32767 "0x0200~0x7FFF:RESERVED" 32768 "Invalid" 32769 "0x8001~0xFFFF:Not used" 65535 "0x8001~0xFFFF:Not used" ;
VAL_ 2479160833 HU_CamViewDispStatus 0 "Default(Camera View not displayed)" 1 "Camera View displayed" 2 "Reserved" 3 "Invalid" ;
VAL_ 2479160833 HU_NaviHandshakingSupport 0 "Not Support" 1 "Support" 2 "Unknown" 3 "Invalid" ;
VAL_ 2479160833 HU_AMP_EQVariant 0 "Default" 1 "WGN" 2 "WGN PHEV" 3 "5DR" 4 "SB" 5 "CUV" 6 "Reserved" 7 "Reserved" 8 "Reserved" 9 "Reserved" 10 "Reserved" 11 "Reserved" 12 "Reserved" 13 "Reserved" 14 "Reserved" 15 "Reserved" 16 "Reserved" 17 "Reserved" 18 "Reserved" 19 "Reserved" 20 "Reserved" 21 "Reserved" 22 "Reserved" 23 "Reserved" 24 "Reserved" 25 "Reserved" 26 "Reserved" 27 "Reserved" 28 "Reserved" 29 "Reserved" 30 "Reserved" 31 "Invalid" ;
VAL_ 2479160833 HU_AdasSupport 0 "Not Support" 1 "ADAS Support(General Map)" 2 "ADAS Support(Map based ADAS v1)" 3 "ADAS Support(Map based ADAS v2)" 4 "ADAS Support(Map based ADAS v2 & Handshaking)" 5 "ADAS Support(Map based ADAS v2_3)" 6 "Reserved" 7 "Invalid" ;
VAL_ 2281833729 DMIC_DrvModSta 0 "Individual" 1 "Snow" 2 "Comfort(Normal)" 3 "Comfort+(Comfort)" 4 "ECO" 5 "Sport" 6 "Sport+" 7 "Smart" 8 "VIP" 9 "Baby" 10 "GT" 11 "Not Used" 12 "Not Used" 13 "Not Used" 14 "Not Used" 15 "Error Indicator" ;
VAL_ 2281833729 DMIC_SmtShftModSta 0 "OFF" 1 "ON" 2 "Not used" 3 "Error Indicator" ;
VAL_ 2281833729 DMIC_EngModSta 0 "0FF" 1 "ON" 2 "Comfort(Normal)" 3 "Comfort+(Comfort)" 4 "ECO" 5 "Sport" 6 "Sport+" 7 "Smart" 8 "VIP" 9 "Not used" 10 "Not used" 11 "Not used" 12 "Not used" 13 "Not used" 14 "Not used" 15 "Error Indicator" ;
VAL_ 2281833729 DMIC_IndEngModSta 0 "0FF" 1 "ON" 2 "Comfort(Normal)" 3 "Comfort+(Comfort)" 4 "ECO" 5 "Sport" 6 "Sport+" 7 "Smart" 8 "VIP" 9 "Not used" 10 "Not used" 11 "Not used" 12 "Not used" 13 "Not used" 14 "Not used" 15 "Error Indicator" ;
VAL_ 2281833729 DMIC_TmModSta 0 "0FF" 1 "ON" 2 "Comfort(Normal)" 3 "Comfort+(Comfort)" 4 "ECO" 5 "Sport" 6 "Sport+" 7 "Smart" 8 "VIP" 9 "Not used" 10 "Not used" 11 "Not used" 12 "Not used" 13 "Not used" 14 "Not used" 15 "Error Indicator" ;
VAL_ 2281833729 DMIC_EscModSta 0 "0FF" 1 "ON" 2 "Comfort(Normal)" 3 "Comfort+(Comfort)" 4 "ECO" 5 "Sport" 6 "Sport+" 7 "Smart" 8 "Not used" 9 "Not used" 10 "Not used" 11 "Not used" 12 "Not used" 13 "Not used" 14 "Not used" 15 "Error Indicator" ;
VAL_ 2281833729 DMIC_MdpsModSta 0 "0FF" 1 "ON" 2 "Comfort(Normal)" 3 "Comfort+(Comfort)" 4 "ECO" 5 "Sport" 6 "Sport+" 7 "Smart" 8 "VIP" 9 "Not used" 10 "Not used" 11 "Not used" 12 "Not used" 13 "Not used" 14 "Not used" 15 "Error Indicator" ;
VAL_ 2281833729 DMIC_IndMdpsModSta 0 "0FF" 1 "ON" 2 "Comfort(Normal)" 3 "Comfort+(Comfort)" 4 "ECO" 5 "Sport" 6 "Sport+" 7 "Smart" 8 "VIP" 9 "Not used" 10 "Not used" 11 "Not used" 12 "Not used" 13 "Not used" 14 "Not used" 15 "Error Indicator" ;
VAL_ 2281833730 DMIC_EcsModSta 0 "0FF" 1 "ON" 2 "Comfort(Normal)" 3 "Comfort+(Comfort)" 4 "ECO" 5 "Sport" 6 "Sport+" 7 "Smart" 8 "VIP" 9 "Not used" 10 "Not used" 11 "Not used" 12 "Not used" 13 "Not used" 14 "Not used" 15 "Error Indicator" ;
VAL_ 2281833730 DMIC_IndAwdModSta 0 "0FF" 1 "ON" 2 "Comfort(Normal)" 3 "Comfort+(Comfort)" 4 "ECO" 5 "Sport" 6 "Sport+" 7 "Smart" 8 "Not used" 9 "Not used" 10 "Not used" 11 "Not used" 12 "Not used" 13 "Not used" 14 "Not used" 15 "Error Indicator" ;
VAL_ 2281833730 DMIC_IndEcsModSta 0 "0FF" 1 "ON" 2 "Comfort(Normal)" 3 "Comfort+(Comfort)" 4 "ECO" 5 "Sport" 6 "Sport+" 7 "Smart" 8 "VIP" 9 "Not used" 10 "Not used" 11 "Not used" 12 "Not used" 13 "Not used" 14 "Not used" 15 "Error Indicator" ;
VAL_ 2281833730 DMIC_IndRwsModSta 0 "0FF" 1 "ON" 2 "Comfort(Normal)" 3 "Comfort+(Comfort)" 4 "ECO" 5 "Sport" 6 "Sport+" 7 "Smart" 8 "Not used" 9 "Not used" 10 "Not used" 11 "Not used" 12 "Not used" 13 "Not used" 14 "Not used" 15 "Error Indicator" ;
VAL_ 2281833730 DMIC_IndBrkModSta 0 "0FF" 1 "ON" 2 "Comfort(Normal)" 3 "Comfort+(Comfort)" 4 "ECO" 5 "Sport" 6 "Sport+" 7 "Smart" 8 "Not used" 9 "Not used" 10 "Not used" 11 "Not used" 12 "Not used" 13 "Not used" 14 "Not used" 15 "Error Indicator" ;
VAL_ 2281833730 DMIC_AwdModSta 0 "0FF" 1 "ON" 2 "Comfort(Normal)" 3 "Comfort+(Comfort)" 4 "ECO" 5 "Sport" 6 "Sport+" 7 "Smart" 8 "Not used" 9 "Not used" 10 "Not used" 11 "Not used" 12 "Not used" 13 "Not used" 14 "Not used" 15 "Error Indicator" ;
VAL_ 2281833731 DMIC_DrvModTyp 0 "Drive Mode Case0" 1 "Drive Mode Case1" 2 "Drive Mode Case2" 3 "Drive Mode Case3" 4 "Drive Mode Case4" 5 "Drive Mode Case5" 6 "Drive Mode Case6" 7 "Drive Mode Case7" 8 "Drive Mode Case8" 9 "Drive Mode Case9" 10 "Drive Mode Case10" 11 "Drive Mode Case11" 12 "Drive Mode Case12" 13 "Drive Mode Case13" 14 "Drive Mode Case14" 15 "Drive Mode Case15" ;
VAL_ 2281833731 DMIC_EngFltSta 0 "Not defective" 1 "Defective" 2 "Not used" 3 "Error Indicator" ;
VAL_ 2281833731 DMIC_MdpsFltSta 0 "Not defective" 1 "Defective" 2 "Not used" 3 "Error Indicator" ;
VAL_ 2281833731 DMIC_EcsFltSta 0 "Not defective" 1 "Defective" 2 "Not used" 3 "Error Indicator" ;
VAL_ 2281833731 DMIC_AwdFltSta 0 "Not defective" 1 "Defective" 2 "Not used" 3 "Error Indicator" ;
VAL_ 2281833731 DMIC_RwsFltSta 0 "Not defective" 1 "Defective" 2 "Not used" 3 "Error Indicator" ;
VAL_ 2281833731 DMIC_BrkFltSta 0 "Not defective" 1 "Defective" 2 "Not used" 3 "Error Indicator" ;
VAL_ 2281833731 DMIC_DrvModFltSta 0 "All mode available" 1 "Sport mode unavailable" 2 "ECO mode and Sport mode unavailable" 3 "Comfort(Normal) mode only available (The other modes unavailable)" 4 "Not used" 5 "Not used" 6 "Not used" 7 "Not used" 8 "Not used" 9 "Not used" 10 "Not used" 11 "Not used" 12 "Not used" 13 "Not used" 14 "Not used" 15 "Error Indicator" ;
VAL_ 1041 Autocut_DlvryModSta 0 "Before Delivery(Welcome Off)" 1 "After Delivery(Welcome On)" 2 "Not Used" 3 "Error Indicator" ;
VAL_ 1041 Warn_AsstStBltSwSta 0 "Unbelted" 1 "Belted" 2 "Not Used" 3 "Error Indicator" ;
VAL_ 1041 Warn_BrkFldSwSta 0 "Off" 1 "On" 2 "Not Used" 3 "Error Indicator" ;
VAL_ 1041 Warn_DrvStBltSwSta 0 "Unbelted" 1 "Belted" 2 "Not Used" 3 "Error Indicator" ;
VAL_ 1041 Warn_HoodSwSta 0 "Off" 1 "On" 2 "Not Used" 3 "Error Indicator" ;
VAL_ 1041 Warn_PassStOccSta 0 "Off (UnSeated)" 1 "On (Seated)" 2 "Not Used" 3 "Error Indicator" ;
VAL_ 1041 Warn_RrCtrStBltSwSta 0 "Unbelted" 1 "Belted" 2 "Not Used" 3 "Error Indicator" ;
VAL_ 1041 Warn_RrLftStBltSwSta 0 "Unbelted" 1 "Belted" 2 "Not Used" 3 "Error Indicator" ;
VAL_ 1041 Warn_RrRtStBltSwSta 0 "Unbelted" 1 "Belted" 2 "Not Used" 3 "Error Indicator" ;
VAL_ 1041 Warn_HoodSwMemorySta 0 "No event" 1 "hood_open_close" 2 "reserved" 3 "reserved" ;
VAL_ 1041 Warn_WshrFldSwSta 0 "Off" 1 "On" ;
VAL_ 1042 Warn_DrvStOccSta 0 "UnSeated" 1 "Seated" 2 "Reserved" 3 "Reserved" 4 "Reserved" 5 "Fault 1 (Cable Cut-off)" 6 "Fault 2 (Cable Short)" 7 "Error Indicator" ;
VAL_ 1042 ExtLamp_BckUpLmpSta 0 "Off" 1 "On" 2 "Not Used" 3 "Error Indicator" ;
VAL_ 1042 ExtLamp_StpLmpSta 0 "Off" 1 "On" 2 "Not Used" 3 "Error Indicator" ;
VAL_ 1042 OTAModeACCOffReq 0 "Default" 1 "Off(ACC Off Request)" 2 "Reserved" 3 "Reserved" ;
VAL_ 1042 C_ICUIGNOffReq 0 "Default" 1 "Off(IGN Off Request)" 2 "Reserved" 3 "Reserved" ;
VAL_ 1043 Lamp_TrnSigLmpRtActiveSt 0 "Off (Inactive)" 1 "On (Active)" 2 "Reserved" 3 "Invalid" ;
VAL_ 1043 ExtLamp_TrnSigLmpLftBlnkngSta 0 "Off" 1 "On" 2 "Not Used" 3 "Error Indicator" ;
VAL_ 1043 ExtLamp_TrnSigLmpRtBlnkngSta 0 "Off" 1 "On" 2 "Not Used" 3 "Error Indicator" ;
VAL_ 1043 ExtLamp_ExtrnlTailLmpSta 0 "Off" 1 "On" 2 "Not Used" 3 "Error Indicator" ;
VAL_ 1043 ExtLamp_HzrdSwSta 0 "Off" 1 "On" 2 "Not Used" 3 "Error Indicator" ;
VAL_ 1043 ExtLamp_RrFgLmpSta 0 "Off" 1 "On" 2 "Not Used" 3 "Error Indicator" ;
VAL_ 1043 IntLamp_InlTailLmpSta 0 "Off" 1 "On" 2 "Not Used" 3 "Error Indicator" ;
VAL_ 1043 Lamp_TrnSigLmpLftOnReq 0 "Inactive" 1 "Active Off(Flasher Off)" 2 "Active On(Flasher On)" 3 "reserved" ;
VAL_ 1043 Lamp_TrnSigLmpRtOnReq 0 "Inactive" 1 "Active Off(Flasher Off)" 2 "Active On(Flasher On)" 3 "reserved" ;
VAL_ 1043 Lamp_TrnSigLmpLftActiveSt 0 "Off (Inactive)" 1 "On (Active)" 2 "Reserved" 3 "Invalid" ;
VAL_ 1044 Trunk_TrnkInReleaseSwSta 0 "Off" 1 "On" 2 "Not Used" 3 "Error Indicator" ;
VAL_ 1044 Trunk_TrnkTlgtOutReleaseSwSta 0 "Off" 1 "On" 2 "Not Used" 3 "Error Indicator" ;
VAL_ 1044 Trunk_TrnkTlgtSwSta 0 "Close(Full Lock)" 1 "Open(Not Full Lock)" 2 "Not Used" 3 "Error Indicator" ;
VAL_ 1044 Trunk_GlvBxTrnkLkSwSta 0 "Off" 1 "On" 2 "Not Used" 3 "Error Indicator" ;
VAL_ 1044 Trunk_TrnkTlgtReleaseRlySta 0 "OFF" 1 "ON" 2 "Not Used" 3 "Error Indicator" ;
VAL_ 1044 USM_OneTouchTrnSigFuncSta 0 "Default" 1 "One Touch Turn Off" 2 "3 Flashing" 3 "5 Flashing" 4 "7 Flashing" 5 "Invalid" ;
VAL_ 1044 Defog_DfgrRlySta 0 "Off" 1 "On" 2 "Not Used" 3 "Error Indicator" ;
VAL_ 1046 Lamp_RrTrnSigLmpLftOpnSta 0 "Normal" 1 "Open Status" 2 "Not Used" 3 "Error Indicator" ;
VAL_ 1046 Lamp_RrTrnSigLmpRtOpnSta 0 "Normal" 1 "Open Status" 2 "Not Used" 3 "Error Indicator" ;
VAL_ 1046 Lamp_FrTrnSigLmpLftOpnSta 0 "Normal" 1 "Open Status" 2 "Not Used" 3 "Error Indicator" ;
VAL_ 1046 Lamp_FrTrnSigLmpRtOpnSta 0 "Normal" 1 "Open Status" 2 "Not Used" 3 "Error Indicator" ;
VAL_ 1040 BmsFailWarning 0 "Normal(Default)" 1 "1st warning" 2 "2nd warning" ;
VAL_ 1040 ICU_BS2_FSOC 0 "valid" 1 "invalid" ;
VAL_ 1040 ICU_BS2_FSOH 0 "valid" 1 "invalid" ;
VAL_ 1040 ICU_BS2_FSOF 0 "valid" 1 "invalid" ;
VAL_ 1040 ICU_BS2_FQSTAT 0 "valid" 1 "invalid" ;
VAL_ 579 OHCL_Opt 0 "None option" 1 "Enable" ;
VAL_ 579 OHCL_Sys_sta 0 "Normal" 1 "Not Used" 2 "Not Used" 3 "System Fail" ;
VAL_ 579 OHCL_DoorOn_Sta 0 "Off" 1 "On" 2 "Not Used" 3 "System Fail" ;
VAL_ 579 OHCL_RrMapLftOn_Sta 0 "Off" 1 "On" 2 "Not Used" 3 "System Fail" ;
VAL_ 579 OHCL_RrMapRtOn_Sta 0 "Off" 1 "On" 2 "Not Used" 3 "System Fail" ;
VAL_ 579 OHCL_RrRoomOn_Sta 0 "Off" 1 "On" 2 "Not Used" 3 "System Fail" ;
VAL_ 579 OHCL_RrMoodOn_Sta 0 "Off" 1 "On" 2 "Not Used" 3 "System Fail" ;
VAL_ 579 OHCL_LEDClr_Sta 0 "Color 1Step" 1 "Color 2Step" 2 "Color 3Step" 3 "Not Used" 4 "Not Used" 5 "Not Used" 6 "Not Used" 7 "System Fail" ;
VAL_ 579 OHCL_LEDBgtns_Sta 0 "Brightness 1Step" 1 "Brightness 2Step" 2 "Brightness 3Step" 3 "Not Used" 4 "Not Used" 5 "Not Used" 6 "Not Used" 7 "System Fail" ;
VAL_ 579 OHCL_TllTlLmpSta 0 "ON Lamp off OFF Lamp off" 1 "ON Lamp off OFF Lamp on" 2 "ON Lamp on OFF Lamp off" 3 "ON Lamp on OFF Lamp on" 4 "ACU message error" 5 "Reserved" 6 "Reserved" 7 "Lamp circuit failure" ;
VAL_ 579 OHCL_FrMapLftOn_Sta 0 "Off" 1 "On" 2 "Not Used" 3 "System Fail" ;
VAL_ 579 OHCL_FrMapRtOn_Sta 0 "Off" 1 "On" 2 "Not Used" 3 "System Fail" ;
VAL_ 579 OHCL_FrRoomOn_Sta 0 "Off" 1 "On" 2 "Not Used" 3 "System Fail" ;
VAL_ 579 OHCL_FrMoodOn_Sta 0 "Off" 1 "On" 2 "Not Used" 3 "System Fail" ;
VAL_ 1067 HWSW_SysSta 0 "Normal" 1 "System Fail" 2 "reserved" 3 "Invalid" ;
VAL_ 1067 USM_CmdSta 0 "Default" 1 "Steering Off" 2 "Steering On" 3 "Invalid" ;
VAL_ 1067 SCM_HptWrngUSMSta 0 "Default" 1 "WEAK" 2 "MEDIUM" 3 "STRONG" 4 "Reserved" 5 "Reserved" 6 "OFF" 7 "Invalid" ;
VAL_ 1067 SCM_Haptic_OPT 0 "Default" 1 "No Option (None Haptic Option)" 2 "Option" 3 "Invalid" ;
VAL_ 1067 SCM_TeleMvmntVal 0 "0~10" 1 "11~20" 16 "161~170" 17 "171~180" 18 "181~190" 19 "191~200" 20 "201~210" 21 "211~220" 22 "221~230" 23 "231~240" 24 "241~250" 25 "251~260" 26 "261~270" 27 "271~280" 28 "281~290" 29 "291~300" 30 "300~" 31 "invalid" 2 "21~30" 3 "31~40" 4 "41~50" 5 "51~60" 6 "61~70" 7 "71~80" 8 "81~90" 9 "91~100" 10 "101~110" 11 "111~120" 12 "121~130" 13 "131~140" 14 "141~150" 15 "151~160" ;
VAL_ 1067 SCM_TiltMvmntVal 0 "0~10" 1 "11~20" 16 "161~170" 17 "171~180" 18 "181~190" 19 "191~200" 20 "201~210" 21 "211~220" 22 "221~230" 23 "231~240" 24 "241~250" 25 "251~" 26 "Reserved" 27 "Reserved" 28 "Reserved" 29 "Reserved" 30 "Reserved" 31 "Invalid" 2 "21~30" 3 "31~40" 4 "41~50" 5 "51~60" 6 "61~70" 7 "71~80" 8 "81~90" 9 "91~100" 10 "101~110" 11 "111~120" 12 "121~130" 13 "131~140" 14 "141~150" 15 "151~160" ;
VAL_ 1067 SCM_PlyBckSta 0 "Stop" 1 "Play 1" 2 "Play 2" 3 "Health Care IMS" 4 "Profile 1" 5 "Profile 2" 6 "Guest" 7 "Invalid" ;
VAL_ 1067 SCM_SWVerMajor1 0 "0x0x0~0x7F:ASCII Code Value (HEX)" 127 "0x0x0~0x7F:ASCII Code Value (HEX)" ;
VAL_ 1067 SCM_SWVerMinor1 0 "0x0x0~0x7F:ASCII Code Value (HEX)" 127 "0x0x0~0x7F:ASCII Code Value (HEX)" ;
VAL_ 1067 SCM_SWVerMinor2 0 "0x0x0~0x7F:ASCII Code Value (HEX)" 127 "0x0x0~0x7F:ASCII Code Value (HEX)" ;
